VERSION ""

NS_ :

BS_:

BU_: WPC2 PSB SHVU_RR vHS_B2 FCS EMCU SLB GW_APSU GW_DLBCU RCM ARS CGW_CCU vDummy_HS_B GW_RLPSU ATS RLHV SGU PFSU GW_RRPSU ALBCU DSAU SWRC SHVU_FR RCS GW_DPSU BLTN_CAM SCM OHCL RWPC RRHV WPC HOD ASAU

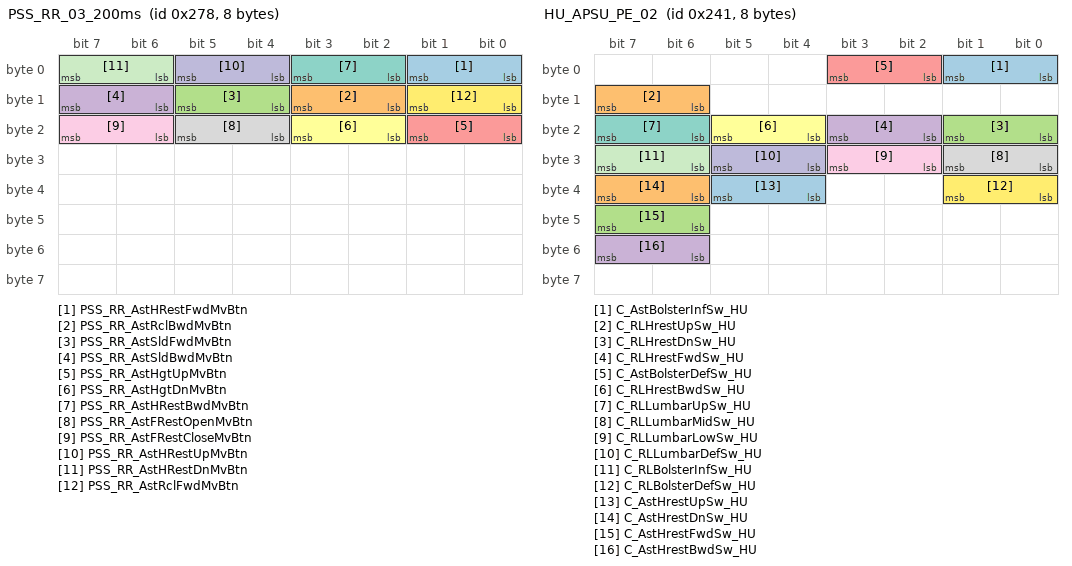
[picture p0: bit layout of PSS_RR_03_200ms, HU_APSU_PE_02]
BO_ 632 PSS_RR_03_200ms: 8 GW_RRPSU
 SG_ PSS_RR_AstHRestFwdMvBtn : 0|2@1+ (1,0) [0|0] ""  CGW_CCU
 SG_ PSS_RR_AstRclBwdMvBtn : 10|2@1+ (1,0) [0|0] ""  CGW_CCU
 SG_ PSS_RR_AstSldFwdMvBtn : 12|2@1+ (1,0) [0|0] ""  CGW_CCU
 SG_ PSS_RR_AstSldBwdMvBtn : 14|2@1+ (1,0) [0|0] ""  CGW_CCU
 SG_ PSS_RR_AstHgtUpMvBtn : 16|2@1+ (1,0) [0|0] ""  CGW_CCU
 SG_ PSS_RR_AstHgtDnMvBtn : 18|2@1+ (1,0) [0|0] ""  CGW_CCU
 SG_ PSS_RR_AstHRestBwdMvBtn : 2|2@1+ (1,0) [0|0] ""  CGW_CCU
 SG_ PSS_RR_AstFRestOpenMvBtn : 20|2@1+ (1,0) [0|0] ""  CGW_CCU
 SG_ PSS_RR_AstFRestCloseMvBtn : 22|2@1+ (1,0) [0|0] ""  CGW_CCU
 SG_ PSS_RR_AstHRestUpMvBtn : 4|2@1+ (1,0) [0|0] ""  CGW_CCU
 SG_ PSS_RR_AstHRestDnMvBtn : 6|2@1+ (1,0) [0|0] ""  CGW_CCU
 SG_ PSS_RR_AstRclFwdMvBtn : 8|2@1+ (1,0) [0|0] ""  CGW_CCU

BO_ 639 ATS_04_00ms: 8 ATS
 SG_ ATS_RRSeatHeaterSW : 0|2@1+ (1,0) [0|0] ""  RRHV,SHVU_RR
 SG_ ATS_RLSeatHeaterUpSW : 10|2@1+ (1,0) [0|0] ""  RLHV,SHVU_RR
 SG_ ATS_RRSeatVentDownSW : 12|2@1+ (1,0) [0|0] ""  RRHV,SHVU_RR
 SG_ ATS_RLSeatVentDownSW : 14|2@1+ (1,0) [0|0] ""  RLHV,SHVU_RR
 SG_ ATS_RLMemoryRestBtn : 16|2@1+ (1,0) [0|0] ""  Vector__XXX
 SG_ ATS_RLMemoryReturnBtn : 18|2@1+ (1,0) [0|0] ""  Vector__XXX
 SG_ ATS_RLSeatHeaterSW : 2|2@1+ (1,0) [0|0] ""  RLHV,SHVU_RR
 SG_ ATS_RRMemoryRestBtn : 20|2@1+ (1,0) [0|0] ""  Vector__XXX
 SG_ ATS_RRMemoryReturnBtn : 22|2@1+ (1,0) [0|0] ""  Vector__XXX
 SG_ ATS_RRMemoryAvWtcBtn : 24|2@1+ (1,0) [0|0] ""  Vector__XXX
 SG_ ATS_RRMemoryReadingBtn : 26|2@1+ (1,0) [0|0] ""  Vector__XXX
 SG_ ATS_RRRestModBtnSTD : 32|2@1+ (1,0) [0|0] ""  Vector__XXX
 SG_ ATS_RRResetModBtnSTD : 34|2@1+ (1,0) [0|0] ""  Vector__XXX
 SG_ ATS_RRAvWtcModBtnSTD : 36|2@1+ (1,0) [0|0] ""  Vector__XXX
 SG_ ATS_RRReadingModBtnSTD : 38|2@1+ (1,0) [0|0] ""  Vector__XXX
 SG_ ATS_RRSeatVentSW : 4|2@1+ (1,0) [0|0] ""  RRHV,SHVU_RR
 SG_ ATS_RLRestModBtnSTD : 40|2@1+ (1,0) [0|0] ""  Vector__XXX
 SG_ ATS_RLResetModBtnSTD : 42|2@1+ (1,0) [0|0] ""  Vector__XXX
 SG_ ATS_RRModestateStopBtn : 44|2@1+ (1,0) [0|0] ""  Vector__XXX
 SG_ ATS_RLModestateStopBtn : 46|2@1+ (1,0) [0|0] ""  Vector__XXX
 SG_ ATS_RLResetRestBtn : 48|2@1+ (1,0) [0|0] ""  Vector__XXX
 SG_ ATS_RLResetReturnBtn : 50|2@1+ (1,0) [0|0] ""  Vector__XXX
 SG_ ATS_RRResetRestBtn : 52|2@1+ (1,0) [0|0] ""  Vector__XXX
 SG_ ATS_RRResetReturnBtn : 54|2@1+ (1,0) [0|0] ""  Vector__XXX
 SG_ ATS_RRResetAvWtcBtn : 56|2@1+ (1,0) [0|0] ""  Vector__XXX
 SG_ ATS_RRResetReadingBtn : 58|2@1+ (1,0) [0|0] ""  Vector__XXX
 SG_ ATS_RLSeatVentSW : 6|2@1+ (1,0) [0|0] ""  RLHV,SHVU_RR
 SG_ ATS_RRSeatHeaterUpSW : 8|2@1+ (1,0) [0|0] ""  RRHV,SHVU_RR

BO_ 1584 HU_AMP_E_01: 8 CGW_CCU
 SG_ AMP_NaviWarnSound : 0|2@1+ (1,0) [0|0] ""  Vector__XXX
 SG_ AMP_Beep1Mode : 14|2@1+ (1,0) [0|0] ""  ATS
 SG_ AMP_MasterBeepVolumeStep : 16|3@1+ (1,0) [0|0] ""  Vector__XXX
 SG_ AMP_RrTTSSound : 2|2@1+ (1,0) [0|0] ""  Vector__XXX
 SG_ AMP_ASDMode : 21|3@1+ (1,0) [0|0] ""  Vector__XXX
 SG_ AMP_ANCMode : 25|2@1+ (1,0) [0|0] ""  Vector__XXX
 SG_ AMP_VirtualVenueMode : 32|3@1+ (1,0) [0|0] ""  Vector__XXX
 SG_ AMP_QLIMode : 35|3@1+ (1,0) [0|0] ""  Vector__XXX
 SG_ AMP_DriverMode : 38|2@1+ (1,0) [0|0] ""  Vector__XXX
 SG_ AMP_NaviSound : 4|2@1+ (1,0) [0|0] ""  Vector__XXX
 SG_ AMP_ETCSSound : 42|2@1+ (1,0) [0|0] ""  Vector__XXX
 SG_ AMP_VoiceGuideTTS : 44|2@1+ (1,0) [0|0] ""  Vector__XXX
 SG_ AMP_Beep1KBDMode : 46|2@1+ (1,0) [0|0] ""  Vector__XXX
 SG_ AMP_ETCSVolumeStep : 48|8@1+ (1,0) [0|0] ""  Vector__XXX
 SG_ AMP_NaviWarnVolumeStep : 56|8@1+ (1,0) [0|0] ""  Vector__XXX
 SG_ AMP_TTSSound : 6|2@1+ (1,0) [0|0] ""  Vector__XXX
 SG_ AMP_SDVCStep : 9|3@1+ (1,0) [0|0] ""  Vector__XXX

BO_ 577 HU_APSU_PE_02: 8 CGW_CCU
 SG_ C_AstBolsterInfSw_HU : 0|2@1+ (1,0) [0|0] ""  ALBCU,ASAU,GW_APSU
 SG_ C_RLHrestUpSw_HU : 14|2@1+ (1,0) [0|0] ""  GW_APSU,GW_RLPSU
 SG_ C_RLHrestDnSw_HU : 16|2@1+ (1,0) [0|0] ""  GW_APSU,GW_RLPSU
 SG_ C_RLHrestFwdSw_HU : 18|2@1+ (1,0) [0|0] ""  GW_APSU,GW_RLPSU
 SG_ C_AstBolsterDefSw_HU : 2|2@1+ (1,0) [0|0] ""  ALBCU,ASAU,GW_APSU
 SG_ C_RLHrestBwdSw_HU : 20|2@1+ (1,0) [0|0] ""  GW_APSU,GW_RLPSU
 SG_ C_RLLumbarUpSw_HU : 22|2@1+ (1,0) [0|0] ""  GW_RLPSU
 SG_ C_RLLumbarMidSw_HU : 24|2@1+ (1,0) [0|0] ""  GW_RLPSU
 SG_ C_RLLumbarLowSw_HU : 26|2@1+ (1,0) [0|0] ""  GW_RLPSU
 SG_ C_RLLumbarDefSw_HU : 28|2@1+ (1,0) [0|0] ""  GW_RLPSU
 SG_ C_RLBolsterInfSw_HU : 30|2@1+ (1,0) [0|0] ""  GW_RLPSU
 SG_ C_RLBolsterDefSw_HU : 32|2@1+ (1,0) [0|0] ""  GW_RLPSU
 SG_ C_AstHrestUpSw_HU : 36|2@1+ (1,0) [0|0] ""  GW_APSU
 SG_ C_AstHrestDnSw_HU : 38|2@1+ (1,0) [0|0] ""  GW_APSU
 SG_ C_AstHrestFwdSw_HU : 46|2@1+ (1,0) [0|0] ""  GW_APSU
 SG_ C_AstHrestBwdSw_HU : 54|2@1+ (1,0) [0|0] ""  GW_APSU

BO_ 578 HU_APSU_PE_03: 8 CGW_CCU
 SG_ C_RRLegSupFwdSw_HU : 0|2@1+ (1,0) [0|0] ""  GW_APSU,GW_RRPSU
 SG_ C_RRHrestDnSw_HU : 10|2@1+ (1,0) [0|0] ""  GW_APSU,GW_RRPSU
 SG_ C_RRHrestFwdSw_HU : 12|2@1+ (1,0) [0|0] ""  GW_APSU,GW_RRPSU
 SG_ C_RRHrestBwdSw_HU : 14|2@1+ (1,0) [0|0] ""  GW_APSU,GW_RRPSU
 SG_ C_RRLumbarUpSw_HU : 16|2@1+ (1,0) [0|0] ""  GW_APSU,GW_RRPSU
 SG_ C_RRLumbarMidSw_HU : 18|2@1+ (1,0) [0|0] ""  GW_APSU,GW_RRPSU
 SG_ C_RRLegSupBwdSw_HU : 2|2@1+ (1,0) [0|0] ""  GW_APSU,GW_RRPSU
 SG_ C_RRLumbarLowSw_HU : 20|2@1+ (1,0) [0|0] ""  GW_APSU,GW_RRPSU
 SG_ C_RRLumbarDefSw_HU : 22|2@1+ (1,0) [0|0] ""  GW_APSU,GW_RRPSU
 SG_ C_RRBolsterInfSw_HU : 24|2@1+ (1,0) [0|0] ""  GW_APSU,GW_RRPSU
 SG_ C_RRLegSupUpSw_HU : 4|2@1+ (1,0) [0|0] ""  GW_APSU,GW_RRPSU
 SG_ C_RROneTchNValueSet : 40|3@1+ (1,0) [0|0] ""  ATS,GW_APSU,GW_RRPSU
 SG_ C_RLOneTchNValueSet : 43|3@1+ (1,0) [0|0] ""  ATS,GW_APSU,GW_RLPSU,GW_RRPSU
 SG_ C_RRBolsterDefSw_HU : 46|2@1+ (1,0) [0|0] ""  GW_APSU,GW_RRPSU
 SG_ C_AstRlxTiltUpSw_HU : 50|2@1+ (1,0) [0|0] ""  GW_APSU
 SG_ C_AstRlxTiltDnSw_HU : 52|2@1+ (1,0) [0|0] ""  GW_APSU
 SG_ C_RLRSEUpSw_HU : 54|2@1+ (1,0) [0|0] ""  GW_APSU,GW_RLPSU
 SG_ C_RLRSEDnSw_HU : 56|2@1+ (1,0) [0|0] ""  GW_APSU,GW_RLPSU
 SG_ C_RRRSEUpSw_HU : 58|2@1+ (1,0) [0|0] ""  GW_APSU,GW_RRPSU
 SG_ C_RRLegSupDnSw_HU : 6|2@1+ (1,0) [0|0] ""  GW_APSU,GW_RRPSU
 SG_ C_RRRSEDnSw_HU : 60|2@1+ (1,0) [0|0] ""  GW_APSU,GW_RRPSU
 SG_ C_RRHrestUpSw_HU : 8|2@1+ (1,0) [0|0] ""  GW_APSU,GW_RRPSU

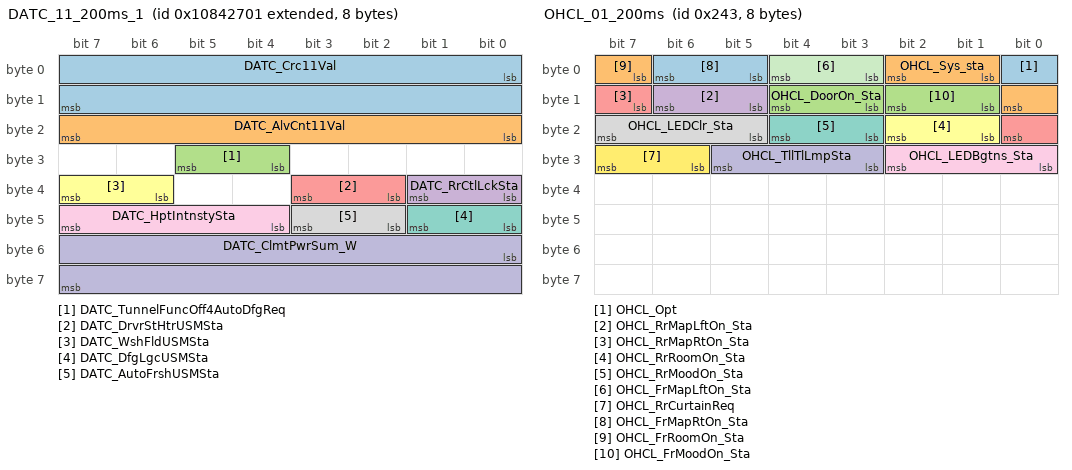
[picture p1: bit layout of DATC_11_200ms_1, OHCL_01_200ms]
BO_ 2424579841 DATC_11_200ms_1: 8 CGW_CCU
 SG_ DATC_Crc11Val : 0|16@1+ (1,0) [0|0] ""  Vector__XXX
 SG_ DATC_AlvCnt11Val : 16|8@1+ (1,0) [0|0] ""  Vector__XXX
 SG_ DATC_TunnelFuncOff4AutoDfgReq : 28|2@1+ (1,0) [0|0] ""  Vector__XXX
 SG_ DATC_RrCtlLckSta : 32|2@1+ (1,0) [0|0] ""  ATS
 SG_ DATC_DrvrStHtrUSMSta : 34|2@1+ (1,0) [0|0] ""  GW_APSU,GW_DPSU
 SG_ DATC_WshFldUSMSta : 38|2@1+ (1,0) [0|0] ""  Vector__XXX
 SG_ DATC_DfgLgcUSMSta : 40|2@1+ (1,0) [0|0] ""  Vector__XXX
 SG_ DATC_AutoFrshUSMSta : 42|2@1+ (1,0) [0|0] ""  Vector__XXX
 SG_ DATC_HptIntnstySta : 44|4@1+ (1,0) [0|0] ""  Vector__XXX
 SG_ DATC_ClmtPwrSum_W : 48|16@1+ (1,0) [0|0] "Wh"  Vector__XXX

BO_ 579 OHCL_01_200ms: 8 OHCL
 SG_ OHCL_Opt : 0|1@1+ (1,0) [0|0] ""  ATS
 SG_ OHCL_Sys_sta : 1|2@1+ (1,0) [0|0] ""  ATS
 SG_ OHCL_DoorOn_Sta : 11|2@1+ (1,0) [0|0] ""  ATS
 SG_ OHCL_RrMapLftOn_Sta : 13|2@1+ (1,0) [0|0] ""  ATS
 SG_ OHCL_RrMapRtOn_Sta : 15|2@1+ (1,0) [0|0] ""  ATS
 SG_ OHCL_RrRoomOn_Sta : 17|2@1+ (1,0) [0|0] ""  ATS
 SG_ OHCL_RrMoodOn_Sta : 19|2@1+ (1,0) [0|0] ""  ATS
 SG_ OHCL_LEDClr_Sta : 21|3@1+ (1,0) [0|0] ""  ATS
 SG_ OHCL_LEDBgtns_Sta : 24|3@1+ (1,0) [0|0] ""  ATS
 SG_ OHCL_TllTlLmpSta : 27|3@1+ (1,0) [0|0] ""  CGW_CCU
 SG_ OHCL_FrMapLftOn_Sta : 3|2@1+ (1,0) [0|0] ""  ATS
 SG_ OHCL_RrCurtainReq : 30|2@1+ (1,0) [0|0] ""  Vector__XXX
 SG_ OHCL_FrMapRtOn_Sta : 5|2@1+ (1,0) [0|0] ""  ATS
 SG_ OHCL_FrRoomOn_Sta : 7|2@1+ (1,0) [0|0] ""  ATS
 SG_ OHCL_FrMoodOn_Sta : 9|2@1+ (1,0) [0|0] ""  ATS

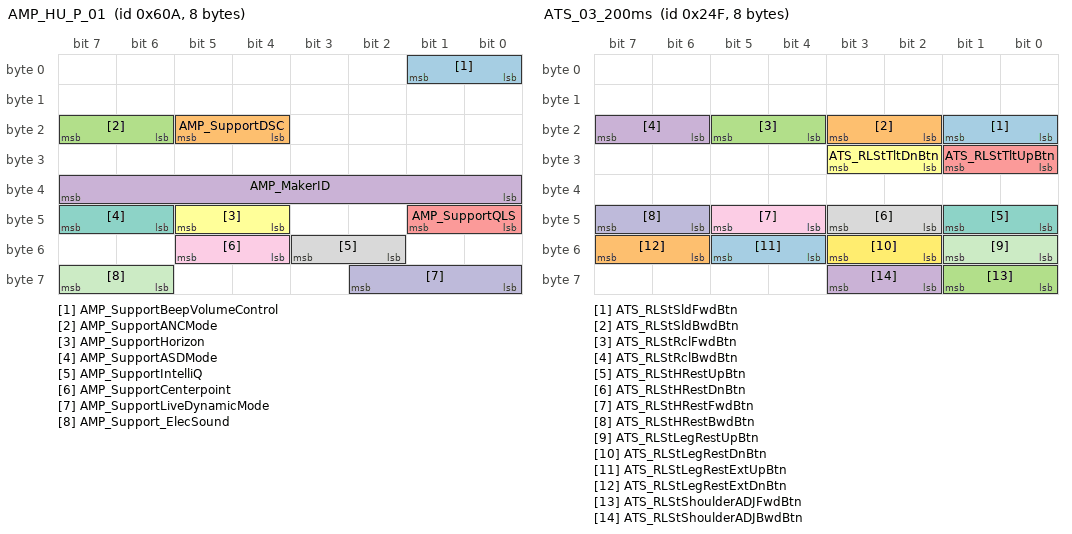
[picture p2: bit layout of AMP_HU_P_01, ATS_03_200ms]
BO_ 1546 AMP_HU_P_01: 8 CGW_CCU
 SG_ AMP_SupportBeepVolumeControl : 0|2@1+ (1,0) [0|0] ""  ATS
 SG_ AMP_SupportDSC : 20|2@1+ (1,0) [0|0] ""  Vector__XXX
 SG_ AMP_SupportANCMode : 22|2@1+ (1,0) [0|0] ""  Vector__XXX
 SG_ AMP_MakerID : 32|8@1+ (1,0) [0|0] ""  Vector__XXX
 SG_ AMP_SupportQLS : 40|2@1+ (1,0) [0|0] ""  Vector__XXX
 SG_ AMP_SupportHorizon : 44|2@1+ (1,0) [0|0] ""  Vector__XXX
 SG_ AMP_SupportASDMode : 46|2@1+ (1,0) [0|0] ""  Vector__XXX
 SG_ AMP_SupportIntelliQ : 50|2@1+ (1,0) [0|0] ""  Vector__XXX
 SG_ AMP_SupportCenterpoint : 52|2@1+ (1,0) [0|0] ""  Vector__XXX
 SG_ AMP_SupportLiveDynamicMode : 56|3@1+ (1,0) [0|0] ""  Vector__XXX
 SG_ AMP_Support_ElecSound : 62|2@1+ (1,0) [0|0] ""  Vector__XXX

BO_ 591 ATS_03_200ms: 8 ATS
 SG_ ATS_RLStSldFwdBtn : 16|2@1+ (1,0) [0|0] ""  Vector__XXX
 SG_ ATS_RLStSldBwdBtn : 18|2@1+ (1,0) [0|0] ""  Vector__XXX
 SG_ ATS_RLStRclFwdBtn : 20|2@1+ (1,0) [0|0] ""  Vector__XXX
 SG_ ATS_RLStRclBwdBtn : 22|2@1+ (1,0) [0|0] ""  Vector__XXX
 SG_ ATS_RLStTltUpBtn : 24|2@1+ (1,0) [0|0] ""  Vector__XXX
 SG_ ATS_RLStTltDnBtn : 26|2@1+ (1,0) [0|0] ""  Vector__XXX
 SG_ ATS_RLStHRestUpBtn : 40|2@1+ (1,0) [0|0] ""  Vector__XXX
 SG_ ATS_RLStHRestDnBtn : 42|2@1+ (1,0) [0|0] ""  Vector__XXX
 SG_ ATS_RLStHRestFwdBtn : 44|2@1+ (1,0) [0|0] ""  Vector__XXX
 SG_ ATS_RLStHRestBwdBtn : 46|2@1+ (1,0) [0|0] ""  Vector__XXX
 SG_ ATS_RLStLegRestUpBtn : 48|2@1+ (1,0) [0|0] ""  Vector__XXX
 SG_ ATS_RLStLegRestDnBtn : 50|2@1+ (1,0) [0|0] ""  Vector__XXX
 SG_ ATS_RLStLegRestExtUpBtn : 52|2@1+ (1,0) [0|0] ""  Vector__XXX
 SG_ ATS_RLStLegRestExtDnBtn : 54|2@1+ (1,0) [0|0] ""  Vector__XXX
 SG_ ATS_RLStShoulderADJFwdBtn : 56|2@1+ (1,0) [0|0] ""  Vector__XXX
 SG_ ATS_RLStShoulderADJBwdBtn : 58|2@1+ (1,0) [0|0] ""  Vector__XXX

BO_ 599 RRPSM_02_00ms: 8 GW_RRPSU
 SG_ RRIMS_AMPBzrReq : 14|2@1+ (1,0) [0|0] ""  CGW_CCU
 SG_ RRPSM_RearModeWngDis : 8|3@1+ (1,0) [0|0] ""  CGW_CCU

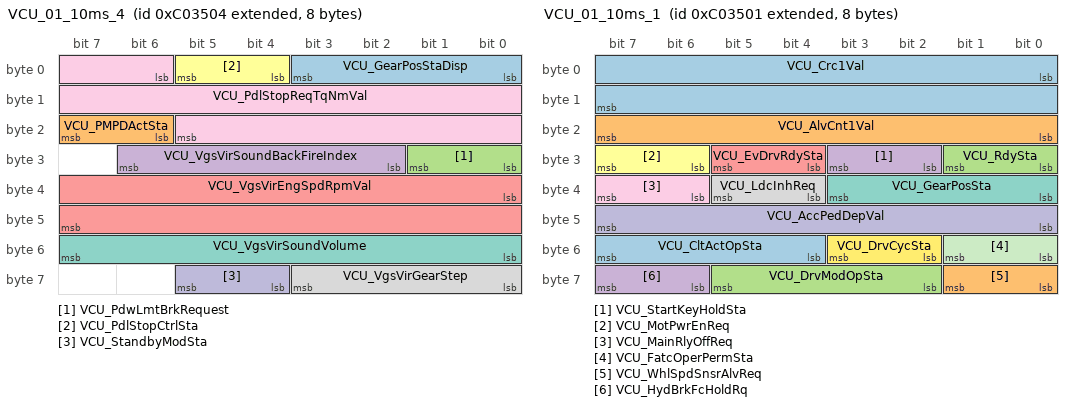
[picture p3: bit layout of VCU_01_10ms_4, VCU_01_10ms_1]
BO_ 2160080132 VCU_01_10ms_4: 8 CGW_CCU
 SG_ VCU_GearPosStaDisp : 0|4@1+ (1,0) [0|0] ""  BLTN_CAM,SWRC
 SG_ VCU_PMPDActSta : 22|2@1+ (1,0) [0|0] ""  Vector__XXX
 SG_ VCU_PdwLmtBrkRequest : 24|2@1+ (1,0) [0|0] ""  Vector__XXX
 SG_ VCU_VgsVirSoundBackFireIndex : 26|5@1+ (1,0) [0|0] ""  Vector__XXX
 SG_ VCU_VgsVirEngSpdRpmVal : 32|16@1- (1,0) [0|0] ""  Vector__XXX
 SG_ VCU_PdlStopCtrlSta : 4|2@1+ (1,0) [0|0] ""  Vector__XXX
 SG_ VCU_VgsVirSoundVolume : 48|8@1+ (0.392156863,0) [0|0] ""  Vector__XXX
 SG_ VCU_VgsVirGearStep : 56|4@1+ (1,0) [0|0] ""  Vector__XXX
 SG_ VCU_PdlStopReqTqNmVal : 6|16@1+ (1,0) [0|0] ""  Vector__XXX
 SG_ VCU_StandbyModSta : 60|2@1+ (1,0) [0|0] ""  Vector__XXX

BO_ 2160080129 VCU_01_10ms_1: 8 CGW_CCU
 SG_ VCU_Crc1Val : 0|16@1+ (1,0) [0|0] ""  Vector__XXX
 SG_ VCU_AlvCnt1Val : 16|8@1+ (1,0) [0|0] ""  Vector__XXX
 SG_ VCU_RdySta : 24|2@1+ (1,0) [0|3] ""  Vector__XXX
 SG_ VCU_StartKeyHoldSta : 26|2@1+ (1,0) [0|3] ""  Vector__XXX
 SG_ VCU_EvDrvRdySta : 28|2@1+ (1,0) [0|3] ""  ALBCU,BLTN_CAM,GW_APSU,GW_DLBCU,GW_DPSU,GW_RLPSU,GW_RRPSU,HOD,PFSU,PSB,RCM,RLHV,RRHV,RWPC,SCM,SHVU_FR,SHVU_RR,SWRC,WPC,WPC2
 SG_ VCU_MotPwrEnReq : 30|2@1+ (1,0) [0|3] ""  Vector__XXX
 SG_ VCU_GearPosSta : 32|4@1+ (1,0) [0|15] ""  BLTN_CAM,GW_APSU,GW_DPSU,GW_RLPSU,GW_RRPSU,PFSU,SGU,WPC2
 SG_ VCU_LdcInhReq : 36|2@1+ (1,0) [0|3] ""  ALBCU,GW_APSU,GW_DLBCU,GW_DPSU,GW_RLPSU,GW_RRPSU,RLHV,RRHV,SHVU_FR,SHVU_RR
 SG_ VCU_MainRlyOffReq : 38|2@1+ (1,0) [0|3] ""  Vector__XXX
 SG_ VCU_AccPedDepVal : 40|8@1+ (0.3921568627,0) [0|100] "%"  BLTN_CAM
 SG_ VCU_FatcOperPermSta : 48|2@1+ (1,0) [0|3] ""  Vector__XXX
 SG_ VCU_DrvCycSta : 50|2@1+ (1,0) [0|3] ""  Vector__XXX
 SG_ VCU_CltActOpSta : 52|4@1+ (1,0) [0|15] ""  Vector__XXX
 SG_ VCU_WhlSpdSnsrAlvReq : 56|2@1+ (1,0) [0|0] "flag"  Vector__XXX
 SG_ VCU_DrvModOpSta : 58|4@1+ (1,0) [0|0] ""  Vector__XXX
 SG_ VCU_HydBrkFcHoldRq : 62|2@1+ (1,0) [0|0] ""  Vector__XXX

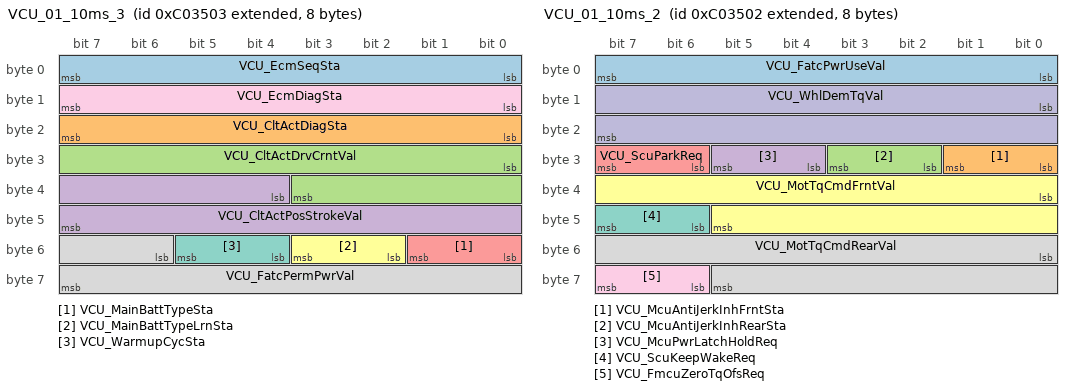
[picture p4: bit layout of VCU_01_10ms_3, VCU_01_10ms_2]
BO_ 2160080131 VCU_01_10ms_3: 8 CGW_CCU
 SG_ VCU_EcmSeqSta : 0|8@1+ (1,0) [0|255] ""  Vector__XXX
 SG_ VCU_CltActDiagSta : 16|8@1+ (1,0) [0|255] ""  Vector__XXX
 SG_ VCU_CltActDrvCrntVal : 24|12@1- (0.025,0) [-51.2|51.175] "A"  Vector__XXX
 SG_ VCU_CltActPosStrokeVal : 36|12@1- (0.0125,0) [-25.6|25.5875] "mm"  Vector__XXX
 SG_ VCU_MainBattTypeSta : 48|2@1+ (1,0) [0|3] ""  Vector__XXX
 SG_ VCU_MainBattTypeLrnSta : 50|2@1+ (1,0) [0|3] ""  Vector__XXX
 SG_ VCU_WarmupCycSta : 52|2@1+ (1,0) [0|3] ""  Vector__XXX
 SG_ VCU_FatcPermPwrVal : 54|10@1+ (20,0) [0|12700] "W"  Vector__XXX
 SG_ VCU_EcmDiagSta : 8|8@1+ (1,0) [0|255] ""  Vector__XXX

BO_ 607 ATS_04_200ms: 8 ATS
 SG_ ATS_RRStSldFwdBtn : 16|2@1+ (1,0) [0|0] ""  Vector__XXX
 SG_ ATS_RRStSldBwdBtn : 18|2@1+ (1,0) [0|0] ""  Vector__XXX
 SG_ ATS_RRStRclFwdBtn : 20|2@1+ (1,0) [0|0] ""  Vector__XXX
 SG_ ATS_RRStRclBwdBtn : 22|2@1+ (1,0) [0|0] ""  Vector__XXX
 SG_ ATS_RRStTltUpBtn : 24|2@1+ (1,0) [0|0] ""  Vector__XXX
 SG_ ATS_RRStTltDnBtn : 26|2@1+ (1,0) [0|0] ""  Vector__XXX
 SG_ ATS_RRStLegRestPopBtn : 32|2@1+ (1,0) [0|0] ""  Vector__XXX
 SG_ ATS_RRStFRestPopBtn : 34|2@1+ (1,0) [0|0] ""  Vector__XXX
 SG_ ATS_RRStAstPopBtn : 36|2@1+ (1,0) [0|0] ""  Vector__XXX
 SG_ ATS_RRFauCondiBtn : 38|2@1+ (1,0) [0|0] ""  Vector__XXX
 SG_ ATS_RRStHRestUpBtn : 40|2@1+ (1,0) [0|0] ""  Vector__XXX
 SG_ ATS_RRStHRestDnBtn : 42|2@1+ (1,0) [0|0] ""  Vector__XXX
 SG_ ATS_RRStHRestFwdBtn : 44|2@1+ (1,0) [0|0] ""  Vector__XXX
 SG_ ATS_RRStHRestBwdBtn : 46|2@1+ (1,0) [0|0] ""  Vector__XXX
 SG_ ATS_RRStShoulderADJFwdBtn : 48|2@1+ (1,0) [0|0] ""  Vector__XXX
 SG_ ATS_RRStShoulderADJBwdBtn : 50|2@1+ (1,0) [0|0] ""  Vector__XXX
 SG_ ATS_RRStLegRestUpBtn : 56|2@1+ (1,0) [0|0] ""  Vector__XXX
 SG_ ATS_RRStLegRestDnBtn : 58|2@1+ (1,0) [0|0] ""  Vector__XXX
 SG_ ATS_RRStLegRestExtUpBtn : 60|2@1+ (1,0) [0|0] ""  Vector__XXX
 SG_ ATS_RRStLegRestExtDnBtn : 62|2@1+ (1,0) [0|0] ""  Vector__XXX

BO_ 2160080130 VCU_01_10ms_2: 8 CGW_CCU
 SG_ VCU_FatcPwrUseVal : 0|8@1+ (10,0) [0|2550] "W"  Vector__XXX
 SG_ VCU_McuAntiJerkInhFrntSta : 24|2@1+ (1,0) [0|3] ""  Vector__XXX
 SG_ VCU_McuAntiJerkInhRearSta : 26|2@1+ (1,0) [0|3] ""  Vector__XXX
 SG_ VCU_McuPwrLatchHoldReq : 28|2@1+ (1,0) [0|0] ""  Vector__XXX
 SG_ VCU_ScuParkReq : 30|2@1+ (1,0) [0|0] "flag"  Vector__XXX
 SG_ VCU_MotTqCmdFrntVal : 32|14@1- (0.125,0) [-1024|1023.875] "Nm"  Vector__XXX
 SG_ VCU_ScuKeepWakeReq : 46|2@1+ (1,0) [0|0] "flag"  Vector__XXX
 SG_ VCU_MotTqCmdRearVal : 48|14@1- (0.125,0) [-1024|1023.875] "Nm"  Vector__XXX
 SG_ VCU_FmcuZeroTqOfsReq : 62|2@1+ (1,0) [0|0] "flag"  Vector__XXX
 SG_ VCU_WhlDemTqVal : 8|16@1- (1,0) [-32768|32767] "Nm"  Vector__XXX

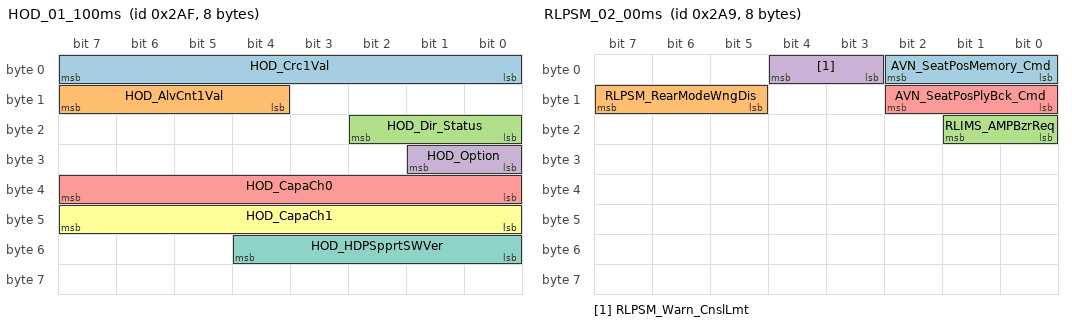
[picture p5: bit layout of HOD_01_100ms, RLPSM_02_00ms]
BO_ 687 HOD_01_100ms: 8 HOD
 SG_ HOD_Crc1Val : 0|8@1+ (1,0) [0|0] ""  CGW_CCU
 SG_ HOD_AlvCnt1Val : 12|4@1+ (1,0) [0|0] ""  CGW_CCU
 SG_ HOD_Dir_Status : 16|3@1+ (1,0) [0|0] ""  CGW_CCU
 SG_ HOD_Option : 24|2@1+ (1,0) [0|0] ""  CGW_CCU
 SG_ HOD_CapaCh0 : 32|8@1+ (1,0) [0|0] ""  CGW_CCU
 SG_ HOD_CapaCh1 : 40|8@1+ (1,0) [0|0] ""  CGW_CCU
 SG_ HOD_HDPSpprtSWVer : 48|5@1+ (1,0) [0|0] ""  CGW_CCU

BO_ 681 RLPSM_02_00ms: 8 GW_RLPSU
 SG_ AVN_SeatPosMemory_Cmd : 0|3@1+ (1,0) [0|0] ""  CGW_CCU,GW_APSU,GW_DPSU,GW_RRPSU
 SG_ RLPSM_RearModeWngDis : 13|3@1+ (1,0) [0|0] ""  CGW_CCU
 SG_ RLIMS_AMPBzrReq : 16|2@1+ (1,0) [0|0] ""  CGW_CCU
 SG_ RLPSM_Warn_CnslLmt : 3|2@1+ (1,0) [0|0] ""  CGW_CCU
 SG_ AVN_SeatPosPlyBck_Cmd : 8|3@1+ (1,0) [0|0] ""  GW_APSU,GW_DPSU,GW_RRPSU

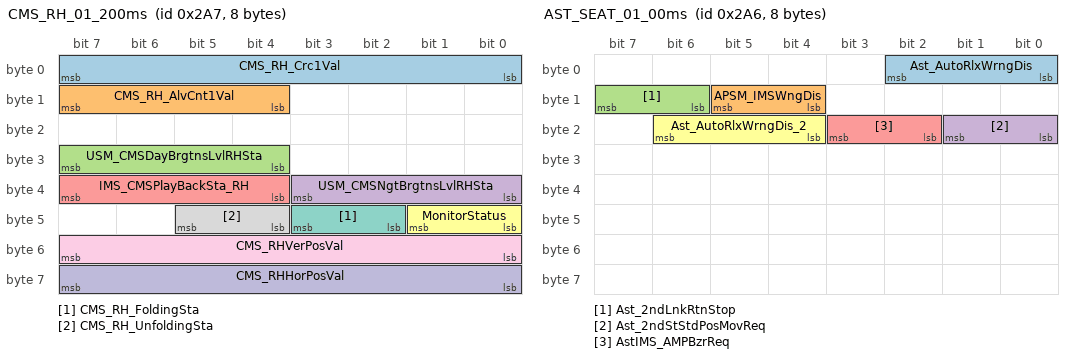
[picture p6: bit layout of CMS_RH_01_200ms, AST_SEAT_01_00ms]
BO_ 679 CMS_RH_01_200ms: 8 CGW_CCU
 SG_ CMS_RH_Crc1Val : 0|8@1+ (1,0) [0|0] ""  Vector__XXX
 SG_ CMS_RH_AlvCnt1Val : 12|4@1+ (1,0) [0|0] ""  Vector__XXX
 SG_ USM_CMSDayBrgtnsLvlRHSta : 28|4@1+ (1,0) [0|0] ""  Vector__XXX
 SG_ USM_CMSNgtBrgtnsLvlRHSta : 32|4@1+ (1,0) [0|0] ""  Vector__XXX
 SG_ IMS_CMSPlayBackSta_RH : 36|4@1+ (1,0) [0|0] ""  GW_DPSU
 SG_ MonitorStatus : 40|2@1+ (1,0) [0|0] ""  Vector__XXX
 SG_ CMS_RH_FoldingSta : 42|2@1+ (1,0) [0|0] ""  Vector__XXX
 SG_ CMS_RH_UnfoldingSta : 44|2@1+ (1,0) [0|0] ""  Vector__XXX
 SG_ CMS_RHVerPosVal : 48|8@1+ (0.02,0) [0|0] "V"  Vector__XXX
 SG_ CMS_RHHorPosVal : 56|8@1+ (0.02,0) [0|0] "V"  Vector__XXX

BO_ 678 AST_SEAT_01_00ms: 8 GW_APSU
 SG_ Ast_AutoRlxWrngDis : 0|3@1+ (1,0) [0|0] ""  CGW_CCU
 SG_ APSM_IMSWngDis : 12|2@1+ (1,0) [0|0] ""  Vector__XXX
 SG_ Ast_2ndLnkRtnStop : 14|2@1+ (1,0) [0|0] ""  GW_RLPSU,GW_RRPSU
 SG_ Ast_2ndStStdPosMovReq : 16|2@1+ (1,0) [0|0] ""  GW_RLPSU,GW_RRPSU
 SG_ AstIMS_AMPBzrReq : 18|2@1+ (1,0) [0|0] ""  CGW_CCU
 SG_ Ast_AutoRlxWrngDis_2 : 20|3@1+ (1,0) [0|0] ""  CGW_CCU

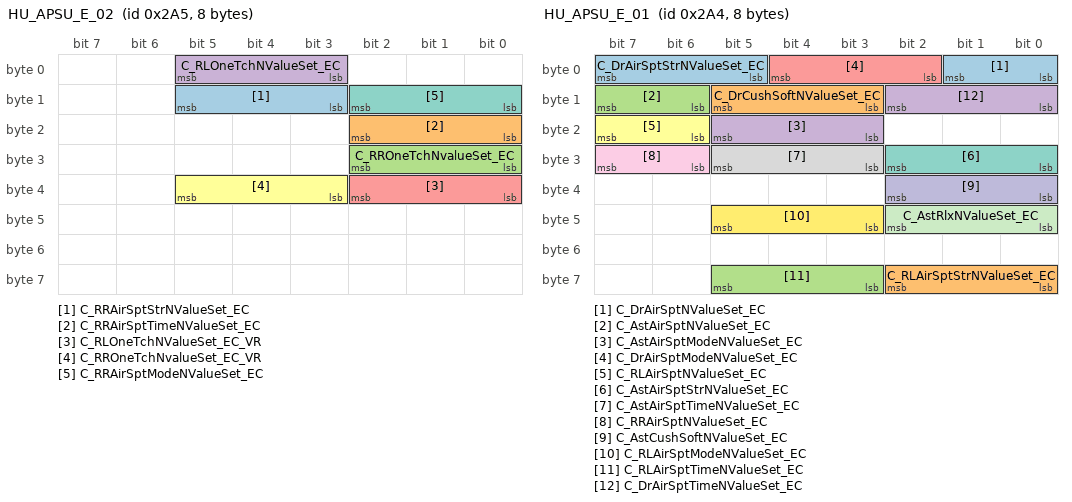
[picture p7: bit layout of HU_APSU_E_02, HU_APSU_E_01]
BO_ 677 HU_APSU_E_02: 8 CGW_CCU
 SG_ C_RRAirSptStrNValueSet_EC : 11|3@1+ (1,0) [0|0] ""  ATS,GW_RRPSU
 SG_ C_RRAirSptTimeNValueSet_EC : 16|3@1+ (1,0) [0|0] ""  ATS,GW_RRPSU
 SG_ C_RROneTchNvalueSet_EC : 24|3@1+ (1,0) [0|0] ""  ATS,GW_APSU,GW_RRPSU
 SG_ C_RLOneTchNValueSet_EC : 3|3@1+ (1,0) [0|0] ""  ATS,GW_RLPSU,GW_RRPSU
 SG_ C_RLOneTchNValueSet_EC_VR : 32|3@1+ (1,0) [0|0] ""  GW_RLPSU
 SG_ C_RROneTchNvalueSet_EC_VR : 35|3@1+ (1,0) [0|0] ""  GW_RRPSU
 SG_ C_RRAirSptModeNValueSet_EC : 8|3@1+ (1,0) [0|0] ""  ATS,GW_RRPSU

BO_ 676 HU_APSU_E_01: 8 CGW_CCU
 SG_ C_DrAirSptNValueSet_EC : 0|2@1+ (1,0) [0|0] ""  DSAU,GW_DPSU
 SG_ C_DrCushSoftNValueSet_EC : 11|3@1+ (1,0) [0|0] ""  DSAU,GW_DPSU
 SG_ C_AstAirSptNValueSet_EC : 14|2@1+ (1,0) [0|0] ""  ASAU,GW_APSU
 SG_ C_AstAirSptModeNValueSet_EC : 19|3@1+ (1,0) [0|0] ""  ASAU,GW_APSU
 SG_ C_DrAirSptModeNValueSet_EC : 2|3@1+ (1,0) [0|0] ""  DSAU,GW_DPSU
 SG_ C_RLAirSptNValueSet_EC : 22|2@1+ (1,0) [0|0] ""  ATS,GW_RLPSU
 SG_ C_AstAirSptStrNValueSet_EC : 24|3@1+ (1,0) [0|0] ""  ASAU,GW_APSU
 SG_ C_AstAirSptTimeNValueSet_EC : 27|3@1+ (1,0) [0|0] ""  ASAU,GW_APSU
 SG_ C_RRAirSptNValueSet_EC : 30|2@1+ (1,0) [0|0] ""  ATS,GW_RRPSU
 SG_ C_AstCushSoftNValueSet_EC : 32|3@1+ (1,0) [0|0] ""  ASAU,GW_APSU
 SG_ C_AstRlxNValueSet_EC : 40|3@1+ (1,0) [0|0] ""  GW_APSU
 SG_ C_RLAirSptModeNValueSet_EC : 43|3@1+ (1,0) [0|0] ""  ATS,GW_RLPSU
 SG_ C_DrAirSptStrNValueSet_EC : 5|3@1+ (1,0) [0|0] ""  DSAU,GW_DPSU
 SG_ C_RLAirSptStrNValueSet_EC : 56|3@1+ (1,0) [0|0] ""  ATS,GW_RLPSU
 SG_ C_RLAirSptTimeNValueSet_EC : 59|3@1+ (1,0) [0|0] ""  ATS,GW_RLPSU
 SG_ C_DrAirSptTimeNValueSet_EC : 8|3@1+ (1,0) [0|0] ""  DSAU,GW_DPSU

BO_ 675 HU_USM_E_11: 8 CGW_CCU
 SG_ Usm_RpmMUDSet : 1|2@1+ (1,0) [0|0] ""  Vector__XXX
 SG_ CF_AVN_HtBlcRLNValueSet : 11|4@1+ (1,0) [0|0] ""  GW_RLPSU,GW_RRPSU,RLHV,SHVU_FR,SHVU_RR
 SG_ CF_AVN_BRAKE_PedalfeelNValueSet2 : 15|3@1+ (1,0) [0|0] ""  Vector__XXX
 SG_ CF_AVN_ISLA_AutoNModSet : 18|2@1+ (1,0) [0|0] ""  Vector__XXX
 SG_ CF_AVN_HtBlcRRNValueSet : 20|4@1+ (1,0) [0|0] ""  GW_RLPSU,GW_RRPSU,RRHV,SHVU_FR,SHVU_RR
 SG_ LapTimer_AutoMeasure_Setting : 24|2@1+ (1,0) [0|0] ""  Vector__XXX
 SG_ LapTimer_TimeGap_Setting : 26|2@1+ (1,0) [0|0] ""  Vector__XXX
 SG_ Usm_RpmSANDSet : 3|2@1+ (1,0) [0|0] ""  Vector__XXX
 SG_ CF_AVN_RemoteWDWNValueSet : 30|2@1+ (1,0) [0|0] ""  Vector__XXX
 SG_ USM_TowWeight_Set : 32|4@1+ (1,0) [0|0] ""  Vector__XXX
 SG_ CF_AVN_SportHUD2 : 38|2@1+ (1,0) [0|0] ""  Vector__XXX
 SG_ C_SLB_SmartCtrl_Set_Nvalue : 44|4@1+ (1,0) [0|0] ""  GW_DLBCU,SLB
 SG_ HU_CustomNewMenuSet : 5|4@1+ (1,0) [0|0] ""  Vector__XXX
 SG_ USM_RpmComfortRearSet : 57|2@1+ (1,0) [0|0] ""  Vector__XXX
 SG_ Usm_RpmMyDriveModeSet : 59|2@1+ (1,0) [0|0] ""  Vector__XXX
 SG_ LapTimer_MeasuringStatus_HU : 61|3@1+ (1,0) [0|0] ""  Vector__XXX
 SG_ CF_AVN_PCA_RrEquipNvalueSet : 9|2@1+ (1,0) [0|0] ""  Vector__XXX

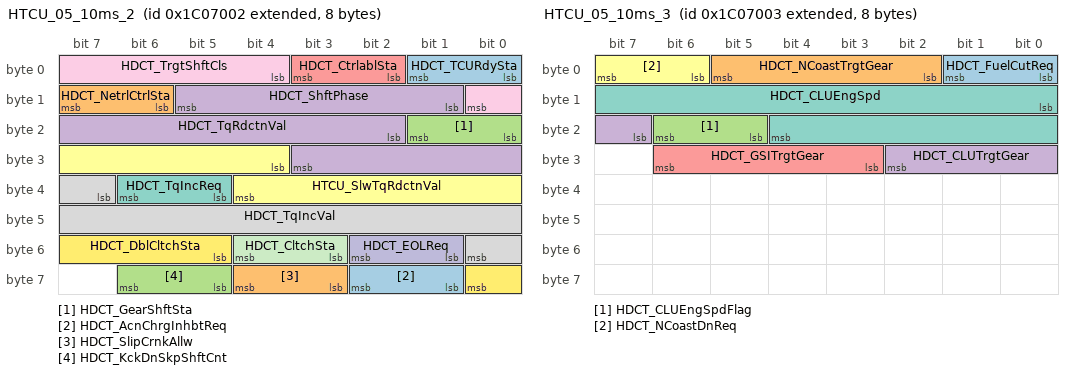
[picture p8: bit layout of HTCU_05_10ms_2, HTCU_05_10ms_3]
BO_ 2176872450 HTCU_05_10ms_2: 8 CGW_CCU
 SG_ HDCT_TCURdySta : 0|2@1+ (1,0) [0|0] ""  Vector__XXX
 SG_ HDCT_NetrlCtrlSta : 14|2@1+ (1,0) [0|0] ""  Vector__XXX
 SG_ HDCT_GearShftSta : 16|2@1+ (1,0) [0|0] ""  Vector__XXX
 SG_ HDCT_TqRdctnVal : 18|10@1+ (0.390625,-200) [0|0] "%"  Vector__XXX
 SG_ HDCT_CtrlablSta : 2|2@1+ (1,0) [0|0] ""  Vector__XXX
 SG_ HTCU_SlwTqRdctnVal : 28|9@1+ (0.390625,0) [0|0] "%"  Vector__XXX
 SG_ HDCT_TqIncReq : 37|2@1+ (1,0) [0|0] ""  Vector__XXX
 SG_ HDCT_TqIncVal : 39|10@1+ (0.390625,-200) [0|0] "%"  Vector__XXX
 SG_ HDCT_TrgtShftCls : 4|5@1+ (1,0) [0|0] "flag"  Vector__XXX
 SG_ HDCT_EOLReq : 49|2@1+ (1,0) [0|0] ""  Vector__XXX
 SG_ HDCT_CltchSta : 51|2@1+ (1,0) [0|0] ""  Vector__XXX
 SG_ HDCT_DblCltchSta : 53|4@1+ (1,0) [0|0] ""  Vector__XXX
 SG_ HDCT_AcnChrgInhbtReq : 57|2@1+ (1,0) [0|0] ""  Vector__XXX
 SG_ HDCT_SlipCrnkAllw : 59|2@1+ (1,0) [0|0] ""  Vector__XXX
 SG_ HDCT_KckDnSkpShftCnt : 61|2@1+ (1,0) [0|0] ""  Vector__XXX
 SG_ HDCT_ShftPhase : 9|5@1+ (1,0) [0|0] ""  Vector__XXX

BO_ 2176872451 HTCU_05_10ms_3: 8 CGW_CCU
 SG_ HDCT_FuelCutReq : 0|2@1+ (1,0) [0|0] ""  Vector__XXX
 SG_ HDCT_NCoastTrgtGear : 2|4@1+ (1,0) [0|0] ""  Vector__XXX
 SG_ HDCT_CLUEngSpdFlag : 21|2@1+ (1,0) [0|0] ""  Vector__XXX
 SG_ HDCT_CLUTrgtGear : 23|4@1+ (1,0) [0|0] ""  Vector__XXX
 SG_ HDCT_GSITrgtGear : 27|4@1+ (1,0) [0|0] ""  Vector__XXX
 SG_ HDCT_NCoastDnReq : 6|2@1+ (1,0) [0|0] ""  Vector__XXX
 SG_ HDCT_CLUEngSpd : 8|13@1+ (0.9766,0) [0|0] ""  Vector__XXX

CM_ BO_ 1546 "[P] Periodic";
CM_ SG_ 1546 AMP_SupportBeepVolumeControl "Information for AMPsupport configurable Beep1
send 500msec after Booting up";
CM_ SG_ 1546 AMP_SupportDSC "Does amp support Dynamic Speed Compensation mode?";
CM_ SG_ 1546 AMP_SupportANCMode "Does AMP support ANC?";
CM_ SG_ 1546 AMP_MakerID "Information for AMP Maker
For model afrer 2014, use 0x01~0x03 only.
* Use Only 0x01~0x03 values after 2014 *";
CM_ SG_ 1546 AMP_SupportQLS "Information for amp support Quantum Logic Surround mode
Harman AMP Only";
CM_ SG_ 1546 AMP_SupportHorizon "Information for amp support Meridian Horizon mode Meridian AMP Only";
CM_ SG_ 1546 AMP_SupportASDMode "Information for  AMP support ASD (Active Sound Design, Virtual Engine Sound)";
CM_ SG_ 1546 AMP_SupportIntelliQ "Does amp support Meridian Intelli-Q mode?";
CM_ SG_ 1546 AMP_SupportCenterpoint "Does amp support CenterPoint mode?";
CM_ SG_ 1546 AMP_SupportLiveDynamicMode "Information for amp
 Support
 LiveDynamic mode";
CM_ SG_ 1546 AMP_Support_ElecSound "inform to H/U & CLU whether amp support premium electric sound or not";
CM_ BO_ 678 "[EC] On Event and On Change";
CM_ SG_ 678 Ast_AutoRlxWrngDis "Assist seat auto relax warning information for AVN Display";
CM_ SG_ 678 APSM_IMSWngDis "Ast IMS information";
CM_ SG_ 678 AstIMS_AMPBzrReq "SEAT IMS Buzzer Request for AMP";
CM_ SG_ 678 Ast_AutoRlxWrngDis_2 "Assist seat auto relax warning information for AVN Display";
CM_ BO_ 591 "[PE] Periodic and On Event";
CM_ SG_ 591 ATS_RLStSldFwdBtn "Rear Left Power Seat Slide Forward Touch Button";
CM_ SG_ 591 ATS_RLStSldBwdBtn "Rear Left Power Seat Slide Backward Touch Button";
CM_ SG_ 591 ATS_RLStRclFwdBtn "Rear Left Power Seat Recline Forward Touch Button";
CM_ SG_ 591 ATS_RLStRclBwdBtn "Rear Left Power Seat Recline Backward Touch Button";
CM_ SG_ 591 ATS_RLStTltUpBtn "Rear Left Power Seat Tilt Up Touch Button";
CM_ SG_ 591 ATS_RLStTltDnBtn "Rear Left Power Seat Tilt Down Touch Button";
CM_ SG_ 591 ATS_RLStHRestUpBtn "Rear Left Power Seat Head Rest Up Touch Button";
CM_ SG_ 591 ATS_RLStHRestDnBtn "Rear Left Power Seat Head Rest Down Touch Button";
CM_ SG_ 591 ATS_RLStHRestFwdBtn "Rear Left Power Seat Head Rest Forward Touch Button";
CM_ SG_ 591 ATS_RLStHRestBwdBtn "Rear Left Power Seat Head Rest Backward Touch Button";
CM_ SG_ 591 ATS_RLStLegRestUpBtn "Rear Left Power Seat Leg Rest Up Touch Button";
CM_ SG_ 591 ATS_RLStLegRestDnBtn "Rear Left Power Seat Leg Rest Down Touch Button";
CM_ SG_ 591 ATS_RLStLegRestExtUpBtn "Rear Left Power Seat Leg Rest Ext. Up Touch Button";
CM_ SG_ 591 ATS_RLStLegRestExtDnBtn "Rear Left Power Seat Leg Rest Ext. Down Touch Button";
CM_ SG_ 591 ATS_RLStShoulderADJFwdBtn "Rear Left Power Seat Shoulder Adjuster Forward Touch Button";
CM_ SG_ 591 ATS_RLStShoulderADJBwdBtn "Rear Left Power Seat Shoulder Adjuster Backward Touch Button";
CM_ BO_ 639 "[EC] On Event and On Change";
CM_ SG_ 639 ATS_RRSeatHeaterSW "ATS touch command for seat heat control (For Rear Right seat)";
CM_ SG_ 639 ATS_RLSeatHeaterUpSW "ATS touch command for seat heat control  (For Rear Left seat)";
CM_ SG_ 639 ATS_RRSeatVentDownSW "ATS touch command for seat Vent control (For Rear Right seat)";
CM_ SG_ 639 ATS_RLSeatVentDownSW "ATS touch command for seat Vent control (For Rear Left seat)";
CM_ SG_ 639 ATS_RLMemoryRestBtn "Rear Left Rest Mode Custom Save Button (Except North America)";
CM_ SG_ 639 ATS_RLMemoryReturnBtn "Rear Left Return Mode Custom Save Button (Except North America)";
CM_ SG_ 639 ATS_RLSeatHeaterSW "ATS touch command for seat heat control  (For Rear Left seat)";
CM_ SG_ 639 ATS_RRMemoryRestBtn "Rear Right Rest Mode Custom Save Button (Except North America)";
CM_ SG_ 639 ATS_RRMemoryReturnBtn "Rear Right Return Mode Custom Save Button (Except North America)";
CM_ SG_ 639 ATS_RRMemoryAvWtcBtn "Rear Right AV Watching Mode Custom Save Button (Except North America)";
CM_ SG_ 639 ATS_RRMemoryReadingBtn "Rear Right Reading Mode Custom Save Button (Except North America)";
CM_ SG_ 639 ATS_RRRestModBtnSTD "Rear Right Rest Mode Touch Button (EXCEPT North America)";
CM_ SG_ 639 ATS_RRResetModBtnSTD "Rear Right Return Mode Touch Button (EXCEPT North America)";
CM_ SG_ 639 ATS_RRAvWtcModBtnSTD "Rear Right AV Watching Mode Touch Button (EXCEPT North America)";
CM_ SG_ 639 ATS_RRReadingModBtnSTD "Rear Right Reading Mode Touch Button (EXCEPT North America)";
CM_ SG_ 639 ATS_RRSeatVentSW "ATS touch command for seat Vent control (For Rear Right seat)";
CM_ SG_ 639 ATS_RLRestModBtnSTD "Rear Left Rest Mode Touch Button (EXCEPT North America)";
CM_ SG_ 639 ATS_RLResetModBtnSTD "Rear Left Return Mode Touch Button (EXCEPT North America)";
CM_ SG_ 639 ATS_RRModestateStopBtn "Rear Right One touch mode Stop Button";
CM_ SG_ 639 ATS_RLModestateStopBtn "Rear Left One touch mode Stop Button";
CM_ SG_ 639 ATS_RLResetRestBtn "Rear Left Rest Mode Custom Initialization Button (Except North America)";
CM_ SG_ 639 ATS_RLResetReturnBtn "Rear Left Return Mode Custom Initialization Button (Except North America)";
CM_ SG_ 639 ATS_RRResetRestBtn "Rear Right Rest Mode Custom Initialization Button (Except North America)";
CM_ SG_ 639 ATS_RRResetReturnBtn "Rear Right Return Mode Custom Initialization Button (Except North America)";
CM_ SG_ 639 ATS_RRResetAvWtcBtn "Rear Right AV Watching Mode Custom Initialization Button (Except North America)";
CM_ SG_ 639 ATS_RRResetReadingBtn "Rear Right Reading Mode Custom Initialization Button (Except North America)";
CM_ SG_ 639 ATS_RLSeatVentSW "ATS touch command for seat Vent control (For Rear Left seat)";
CM_ SG_ 639 ATS_RRSeatHeaterUpSW "ATS touch command for seat heat control  (For Rear Right seat)";
CM_ BO_ 607 "[PE] Periodic and On Event";
CM_ SG_ 607 ATS_RRStSldFwdBtn "Rear Right Power Seat Slide Forward Touch Button";
CM_ SG_ 607 ATS_RRStSldBwdBtn "Rear Right Power Seat Slide Backward Touch Button";
CM_ SG_ 607 ATS_RRStRclFwdBtn "Rear Right Power Seat Recline Forward Touch Button";
CM_ SG_ 607 ATS_RRStRclBwdBtn "Rear Right Power Seat Recline Backward Touch Button";
CM_ SG_ 607 ATS_RRStTltUpBtn "Rear Right Power Seat Tilt Up Touch Button";
CM_ SG_ 607 ATS_RRStTltDnBtn "Rear Right Power Seat Tilt Down Touch Button";
CM_ SG_ 607 ATS_RRStLegRestPopBtn "Rear Right Leg Rest Move Pop Up Button";
CM_ SG_ 607 ATS_RRStFRestPopBtn "Rear Right Foot Rest Move Pop Up Button";
CM_ SG_ 607 ATS_RRStAstPopBtn "Rear Right Assist Seat Move Pop Up Button";
CM_ SG_ 607 ATS_RRFauCondiBtn "Rear Right FAU Operational Condition Move Button";
CM_ SG_ 607 ATS_RRStHRestUpBtn "Rear Right Power Seat Head Rest Up Touch Button";
CM_ SG_ 607 ATS_RRStHRestDnBtn "Rear Right Power Seat Head Rest Down Touch Button";
CM_ SG_ 607 ATS_RRStHRestFwdBtn "Rear Right Power Seat Head Rest Forward Touch Button";
CM_ SG_ 607 ATS_RRStHRestBwdBtn "Rear Right Power Seat Head Rest Backward Touch Button";
CM_ SG_ 607 ATS_RRStShoulderADJFwdBtn "Rear Right Power Seat Shoulder Adjuster Forward Touch Button";
CM_ SG_ 607 ATS_RRStShoulderADJBwdBtn "Rear Right Power Seat Shoulder Adjuster Backward Touch Button";
CM_ SG_ 607 ATS_RRStLegRestUpBtn "Rear Right Power Seat Leg Rest Up Touch Button";
CM_ SG_ 607 ATS_RRStLegRestDnBtn "Rear Right Power Seat Leg Rest Down Touch Button";
CM_ SG_ 607 ATS_RRStLegRestExtUpBtn "Rear Right Power Seat Leg Rest Ext. Up Touch Button";
CM_ SG_ 607 ATS_RRStLegRestExtDnBtn "Rear Right Power Seat Leg Rest Ext. Down Touch Button";
CM_ BO_ 679 "[PE] Periodic and On Event";
CM_ SG_ 679 CMS_RH_Crc1Val "CMS_RH_CyclicRedundancyCheck1Value";
CM_ SG_ 679 CMS_RH_AlvCnt1Val "CMS_RH_AliveCounter1Value";
CM_ SG_ 679 CMS_RHVerPosVal "RH Outside Mirror Vertical Position sensor value";
CM_ SG_ 679 CMS_RHHorPosVal "RH Outside Mirror Horizontal Position sensor value";
CM_ BO_ 2424579841 "[PE] Periodic and On Event";
CM_ SG_ 2424579841 DATC_Crc11Val "DATC_CyclicRedundancyCheck11Value";
CM_ SG_ 2424579841 DATC_AlvCnt11Val "DATC_AliveCounter11Value";
CM_ SG_ 2424579841 DATC_TunnelFuncOff4AutoDfgReq "DATC_TunnelFunctionOffForAutoDefogRequest";
CM_ SG_ 2424579841 DATC_RrCtlLckSta "Datc_RearClimateControlLockStatus";
CM_ SG_ 2424579841 DATC_DrvrStHtrUSMSta "DATC_DriverSeatHeaterUSMStatus";
CM_ SG_ 2424579841 DATC_WshFldUSMSta "DATC_WasherFulidUSMState";
CM_ SG_ 2424579841 DATC_DfgLgcUSMSta "DefLogic USM State";
CM_ SG_ 2424579841 DATC_AutoFrshUSMSta "Auto Fresh USM State";
CM_ SG_ 2424579841 DATC_HptIntnstySta "Haptic Intensity State";
CM_ SG_ 2424579841 DATC_ClmtPwrSum_W "accumulated energy consumption while driving(200ms)";
CM_ BO_ 687 "[P] Periodic";
CM_ SG_ 687 HOD_Crc1Val "HOD_CyclicRedundancyCheck1Value";
CM_ SG_ 687 HOD_AlvCnt1Val "HOD_AliveCounter1Value";
CM_ SG_ 687 HOD_Dir_Status "hands on-off status";
CM_ SG_ 687 HOD_Option "HOD_Option";
CM_ SG_ 687 HOD_CapaCh0 "Front zone Capacitance value(pF)";
CM_ SG_ 687 HOD_CapaCh1 "Rear zone Capacitance value(pF)";
CM_ SG_ 687 HOD_HDPSpprtSWVer "HDP Support SW Ver";
CM_ BO_ 2176872450 "[P] Periodic";
CM_ SG_ 2176872450 HDCT_TCURdySta "TCU Ready Status ## TCU11 - CF_Tcu_Rdy";
CM_ SG_ 2176872450 HDCT_NetrlCtrlSta "Neutralize Control Status ## TCU11 - CF_Tcu_NeutAck";
CM_ SG_ 2176872450 HDCT_GearShftSta "Gear Shfit Status ## TCU11 - CF_Tcu_GarChange";
CM_ SG_ 2176872450 HDCT_TqRdctnVal "Torque Reduction Value ## TCU11 - CR_Tcu_TqRedReq_Pc";
CM_ SG_ 2176872450 HDCT_CtrlablSta "Controllable Status ## TCU11 - CF_Tcu_Cont";
CM_ SG_ 2176872450 HTCU_SlwTqRdctnVal "Slow Torque Reduction Value ## TCU11 - CR_Tcu_TqRedReqSlw_Pc";
CM_ SG_ 2176872450 HDCT_TqIncReq "Torque Increase Request ## TCU11 - CF_Tcu_TqIncReq";
CM_ SG_ 2176872450 HDCT_TqIncVal "Torque Increase Value ## TCU11 - CR_Tcu_TqIncReq_Pc";
CM_ SG_ 2176872450 HDCT_TrgtShftCls "Target Shift Class ## TCU11 - CF_Tcu_ShiftClass";
CM_ SG_ 2176872450 HDCT_EOLReq "EOL Request ## DCT_TCU1 - CF_Tcu_DCT_EOLReq";
CM_ SG_ 2176872450 HDCT_CltchSta "Clutch Status ## DCT_TCU1 - CF_Tcu_CltStat";
CM_ SG_ 2176872450 HDCT_DblCltchSta "Double Clutch Status ## DCT_TCU1 - CF_Tcu_DCT_CltState";
CM_ SG_ 2176872450 HDCT_AcnChrgInhbtReq "Aircon Change Inhibit Request ## DCT_TCU1 - CF_Tcu_ChgInhAC";
CM_ SG_ 2176872450 HDCT_SlipCrnkAllw "Slip Crank Allow ## DCT_TCU1 - CF_Tcu_SlipCrk_Allow";
CM_ SG_ 2176872450 HDCT_KckDnSkpShftCnt "Kick Down Skip Shift Count ## DCT_TCU1 - CF_Tcu_KD_SkipShft_Cnt";
CM_ SG_ 2176872450 HDCT_ShftPhase "Shift Phase ## TCU11 - CF_Tcu_ShiftPhase";
CM_ BO_ 2176872451 "[P] Periodic";
CM_ SG_ 2176872451 HDCT_FuelCutReq "Fuel Cut Request ## DCT_TCU1 - CF_Tcu_FuelCutReq";
CM_ SG_ 2176872451 HDCT_NCoastTrgtGear "N Coast Target Gear ## DCT_TCU1 - CR_Tcu_NCoastTgtGear";
CM_ SG_ 2176872451 HDCT_CLUEngSpdFlag "Cluster Engine Speed Flag ## DCT_TCU1 - Cluster_Engine_RPM_Flag";
CM_ SG_ 2176872451 HDCT_CLUTrgtGear "Clutster Target Gear ## DCT_TCU1 - CF_Tcu_TarGeforCLU";
CM_ SG_ 2176872451 HDCT_GSITrgtGear "GSI Target Gear ## DCT_TCU1 - CF_Tcu_GSITgtGear";
CM_ SG_ 2176872451 HDCT_NCoastDnReq "N Coast Down Request ## DCT_TCU1 - CF_Tcu_NcoastDwnReq";
CM_ SG_ 2176872451 HDCT_CLUEngSpd "Clutster Engine Speed ## DCT_TCU1 - Cluster_Engine_RPM";
CM_ BO_ 1584 "[EC] On Event and On Change";
CM_ SG_ 1584 AMP_NaviWarnSound "Navi Warning prompt on/off";
CM_ SG_ 1584 AMP_Beep1Mode "Play touch beep sound one time
Beep1 mode on/off
For Harman AMP
Default : Off
Goes On when play beep sound
-This Signal's Feedback is AMP_Beep1ModeState(0x180)@AMP";
CM_ SG_ 1584 AMP_RrTTSSound "Rear TTS prompt on/offOnly ON during the Rear TTS Sound Playing Default : Off-This Signal's Feedback is AMP_RrTTSModeState(0x60c)@AMP";
CM_ SG_ 1584 AMP_ASDMode "ASD Set Mode Value";
CM_ SG_ 1584 AMP_ANCMode "Signal for setting ANC On/Off";
CM_ SG_ 1584 AMP_NaviSound "Navi prompt on/off
Only ON during the Navi Guide Sound Playing
Default : Off
-This Signal's Feedback is AMP_NaviModeState(0x180)@AMP";
CM_ SG_ 1584 AMP_ETCSSound "ETCS sound on/off";
CM_ SG_ 1584 AMP_Beep1KBDMode "Play touch beep sound at keyboard screen on AVN-This Signal's Feedback is AMP_Beep1KBDModeState@AMP";
CM_ SG_ 1584 AMP_ETCSVolumeStep "- Command for ETCS Volume Setting";
CM_ SG_ 1584 AMP_NaviWarnVolumeStep "- Command for Navigation Warning Prompt Volume Setting";
CM_ SG_ 1584 AMP_TTSSound "TTS prompt on/offOnly ON during the TTS Sound Playing Default : Off-This Signal's Feedback is AMP_TTSModeState(0x60c)@AMP";
CM_ SG_ 1584 AMP_SDVCStep "SDVC(Speed Dependant Volume Control = VSC) 
Step4 : off, low, mid, high";
CM_ BO_ 676 "[EC] On Event and On Change";
CM_ SG_ 676 C_DrAirSptNValueSet_EC "Driver Seat Smart Air Support On/Off";
CM_ SG_ 676 C_DrCushSoftNValueSet_EC "Driver Seat Cushion Softness";
CM_ SG_ 676 C_AstAirSptNValueSet_EC "Assistant Seat Smart Air Support On/Off";
CM_ SG_ 676 C_AstAirSptModeNValueSet_EC "Assistant Seat Smart Air Support Mode";
CM_ SG_ 676 C_DrAirSptModeNValueSet_EC "Driver Seat Smart Air Support Mode";
CM_ SG_ 676 C_RLAirSptNValueSet_EC "2nd Left Seat Smart Air Support On/Off";
CM_ SG_ 676 C_AstAirSptStrNValueSet_EC "Assistant Seat Smart Air Support Strength";
CM_ SG_ 676 C_AstAirSptTimeNValueSet_EC "Assistant Seat Smart Air Support Time";
CM_ SG_ 676 C_RRAirSptNValueSet_EC "2nd Right side seat Smart Air Support On/Off";
CM_ SG_ 676 C_AstCushSoftNValueSet_EC "Assistant Seat Cushion Softness off/low/mid/high";
CM_ SG_ 676 C_AstRlxNValueSet_EC "Assistant seat Moving control : Relaxtion mode";
CM_ SG_ 676 C_RLAirSptModeNValueSet_EC "2nd Left Seat Smart Air Support Mode";
CM_ SG_ 676 C_DrAirSptStrNValueSet_EC "Driver Seat Smart Air Support Strength";
CM_ SG_ 676 C_RLAirSptStrNValueSet_EC "2nd Left Seat Smart Air Support Strength";
CM_ SG_ 676 C_RLAirSptTimeNValueSet_EC "2nd Left Seat Smart Air Support Time";
CM_ SG_ 676 C_DrAirSptTimeNValueSet_EC "Driver Seat Smart Air Support Time";
CM_ BO_ 677 "[EC] On Event and On Change";
CM_ SG_ 677 C_RRAirSptStrNValueSet_EC "2nd Right side seat Smart Air Support Strength";
CM_ SG_ 677 C_RRAirSptTimeNValueSet_EC "2nd Right side seat Smart Air Support Time";
CM_ SG_ 677 C_RROneTchNvalueSet_EC "2nd Right side seat One Touch Mode";
CM_ SG_ 677 C_RLOneTchNValueSet_EC "2nd Left side seat One Touch Mode";
CM_ SG_ 677 C_RLOneTchNValueSet_EC_VR "2nd Left side seat One Touch Mode only for VR scenario";
CM_ SG_ 677 C_RROneTchNvalueSet_EC_VR "2nd Right side seat One Touch Mode only for VR scenario";
CM_ SG_ 677 C_RRAirSptModeNValueSet_EC "2nd Right side seat Moving control : Smart Air Support Mode";
CM_ BO_ 577 "[PE] Periodic and On Event";
CM_ SG_ 577 C_AstBolsterInfSw_HU "Assistant seat moving switch: Bolster Inflate";
CM_ SG_ 577 C_RLHrestUpSw_HU "2nd Left side seat Moving control : Headrest Up";
CM_ SG_ 577 C_RLHrestDnSw_HU "2nd Left side seat Moving control : Headrest Down";
CM_ SG_ 577 C_RLHrestFwdSw_HU "2nd Left side seat Moving control : Headrest Forward";
CM_ SG_ 577 C_AstBolsterDefSw_HU "Assistant seat moving switch: Bolster Deflate";
CM_ SG_ 577 C_RLHrestBwdSw_HU "2nd Left side seat Moving control : Headrest Backward";
CM_ SG_ 577 C_RLLumbarUpSw_HU "2nd Left side seat Moving control : Lumbar Up";
CM_ SG_ 577 C_RLLumbarMidSw_HU "2nd Left side seat Moving control : Lumbar Mid";
CM_ SG_ 577 C_RLLumbarLowSw_HU "2nd Left side seat Moving control : Lumbar Low";
CM_ SG_ 577 C_RLLumbarDefSw_HU "2nd Left side seat Moving control : Lumbar Deflate";
CM_ SG_ 577 C_RLBolsterInfSw_HU "2nd Left side seat Moving control : Bolster Inflate";
CM_ SG_ 577 C_RLBolsterDefSw_HU "2nd Left side seat Moving control : Bolster Deflate";
CM_ SG_ 577 C_AstHrestUpSw_HU "Assistant seat moving switch : Headrest Up";
CM_ SG_ 577 C_AstHrestDnSw_HU "Assistant seat Moving control : Headrest Down";
CM_ SG_ 577 C_AstHrestFwdSw_HU "Assistant seat Moving control : Headrest Forward";
CM_ SG_ 577 C_AstHrestBwdSw_HU "Assistant seat moving switch : Headrest Backward";
CM_ BO_ 578 "[PE] Periodic and On Event";
CM_ SG_ 578 C_RRLegSupFwdSw_HU "2nd Right side seat Moving control : Leg Support Forward";
CM_ SG_ 578 C_RRHrestDnSw_HU "2nd Right side seat Moving control : Headrest Down";
CM_ SG_ 578 C_RRHrestFwdSw_HU "2nd Right side seat Moving control : Headrest Forward";
CM_ SG_ 578 C_RRHrestBwdSw_HU "2nd Right side seat Moving control : Headrest Backward";
CM_ SG_ 578 C_RRLumbarUpSw_HU "2nd Right side seat Moving control : Lumbar Up";
CM_ SG_ 578 C_RRLumbarMidSw_HU "2nd Right side seat Moving control : Lumbar Mid";
CM_ SG_ 578 C_RRLegSupBwdSw_HU "2nd Right side seat Moving control : Leg Support Backward";
CM_ SG_ 578 C_RRLumbarLowSw_HU "2nd Right side seat Moving control : Lumbar Low";
CM_ SG_ 578 C_RRLumbarDefSw_HU "2nd Right side seat Moving control : Lumbar Deflate";
CM_ SG_ 578 C_RRBolsterInfSw_HU "2nd Right side seat Moving control : Bolster Inflate";
CM_ SG_ 578 C_RRLegSupUpSw_HU "2nd Right side seat Moving control : Leg Support Up";
CM_ SG_ 578 C_RROneTchNValueSet "2nd Right side seat One Touch Mode";
CM_ SG_ 578 C_RLOneTchNValueSet "2nd Left side seat One Touch Mode";
CM_ SG_ 578 C_RRBolsterDefSw_HU "2nd Right side seat Moving control : Bolster Deflate";
CM_ SG_ 578 C_AstRlxTiltUpSw_HU "Assistant seat Moving control : Relaxtion Tilt Up";
CM_ SG_ 578 C_AstRlxTiltDnSw_HU "Assistant seat Moving control : Relaxtion Tilt Down";
CM_ SG_ 578 C_RLRSEUpSw_HU "2nd Left side seat Moving control : RSE Up";
CM_ SG_ 578 C_RLRSEDnSw_HU "2nd Left side seat Moving control : RSE Down";
CM_ SG_ 578 C_RRRSEUpSw_HU "2nd Right side seat Moving control : RSE Up";
CM_ SG_ 578 C_RRLegSupDnSw_HU "2nd Right side seat Moving control : Leg Support Down";
CM_ SG_ 578 C_RRRSEDnSw_HU "2nd Right side seat Moving control : RSE Down";
CM_ SG_ 578 C_RRHrestUpSw_HU "2nd Right side seat Moving control : Headrest Up";
CM_ BO_ 675 "[EC] On Event and On Change";
CM_ SG_ 675 CF_AVN_HtBlcRLNValueSet "Request for 2nd Left seat heater balance";
CM_ SG_ 675 CF_AVN_ISLA_AutoNModSet "USM Set Signal for Activing N Mode Setting when Vehicle enter into Winding Road";
CM_ SG_ 675 CF_AVN_HtBlcRRNValueSet "Request for 2nd Right seat heater balance";
CM_ SG_ 675 CF_AVN_RemoteWDWNValueSet "Remote Window On/Off Set signal of USM for Fob Key";
CM_ SG_ 675 USM_TowWeight_Set "Trailer Mode Setting USM: Tow Weight set for User";
CM_ SG_ 675 CF_AVN_SportHUD2 "Related to HUD Sports mode of custom mode2";
CM_ SG_ 675 HU_CustomNewMenuSet "Custom Mode User Setting Signal";
CM_ SG_ 675 USM_RpmComfortRearSet "RPM Display Setting When Comfort(Rear) mode Set";
CM_ SG_ 675 Usm_RpmMyDriveModeSet "Cluster MY Drive Mode RPM Set Signal";
CM_ SG_ 675 CF_AVN_PCA_RrEquipNvalueSet "Headunit Setting signal for Rear Safety of USM";
CM_ BO_ 579 "[PE] Periodic and On Event";
CM_ SG_ 579 OHCL_Opt "OHCL option state";
CM_ SG_ 579 OHCL_Sys_sta "OHCL Status";
CM_ SG_ 579 OHCL_DoorOn_Sta "Door lamp switch On/Off status";
CM_ SG_ 579 OHCL_RrMapLftOn_Sta "Rear left map lamp On/Off status";
CM_ SG_ 579 OHCL_RrMapRtOn_Sta "Rear right map lamp On/Off status";
CM_ SG_ 579 OHCL_RrRoomOn_Sta "Rear room lamp On/Off status";
CM_ SG_ 579 OHCL_RrMoodOn_Sta "Rear mood lamp On/Off status";
CM_ SG_ 579 OHCL_LEDClr_Sta "Interior lamps lighting color status";
CM_ SG_ 579 OHCL_LEDBgtns_Sta "Interior lamps brightness status";
CM_ SG_ 579 OHCL_TllTlLmpSta "PAB tell tale lamp status";
CM_ SG_ 579 OHCL_FrMapLftOn_Sta "Front left map lamp On/Off status";
CM_ SG_ 579 OHCL_RrCurtainReq "Rear Curtain Switch On/Off Signal";
CM_ SG_ 579 OHCL_FrMapRtOn_Sta "Front right map lamp On/Off status";
CM_ SG_ 579 OHCL_FrRoomOn_Sta "Front room lamp On/Off status";
CM_ SG_ 579 OHCL_FrMoodOn_Sta "Front mood lamp On/Off status";
CM_ BO_ 632 "[PE] Periodic and On Event";
CM_ SG_ 632 PSS_RR_AstHRestFwdMvBtn "PSS_RR_AstStHead Rest UpMoveButton";
CM_ SG_ 632 PSS_RR_AstRclBwdMvBtn "PSS_RR_AstStReclinerBackwardMoveButton";
CM_ SG_ 632 PSS_RR_AstSldFwdMvBtn "PSS_RR_AstStSlideForwardMoveButton";
CM_ SG_ 632 PSS_RR_AstSldBwdMvBtn "PSS_RR_AstStSlideBackwardMoveButton";
CM_ SG_ 632 PSS_RR_AstHgtUpMvBtn "PSS_RR_AstStHeightUpMoveButton";
CM_ SG_ 632 PSS_RR_AstHgtDnMvBtn "PSS_RR_AstStHeightDownMoveButton";
CM_ SG_ 632 PSS_RR_AstHRestBwdMvBtn "PSS_RR_AstStHead Rest DownMoveButton";
CM_ SG_ 632 PSS_RR_AstFRestOpenMvBtn "PSS_RR_AstStFootrestOpenButton";
CM_ SG_ 632 PSS_RR_AstFRestCloseMvBtn "PSS_RR_AstStFootrestCloseButton";
CM_ SG_ 632 PSS_RR_AstHRestUpMvBtn "PSS_RR_AstStHead Rest ForwardMoveButton";
CM_ SG_ 632 PSS_RR_AstHRestDnMvBtn "PSS_RR_AstStHead Rest BackwardMoveButton";
CM_ SG_ 632 PSS_RR_AstRclFwdMvBtn "PSS_RR_AstStReclinerForwardMoveButton";
CM_ BO_ 681 "[EC] On Event and On Change";
CM_ SG_ 681 AVN_SeatPosMemory_Cmd "AVN_SeatPositionMemory_Command";
CM_ SG_ 681 RLPSM_RearModeWngDis "Rear Mode information for AVN Display";
CM_ SG_ 681 RLIMS_AMPBzrReq "SEAT IMS Buzzer Request for AMP";
CM_ SG_ 681 RLPSM_Warn_CnslLmt "RLPSM_Warning_ConsoleLimit";
CM_ SG_ 681 AVN_SeatPosPlyBck_Cmd "AVN_SeatPositionPlayBack_Command";
CM_ BO_ 599 "[EC] On Event and On Change";
CM_ SG_ 599 RRIMS_AMPBzrReq "SEAT IMS Buzzer Request for AMP";
CM_ SG_ 599 RRPSM_RearModeWngDis "Rear Mode information for AVN Display";
CM_ BO_ 2160080129 "[P] Periodic";
CM_ SG_ 2160080129 VCU_Crc1Val "VCU_CyclicRedundancyCheck1Value";
CM_ SG_ 2160080129 VCU_AlvCnt1Val "VCU_AliveCounter1Value";
CM_ SG_ 2160080129 VCU_RdySta "VCU_ReadyStatus ##2G##VCU - VCU1 - CF_Vcu_Rdy";
CM_ SG_ 2160080129 VCU_StartKeyHoldSta "VCU_StartKeyHoldStatus ##2G##VCU - VCU1 - CF_Vcu_Key_ST";
CM_ SG_ 2160080129 VCU_EvDrvRdySta "VCU_EvDriveReadyStatus ##2G##VCU - VCU1 - CF_Vcu_EvRdy";
CM_ SG_ 2160080129 VCU_MotPwrEnReq "VCU_MotorPowerEnableRequest ##2G##VCU - VCU3 - CF_Vcu_MotPwrEna";
CM_ SG_ 2160080129 VCU_GearPosSta "VCU_GearPositionStatus ##2G##VCU - VCU1 - CF_Vcu_GarSelDisp";
CM_ SG_ 2160080129 VCU_LdcInhReq "VCU_LdcInhibitRequest ##2G##VCU - VCU5 - CF_Vcu_LdcInh";
CM_ SG_ 2160080129 VCU_MainRlyOffReq "VCU_MainRelayCutOffRequest ##2G##VCU - VCU1 - CF_Vcu_RelayOffReq";
CM_ SG_ 2160080129 VCU_AccPedDepVal "VCU_AcceleratorPedalDepthValue ##2G##VCU - VCU1 - CR_Vcu_AccPedDep_Pc";
CM_ SG_ 2160080129 VCU_FatcOperPermSta "VCU_FatcOperatingPermissionStatus ##2G##VCU - VCU20 - CF_Vcu_ClimateOperPerm";
CM_ SG_ 2160080129 VCU_DrvCycSta "VCU_DrivingCycleStatus ##2G##VCU - VCU1 - CF_Vcu_Veh_DC";
CM_ SG_ 2160080129 VCU_CltActOpSta "VCU_ClutchActuatorOperatingStatus";
CM_ SG_ 2160080129 VCU_WhlSpdSnsrAlvReq "VCU_WheelSpeedSensorAliveRequest";
CM_ SG_ 2160080129 VCU_DrvModOpSta "VCU's operating drive mode according to CLU and DMIC signals";
CM_ SG_ 2160080129 VCU_HydBrkFcHoldRq "Hydraulic brake force holding request from VCU";
CM_ BO_ 2160080130 "[P] Periodic";
CM_ SG_ 2160080130 VCU_FatcPwrUseVal "VCU_FatcPowerUseValue ##2G##VCU - VCU5 - CR_Vcu_FatcCst";
CM_ SG_ 2160080130 VCU_McuAntiJerkInhFrntSta "VCU_McuAntiJerkInhibitionFrontStatus";
CM_ SG_ 2160080130 VCU_McuAntiJerkInhRearSta "VCU_McuAntiJerkInhibitionRearStatus ##2G##VCU - VCU3 - CF_Vcu_MCUAntiJerkInh";
CM_ SG_ 2160080130 VCU_McuPwrLatchHoldReq "VCU_McuPowerLatchHoldRequest ##2G##VCU - VCU20 - CF_Vcu_McuPwrLatchHoldReq";
CM_ SG_ 2160080130 VCU_ScuParkReq "VCU_ScuParkingRequest ##2G##VCU - VCU12 - CF_Vcu_PARKCMD";
CM_ SG_ 2160080130 VCU_MotTqCmdFrntVal "VCU_MotorTorqueCommandFrontValue";
CM_ SG_ 2160080130 VCU_ScuKeepWakeReq "VCU_ScuKeepWakeRequest ##2G##VCU - VCU12 - CF_Vcu_SSD";
CM_ SG_ 2160080130 VCU_MotTqCmdRearVal "VCU_MotorTorqueCommandRearValue";
CM_ SG_ 2160080130 VCU_FmcuZeroTqOfsReq "VCU_FmcuZeroTorqueOffsetRequest";
CM_ SG_ 2160080130 VCU_WhlDemTqVal "VCU_WheelDemandTorqueValue ##2G##VCU - VCU2 - CR_Vcu_WhlDemTq_Nm";
CM_ BO_ 2160080131 "[P] Periodic";
CM_ SG_ 2160080131 VCU_EcmSeqSta "VCU_EcmSequenceStatus ##2G##VCU - VCU1 - CF_Vcu_IGONStatus";
CM_ SG_ 2160080131 VCU_CltActDiagSta "VCU_ClutchActuatorDiagnosisStatus";
CM_ SG_ 2160080131 VCU_CltActDrvCrntVal "VCU_ClutchActuatorDriveCurrentValue";
CM_ SG_ 2160080131 VCU_CltActPosStrokeVal "VCU_ClutchActuatorPositionStrokeValue";
CM_ SG_ 2160080131 VCU_MainBattTypeSta "VCU_MainBatteryTypeStatus ##2G##VCU - VCU18 - CF_Vcu_MainBattType";
CM_ SG_ 2160080131 VCU_MainBattTypeLrnSta "VCU_MainBatteryTypeLearnStatus ##2G##VCU - VCU18 - CF_Vcu_MainBattTypeLrnSts";
CM_ SG_ 2160080131 VCU_WarmupCycSta "VCU_WarmupCycleStatus ##2G##VCU - VCU1 - CF_Vcu_WarmupCyc";
CM_ SG_ 2160080131 VCU_FatcPermPwrVal "VCU_FatcPermissionPowerValue ##2G##VCU - VCU5 - CR_Vcu_ClimatePerm_W";
CM_ SG_ 2160080131 VCU_EcmDiagSta "VCU_EcmDiagnosisStatus";
CM_ BO_ 2160080132 "[P] Periodic";
CM_ SG_ 2160080132 VCU_GearPosStaDisp "VCU_GearPositionStatusDisp";
CM_ SG_ 2160080132 VCU_PMPDActSta "PMPD Function Active State";
CM_ SG_ 2160080132 VCU_PdwLmtBrkRequest "Request brake torque for PDW Torque Limit";
CM_ SG_ 2160080132 VCU_VgsVirSoundBackFireIndex "Virtual sound back fire noise index for VGS mode";
CM_ SG_ 2160080132 VCU_VgsVirEngSpdRpmVal "Virtual engine speed for VGS mode";
CM_ SG_ 2160080132 VCU_PdlStopCtrlSta "Cooperative control state of VCU for stop assist control with IEB";
CM_ SG_ 2160080132 VCU_VgsVirSoundVolume "Virtual engine sound volume for VGS mode[%]";
CM_ SG_ 2160080132 VCU_VgsVirGearStep "Shift gear when entering VGS mode";
CM_ SG_ 2160080132 VCU_PdlStopReqTqNmVal "Requested brake torque for cooperative stop assist control";
CM_ SG_ 2160080132 VCU_StandbyModSta "Stand by Mode Status";
BA_DEF_ BO_ "DiagState" ENUM "No","Yes" ;
BA_DEF_ BO_ "DiagResponse" ENUM "No","Yes" ;
BA_DEF_ BO_ "DiagRequest" ENUM "No","Yes" ;
BA_DEF_ BO_ "TpMessage" ENUM "No","Yes" ;
BA_DEF_ BO_ "UsrMsgIDSforwardDeviation" INT 0 100 ;
BA_DEF_ BO_ "UsrMsgIDSbackwardDeviation" INT 50 1000 ;
BA_DEF_ BO_ "GenMsgCycleTime" INT 0 2000 ;
BA_DEF_ BO_ "GenMsgStartDelayTime" INT 0 2000 ;
BA_DEF_ BO_ "GenMsgSendType" ENUM "Cyclic","NoMsgSendType" ;
BA_DEF_ BO_ "GenMsgCycleTimeFast" INT 0 500 ;
BA_DEF_ BO_ "GenMsgDelayTime" INT 0 20 ;
BA_DEF_ BO_ "GenMsgILSupport" ENUM "No","Yes" ;
BA_DEF_ BO_ "GenMsgNrOfRepetition" INT 0 3 ;
BA_DEF_ BO_ "NmMessage" ENUM "No","Yes" ;
BA_DEF_ BO_ "NWM-Botschaft" ENUM "No","Yes" ;
BA_DEF_ BO_ "TpTxIndex" INT 0 65535 ;
BA_DEF_ BO_ "VFrameFormat" ENUM "StandardCAN","ExtendedCAN","reserved","reserved","reserved","reserved","reserved","reserved","reserved","reserved","reserved","reserved","reserved","reserved","StandardCAN_FD","ExtendedCAN_FD" ;
BA_DEF_ SG_ "UserSigValidity" ENUM "B+","ACC","IG","IG1","IG2","IG3","IG1 or IG2","IG1 or IG3","Undef" ;
BA_DEF_ SG_ "TimeoutValue" STRING ;
BA_DEF_ SG_ "UsrSigPurpose" ENUM "Undef","FN","DIAG","DIAG(Req)","DIAG(Res)","DIAG(Phy)","DEV","CCP(Req)","CCP(Res)","NM","TP" ;
BA_DEF_ SG_ "GenSigStartValue" INT 0 1215752192 ;
BA_DEF_ SG_ "NetworkRequest" ENUM "Yes","No" ;
BA_DEF_ SG_ "NetworkRequestHoldingTime" INT 0 65535 ;
BA_DEF_ SG_ "Description" STRING ;
BA_DEF_ SG_ "Version" STRING ;
BA_DEF_ SG_ "GenSigEnvVarType" ENUM "Int","Float","Undef" ;
BA_DEF_ SG_ "GenSigSendType" ENUM "Cyclic","OnWrite","OnWriteWithRepetition","OnChange","OnChangeWithRepetition","IfActive","IfActiveWithRepetition","NoSigSendType","OnChangeAndIfActive","OnChangeAndIfActiveWithRepetition" ;
BA_DEF_ SG_ "GwSigLatencyTime" INT 0 65536 ;
BA_DEF_ SG_ "GwSigMissingSourceType" ENUM "Undef","OldValue","DefaultValue","InitialValue" ;
BA_DEF_ SG_ "NWM-WakeupAllowed" ENUM "<n.a.>" ;
BA_DEF_ SG_ "RoutingFactor" INT 1 1215752192 ;
BA_DEF_REL_ BU_SG_REL_ "GenSigTimeoutTime" INT 0 7000 ;
BA_DEF_DEF_ "DiagState" "No" ;
BA_DEF_DEF_ "DiagResponse" "No" ;
BA_DEF_DEF_ "DiagRequest" "No" ;
BA_DEF_DEF_ "TpMessage" "No" ;
BA_DEF_DEF_ "UsrMsgIDSforwardDeviation" 10 ;
BA_DEF_DEF_ "UsrMsgIDSbackwardDeviation" 100 ;
BA_DEF_DEF_ "GenMsgCycleTime" 200 ;
BA_DEF_DEF_ "GenMsgStartDelayTime" 0 ;
BA_DEF_DEF_ "GenMsgSendType" "NoMsgSendType" ;
BA_DEF_DEF_ "GenMsgCycleTimeFast" 40 ;
BA_DEF_DEF_ "GenMsgDelayTime" 20 ;
BA_DEF_DEF_ "GenMsgILSupport" "Yes" ;
BA_DEF_DEF_ "GenMsgNrOfRepetition" 3 ;
BA_DEF_DEF_ "NmMessage" "No" ;
BA_DEF_DEF_ "NWM-Botschaft" "No" ;
BA_DEF_DEF_ "TpTxIndex" 0 ;
BA_DEF_DEF_ "VFrameFormat" "StandardCAN" ;
BA_DEF_DEF_ "UserSigValidity" "IG" ;
BA_DEF_DEF_ "TimeoutValue" "" ;
BA_DEF_DEF_ "UsrSigPurpose" "FN" ;
BA_DEF_DEF_ "GenSigStartValue" 0 ;
BA_DEF_DEF_ "NetworkRequest" "No" ;
BA_DEF_DEF_ "NetworkRequestHoldingTime" 0 ;
BA_DEF_DEF_ "Description" "" ;
BA_DEF_DEF_ "Version" "" ;
BA_DEF_DEF_ "GenSigEnvVarType" "Undef" ;
BA_DEF_DEF_ "GenSigSendType" "NoSigSendType" ;
BA_DEF_DEF_ "GwSigLatencyTime" 40 ;
BA_DEF_DEF_ "GwSigMissingSourceType" "Undef" ;
BA_DEF_DEF_ "NWM-WakeupAllowed" "<n.a.>" ;
BA_DEF_DEF_ "RoutingFactor" 1 ;
BA_DEF_DEF_REL_ "GenSigTimeoutTime" 500 ;
BA_ "GenMsgSendType" BO_ 1546 0;
BA_ "GenMsgCycleTimeFast" BO_ 1546 0;
BA_ "GenMsgNrOfRepetition" BO_ 1546 0;
BA_ "Description" SG_ 1546 AMP_SupportBeepVolumeControl "Does amp support Dynamic Speed Compensation mode?";
BA_ "GenSigStartValue" SG_ 1546 AMP_SupportBeepVolumeControl 3;
BA_ "UserSigValidity" SG_ 1546 AMP_SupportBeepVolumeControl 1;
BA_REL_ "GenSigTimeoutTime" BU_SG_REL_ ATS SG_ 1546 AMP_SupportBeepVolumeControl 1500;
BA_ "Version" SG_ 1546 AMP_SupportBeepVolumeControl "22.06.01";
BA_ "GenSigStartValue" SG_ 1546 AMP_SupportDSC 3;
BA_ "UserSigValidity" SG_ 1546 AMP_SupportDSC 1;
BA_ "Version" SG_ 1546 AMP_SupportDSC "22.06.01";
BA_ "GenSigStartValue" SG_ 1546 AMP_SupportANCMode 3;
BA_ "UserSigValidity" SG_ 1546 AMP_SupportANCMode 1;
BA_ "Version" SG_ 1546 AMP_SupportANCMode "22.06.01";
BA_ "GenSigStartValue" SG_ 1546 AMP_MakerID 255;
BA_ "UserSigValidity" SG_ 1546 AMP_MakerID 1;
BA_ "Version" SG_ 1546 AMP_MakerID "23.11.06";
BA_ "GenSigStartValue" SG_ 1546 AMP_SupportQLS 3;
BA_ "UserSigValidity" SG_ 1546 AMP_SupportQLS 1;
BA_ "Version" SG_ 1546 AMP_SupportQLS "22.06.01";
BA_ "GenSigStartValue" SG_ 1546 AMP_SupportHorizon 3;
BA_ "UserSigValidity" SG_ 1546 AMP_SupportHorizon 1;
BA_ "NetworkRequest" SG_ 1546 AMP_SupportHorizon 0;
BA_ "Version" SG_ 1546 AMP_SupportHorizon "22.06.01";
BA_ "Description" SG_ 1546 AMP_SupportASDMode "Does amp support CenterPoint mode?";
BA_ "GenSigStartValue" SG_ 1546 AMP_SupportASDMode 3;
BA_ "UserSigValidity" SG_ 1546 AMP_SupportASDMode 1;
BA_ "Version" SG_ 1546 AMP_SupportASDMode "22.06.01";
BA_ "GenSigStartValue" SG_ 1546 AMP_SupportIntelliQ 3;
BA_ "UserSigValidity" SG_ 1546 AMP_SupportIntelliQ 1;
BA_ "NetworkRequest" SG_ 1546 AMP_SupportIntelliQ 0;
BA_ "Version" SG_ 1546 AMP_SupportIntelliQ "22.06.01";
BA_ "GenSigStartValue" SG_ 1546 AMP_SupportCenterpoint 3;
BA_ "UserSigValidity" SG_ 1546 AMP_SupportCenterpoint 1;
BA_ "Version" SG_ 1546 AMP_SupportCenterpoint "22.06.01";
BA_ "GenSigStartValue" SG_ 1546 AMP_SupportLiveDynamicMode 7;
BA_ "UserSigValidity" SG_ 1546 AMP_SupportLiveDynamicMode 1;
BA_ "Version" SG_ 1546 AMP_SupportLiveDynamicMode "22.06.01";
BA_ "GenSigStartValue" SG_ 1546 AMP_Support_ElecSound 3;
BA_ "UserSigValidity" SG_ 1546 AMP_Support_ElecSound 1;
BA_ "NetworkRequest" SG_ 1546 AMP_Support_ElecSound 0;
BA_ "Version" SG_ 1546 AMP_Support_ElecSound "22.06.01";
BA_ "GenMsgCycleTime" BO_ 678 0;
BA_ "GenSigSendType" SG_ 678 Ast_AutoRlxWrngDis 4;
BA_ "UserSigValidity" SG_ 678 Ast_AutoRlxWrngDis 1;
BA_REL_ "GenSigTimeoutTime" BU_SG_REL_ CGW_CCU SG_ 678 Ast_AutoRlxWrngDis 0;
BA_ "NetworkRequest" SG_ 678 Ast_AutoRlxWrngDis 0;
BA_ "NetworkRequestHoldingTime" SG_ 678 Ast_AutoRlxWrngDis 5000;
BA_ "RoutingFactor" SG_ 678 Ast_AutoRlxWrngDis 0;
BA_ "Version" SG_ 678 Ast_AutoRlxWrngDis "21.06.10";
BA_ "GenSigSendType" SG_ 678 APSM_IMSWngDis 4;
BA_ "UserSigValidity" SG_ 678 APSM_IMSWngDis 0;
BA_ "NetworkRequest" SG_ 678 APSM_IMSWngDis 0;
BA_ "NetworkRequestHoldingTime" SG_ 678 APSM_IMSWngDis 5000;
BA_ "RoutingFactor" SG_ 678 APSM_IMSWngDis 0;
BA_ "Version" SG_ 678 APSM_IMSWngDis "21.08.01";
BA_ "Description" SG_ 678 Ast_2ndLnkRtnStop "Feedback signal when motion interruption occurs between movement of the second row seats and the first row seats";
BA_ "GenSigSendType" SG_ 678 Ast_2ndLnkRtnStop 4;
BA_ "UserSigValidity" SG_ 678 Ast_2ndLnkRtnStop 0;
BA_REL_ "GenSigTimeoutTime" BU_SG_REL_ GW_RLPSU SG_ 678 Ast_2ndLnkRtnStop 0;
BA_REL_ "GenSigTimeoutTime" BU_SG_REL_ GW_RRPSU SG_ 678 Ast_2ndLnkRtnStop 0;
BA_ "RoutingFactor" SG_ 678 Ast_2ndLnkRtnStop 0;
BA_ "Version" SG_ 678 Ast_2ndLnkRtnStop "22.05.03";
BA_ "Description" SG_ 678 Ast_2ndStStdPosMovReq "1¿­ µ¿½Â¼® ¸±·º¼Ç µ¿ÀÛ¿¡ ÀÇÇÑ 2¿­ RRÃø ½ÃÆ® ÀÌµ¿ ¿äÃ» ½ÅÈ£";
BA_ "GenSigSendType" SG_ 678 Ast_2ndStStdPosMovReq 4;
BA_ "UserSigValidity" SG_ 678 Ast_2ndStStdPosMovReq 0;
BA_REL_ "GenSigTimeoutTime" BU_SG_REL_ GW_RLPSU SG_ 678 Ast_2ndStStdPosMovReq 0;
BA_REL_ "GenSigTimeoutTime" BU_SG_REL_ GW_RRPSU SG_ 678 Ast_2ndStStdPosMovReq 0;
BA_ "NetworkRequest" SG_ 678 Ast_2ndStStdPosMovReq 0;
BA_ "NetworkRequestHoldingTime" SG_ 678 Ast_2ndStStdPosMovReq 5000;
BA_ "RoutingFactor" SG_ 678 Ast_2ndStStdPosMovReq 0;
BA_ "Version" SG_ 678 Ast_2ndStStdPosMovReq "22.05.02";
BA_ "Description" SG_ 678 AstIMS_AMPBzrReq "SEAT IMS Buzzer Request for AMP";
BA_ "GenSigSendType" SG_ 678 AstIMS_AMPBzrReq 4;
BA_ "UserSigValidity" SG_ 678 AstIMS_AMPBzrReq 0;
BA_REL_ "GenSigTimeoutTime" BU_SG_REL_ CGW_CCU SG_ 678 AstIMS_AMPBzrReq 0;
BA_ "NetworkRequest" SG_ 678 AstIMS_AMPBzrReq 0;
BA_ "NetworkRequestHoldingTime" SG_ 678 AstIMS_AMPBzrReq 5000;
BA_ "RoutingFactor" SG_ 678 AstIMS_AMPBzrReq 0;
BA_ "Version" SG_ 678 AstIMS_AMPBzrReq "22.12.04";
BA_ "Description" SG_ 678 Ast_AutoRlxWrngDis_2 "Assist seat auto relax warning information for AVN Display";
BA_ "GenSigSendType" SG_ 678 Ast_AutoRlxWrngDis_2 4;
BA_ "UserSigValidity" SG_ 678 Ast_AutoRlxWrngDis_2 1;
BA_REL_ "GenSigTimeoutTime" BU_SG_REL_ CGW_CCU SG_ 678 Ast_AutoRlxWrngDis_2 0;
BA_ "NetworkRequest" SG_ 678 Ast_AutoRlxWrngDis_2 0;
BA_ "NetworkRequestHoldingTime" SG_ 678 Ast_AutoRlxWrngDis_2 5000;
BA_ "RoutingFactor" SG_ 678 Ast_AutoRlxWrngDis_2 0;
BA_ "Version" SG_ 678 Ast_AutoRlxWrngDis_2 "22.11.00";
BA_ "GenMsgSendType" BO_ 591 0;
BA_ "Description" SG_ 591 ATS_RLStSldFwdBtn "ÈÄ¼® LH ½½¶óÀÌµù Àü¹æ ÀÌµ¿";
BA_ "GenSigSendType" SG_ 591 ATS_RLStSldFwdBtn 4;
BA_ "UserSigValidity" SG_ 591 ATS_RLStSldFwdBtn 3;
BA_ "NetworkRequest" SG_ 591 ATS_RLStSldFwdBtn 0;
BA_ "NetworkRequestHoldingTime" SG_ 591 ATS_RLStSldFwdBtn 5000;
BA_ "Version" SG_ 591 ATS_RLStSldFwdBtn "19.09.02";
BA_ "Description" SG_ 591 ATS_RLStSldBwdBtn "ÈÄ¼® LH ½½¶óÀÌµù ÈÄ¹æ ÀÌµ¿";
BA_ "GenSigSendType" SG_ 591 ATS_RLStSldBwdBtn 4;
BA_ "UserSigValidity" SG_ 591 ATS_RLStSldBwdBtn 3;
BA_ "NetworkRequest" SG_ 591 ATS_RLStSldBwdBtn 0;
BA_ "NetworkRequestHoldingTime" SG_ 591 ATS_RLStSldBwdBtn 5000;
BA_ "Version" SG_ 591 ATS_RLStSldBwdBtn "19.09.02";
BA_ "Description" SG_ 591 ATS_RLStRclFwdBtn "ÈÄ¼® LH ¸®Å¬¶óÀÌ´× Àü¹æ ÀÌµ¿";
BA_ "GenSigSendType" SG_ 591 ATS_RLStRclFwdBtn 4;
BA_ "UserSigValidity" SG_ 591 ATS_RLStRclFwdBtn 3;
BA_ "NetworkRequest" SG_ 591 ATS_RLStRclFwdBtn 0;
BA_ "NetworkRequestHoldingTime" SG_ 591 ATS_RLStRclFwdBtn 5000;
BA_ "Version" SG_ 591 ATS_RLStRclFwdBtn "19.09.02";
BA_ "Description" SG_ 591 ATS_RLStRclBwdBtn "ÈÄ¼® LH ¸®Å¬¶óÀÌ´× ÈÄ¹æ ÀÌµ¿";
BA_ "GenSigSendType" SG_ 591 ATS_RLStRclBwdBtn 4;
BA_ "UserSigValidity" SG_ 591 ATS_RLStRclBwdBtn 3;
BA_ "NetworkRequest" SG_ 591 ATS_RLStRclBwdBtn 0;
BA_ "NetworkRequestHoldingTime" SG_ 591 ATS_RLStRclBwdBtn 5000;
BA_ "Version" SG_ 591 ATS_RLStRclBwdBtn "19.09.02";
BA_ "Description" SG_ 591 ATS_RLStTltUpBtn "ÈÄ¼® LH Æ¿Æ® ¾÷ ÀÌµ¿";
BA_ "GenSigSendType" SG_ 591 ATS_RLStTltUpBtn 4;
BA_ "UserSigValidity" SG_ 591 ATS_RLStTltUpBtn 3;
BA_ "NetworkRequest" SG_ 591 ATS_RLStTltUpBtn 0;
BA_ "NetworkRequestHoldingTime" SG_ 591 ATS_RLStTltUpBtn 5000;
BA_ "Version" SG_ 591 ATS_RLStTltUpBtn "19.09.02";
BA_ "Description" SG_ 591 ATS_RLStTltDnBtn "ÈÄ¼® LH Æ¿Æ® ´Ù¿î ÀÌµ¿";
BA_ "GenSigSendType" SG_ 591 ATS_RLStTltDnBtn 4;
BA_ "UserSigValidity" SG_ 591 ATS_RLStTltDnBtn 3;
BA_ "NetworkRequest" SG_ 591 ATS_RLStTltDnBtn 0;
BA_ "NetworkRequestHoldingTime" SG_ 591 ATS_RLStTltDnBtn 5000;
BA_ "Version" SG_ 591 ATS_RLStTltDnBtn "19.09.02";
BA_ "Description" SG_ 591 ATS_RLStHRestUpBtn "ÈÄ¼® LH Çìµå·¹½ºÆ® ¾÷ ÀÌµ¿";
BA_ "GenSigSendType" SG_ 591 ATS_RLStHRestUpBtn 4;
BA_ "UserSigValidity" SG_ 591 ATS_RLStHRestUpBtn 3;
BA_ "NetworkRequest" SG_ 591 ATS_RLStHRestUpBtn 0;
BA_ "NetworkRequestHoldingTime" SG_ 591 ATS_RLStHRestUpBtn 5000;
BA_ "Version" SG_ 591 ATS_RLStHRestUpBtn "19.09.02";
BA_ "Description" SG_ 591 ATS_RLStHRestDnBtn "ÈÄ¼® LH Çìµå·¹½ºÆ® ´Ù¿î ÀÌµ¿";
BA_ "GenSigSendType" SG_ 591 ATS_RLStHRestDnBtn 4;
BA_ "UserSigValidity" SG_ 591 ATS_RLStHRestDnBtn 3;
BA_ "NetworkRequest" SG_ 591 ATS_RLStHRestDnBtn 0;
BA_ "NetworkRequestHoldingTime" SG_ 591 ATS_RLStHRestDnBtn 5000;
BA_ "Version" SG_ 591 ATS_RLStHRestDnBtn "19.09.02";
BA_ "Description" SG_ 591 ATS_RLStHRestFwdBtn "ÈÄ¼® LH Çìµå·¹½ºÆ® Àü¹æ ÀÌµ¿";
BA_ "GenSigSendType" SG_ 591 ATS_RLStHRestFwdBtn 4;
BA_ "UserSigValidity" SG_ 591 ATS_RLStHRestFwdBtn 3;
BA_ "NetworkRequest" SG_ 591 ATS_RLStHRestFwdBtn 0;
BA_ "NetworkRequestHoldingTime" SG_ 591 ATS_RLStHRestFwdBtn 5000;
BA_ "Version" SG_ 591 ATS_RLStHRestFwdBtn "19.09.02";
BA_ "Description" SG_ 591 ATS_RLStHRestBwdBtn "ÈÄ¼® LH Çìµå·¹½ºÆ® ÈÄ¹æ ÀÌµ¿";
BA_ "GenSigSendType" SG_ 591 ATS_RLStHRestBwdBtn 4;
BA_ "UserSigValidity" SG_ 591 ATS_RLStHRestBwdBtn 3;
BA_ "NetworkRequest" SG_ 591 ATS_RLStHRestBwdBtn 0;
BA_ "NetworkRequestHoldingTime" SG_ 591 ATS_RLStHRestBwdBtn 5000;
BA_ "Version" SG_ 591 ATS_RLStHRestBwdBtn "19.09.02";
BA_ "Description" SG_ 591 ATS_RLStLegRestUpBtn "ÈÄ¼® LH ·¹±×·¹½ºÆ® UP";
BA_ "GenSigSendType" SG_ 591 ATS_RLStLegRestUpBtn 4;
BA_ "UserSigValidity" SG_ 591 ATS_RLStLegRestUpBtn 3;
BA_ "NetworkRequest" SG_ 591 ATS_RLStLegRestUpBtn 0;
BA_ "NetworkRequestHoldingTime" SG_ 591 ATS_RLStLegRestUpBtn 5000;
BA_ "Version" SG_ 591 ATS_RLStLegRestUpBtn "19.11.09";
BA_ "Description" SG_ 591 ATS_RLStLegRestDnBtn "ÈÄ¼® LH ·¹±×·¹½ºÆ® DOWN";
BA_ "GenSigSendType" SG_ 591 ATS_RLStLegRestDnBtn 4;
BA_ "UserSigValidity" SG_ 591 ATS_RLStLegRestDnBtn 3;
BA_ "NetworkRequest" SG_ 591 ATS_RLStLegRestDnBtn 0;
BA_ "NetworkRequestHoldingTime" SG_ 591 ATS_RLStLegRestDnBtn 5000;
BA_ "Version" SG_ 591 ATS_RLStLegRestDnBtn "21.06.11";
BA_ "Description" SG_ 591 ATS_RLStLegRestExtUpBtn "ÈÄ¼® LH ·¹±×·¹½ºÆ® EXT";
BA_ "GenSigSendType" SG_ 591 ATS_RLStLegRestExtUpBtn 4;
BA_ "UserSigValidity" SG_ 591 ATS_RLStLegRestExtUpBtn 3;
BA_ "NetworkRequest" SG_ 591 ATS_RLStLegRestExtUpBtn 0;
BA_ "NetworkRequestHoldingTime" SG_ 591 ATS_RLStLegRestExtUpBtn 5000;
BA_ "Version" SG_ 591 ATS_RLStLegRestExtUpBtn "19.11.09";
BA_ "Description" SG_ 591 ATS_RLStLegRestExtDnBtn "ÈÄ¼® LH ·¹±×·¹½ºÆ® EXT BWD";
BA_ "GenSigSendType" SG_ 591 ATS_RLStLegRestExtDnBtn 4;
BA_ "UserSigValidity" SG_ 591 ATS_RLStLegRestExtDnBtn 3;
BA_ "NetworkRequest" SG_ 591 ATS_RLStLegRestExtDnBtn 0;
BA_ "NetworkRequestHoldingTime" SG_ 591 ATS_RLStLegRestExtDnBtn 5000;
BA_ "Version" SG_ 591 ATS_RLStLegRestExtDnBtn "19.11.09";
BA_ "Description" SG_ 591 ATS_RLStShoulderADJFwdBtn "ÈÄ¼® LH ¼ñ´õ¾îÁ®½ºÅÍ FWD";
BA_ "GenSigSendType" SG_ 591 ATS_RLStShoulderADJFwdBtn 4;
BA_ "UserSigValidity" SG_ 591 ATS_RLStShoulderADJFwdBtn 3;
BA_ "NetworkRequest" SG_ 591 ATS_RLStShoulderADJFwdBtn 0;
BA_ "NetworkRequestHoldingTime" SG_ 591 ATS_RLStShoulderADJFwdBtn 5000;
BA_ "Version" SG_ 591 ATS_RLStShoulderADJFwdBtn "20.03.02";
BA_ "Description" SG_ 591 ATS_RLStShoulderADJBwdBtn "ÈÄ¼® LH ¼ñ´õ¾îÁ®½ºÅÍ BWD";
BA_ "GenSigSendType" SG_ 591 ATS_RLStShoulderADJBwdBtn 4;
BA_ "UserSigValidity" SG_ 591 ATS_RLStShoulderADJBwdBtn 3;
BA_ "NetworkRequest" SG_ 591 ATS_RLStShoulderADJBwdBtn 0;
BA_ "NetworkRequestHoldingTime" SG_ 591 ATS_RLStShoulderADJBwdBtn 5000;
BA_ "Version" SG_ 591 ATS_RLStShoulderADJBwdBtn "20.03.02";
BA_ "GenMsgCycleTime" BO_ 639 0;
BA_ "Description" SG_ 639 ATS_RRSeatHeaterSW "ÈÄ¼® RH ½ÃÆ® ¿­¼± Á¶Àý";
BA_ "GenSigSendType" SG_ 639 ATS_RRSeatHeaterSW 4;
BA_ "UserSigValidity" SG_ 639 ATS_RRSeatHeaterSW 3;
BA_REL_ "GenSigTimeoutTime" BU_SG_REL_ RRHV SG_ 639 ATS_RRSeatHeaterSW 0;
BA_REL_ "GenSigTimeoutTime" BU_SG_REL_ SHVU_RR SG_ 639 ATS_RRSeatHeaterSW 0;
BA_ "NetworkRequest" SG_ 639 ATS_RRSeatHeaterSW 0;
BA_ "NetworkRequestHoldingTime" SG_ 639 ATS_RRSeatHeaterSW 5000;
BA_ "Version" SG_ 639 ATS_RRSeatHeaterSW "20.07.01";
BA_ "Description" SG_ 639 ATS_RLSeatHeaterUpSW "ÈÄ¼® LH ½ÃÆ® ¿­¼± Á¶Àý";
BA_ "GenSigSendType" SG_ 639 ATS_RLSeatHeaterUpSW 4;
BA_ "UserSigValidity" SG_ 639 ATS_RLSeatHeaterUpSW 3;
BA_REL_ "GenSigTimeoutTime" BU_SG_REL_ RLHV SG_ 639 ATS_RLSeatHeaterUpSW 0;
BA_REL_ "GenSigTimeoutTime" BU_SG_REL_ SHVU_RR SG_ 639 ATS_RLSeatHeaterUpSW 0;
BA_ "NetworkRequest" SG_ 639 ATS_RLSeatHeaterUpSW 0;
BA_ "NetworkRequestHoldingTime" SG_ 639 ATS_RLSeatHeaterUpSW 5000;
BA_ "Version" SG_ 639 ATS_RLSeatHeaterUpSW "20.12.04";
BA_ "Description" SG_ 639 ATS_RRSeatVentDownSW "ÈÄ¼® RH ½ÃÆ® ÅëÇ³ Á¶Àý";
BA_ "GenSigSendType" SG_ 639 ATS_RRSeatVentDownSW 4;
BA_ "UserSigValidity" SG_ 639 ATS_RRSeatVentDownSW 3;
BA_REL_ "GenSigTimeoutTime" BU_SG_REL_ RRHV SG_ 639 ATS_RRSeatVentDownSW 0;
BA_REL_ "GenSigTimeoutTime" BU_SG_REL_ SHVU_RR SG_ 639 ATS_RRSeatVentDownSW 0;
BA_ "NetworkRequest" SG_ 639 ATS_RRSeatVentDownSW 0;
BA_ "NetworkRequestHoldingTime" SG_ 639 ATS_RRSeatVentDownSW 5000;
BA_ "Version" SG_ 639 ATS_RRSeatVentDownSW "20.12.04";
BA_ "Description" SG_ 639 ATS_RLSeatVentDownSW "ÈÄ¼® LH ½ÃÆ® ÅëÇ³ Á¶Àý";
BA_ "GenSigSendType" SG_ 639 ATS_RLSeatVentDownSW 4;
BA_ "UserSigValidity" SG_ 639 ATS_RLSeatVentDownSW 3;
BA_REL_ "GenSigTimeoutTime" BU_SG_REL_ RLHV SG_ 639 ATS_RLSeatVentDownSW 0;
BA_REL_ "GenSigTimeoutTime" BU_SG_REL_ SHVU_RR SG_ 639 ATS_RLSeatVentDownSW 0;
BA_ "NetworkRequest" SG_ 639 ATS_RLSeatVentDownSW 0;
BA_ "NetworkRequestHoldingTime" SG_ 639 ATS_RLSeatVentDownSW 5000;
BA_ "Version" SG_ 639 ATS_RLSeatVentDownSW "20.12.04";
BA_ "Description" SG_ 639 ATS_RLMemoryRestBtn "Rear Left Rest Mode Custom Save Button (Except North America)";
BA_ "GenSigSendType" SG_ 639 ATS_RLMemoryRestBtn 4;
BA_ "UserSigValidity" SG_ 639 ATS_RLMemoryRestBtn 3;
BA_ "NetworkRequest" SG_ 639 ATS_RLMemoryRestBtn 0;
BA_ "NetworkRequestHoldingTime" SG_ 639 ATS_RLMemoryRestBtn 5000;
BA_ "Version" SG_ 639 ATS_RLMemoryRestBtn "21.01.02";
BA_ "Description" SG_ 639 ATS_RLMemoryReturnBtn "Rear Left Return Mode Custom Save Button (Except North America)";
BA_ "GenSigSendType" SG_ 639 ATS_RLMemoryReturnBtn 4;
BA_ "UserSigValidity" SG_ 639 ATS_RLMemoryReturnBtn 3;
BA_ "NetworkRequest" SG_ 639 ATS_RLMemoryReturnBtn 0;
BA_ "NetworkRequestHoldingTime" SG_ 639 ATS_RLMemoryReturnBtn 5000;
BA_ "Version" SG_ 639 ATS_RLMemoryReturnBtn "21.01.02";
BA_ "Description" SG_ 639 ATS_RLSeatHeaterSW "ÈÄ¼® LH ½ÃÆ® ¿­¼± Á¶Àý";
BA_ "GenSigSendType" SG_ 639 ATS_RLSeatHeaterSW 4;
BA_ "UserSigValidity" SG_ 639 ATS_RLSeatHeaterSW 3;
BA_REL_ "GenSigTimeoutTime" BU_SG_REL_ RLHV SG_ 639 ATS_RLSeatHeaterSW 0;
BA_REL_ "GenSigTimeoutTime" BU_SG_REL_ SHVU_RR SG_ 639 ATS_RLSeatHeaterSW 0;
BA_ "NetworkRequest" SG_ 639 ATS_RLSeatHeaterSW 0;
BA_ "NetworkRequestHoldingTime" SG_ 639 ATS_RLSeatHeaterSW 5000;
BA_ "Version" SG_ 639 ATS_RLSeatHeaterSW "20.07.01";
BA_ "Description" SG_ 639 ATS_RRMemoryRestBtn "Rear Right Rest Mode Custom Save Button (Except North America)";
BA_ "GenSigSendType" SG_ 639 ATS_RRMemoryRestBtn 4;
BA_ "UserSigValidity" SG_ 639 ATS_RRMemoryRestBtn 3;
BA_ "NetworkRequest" SG_ 639 ATS_RRMemoryRestBtn 0;
BA_ "NetworkRequestHoldingTime" SG_ 639 ATS_RRMemoryRestBtn 5000;
BA_ "Version" SG_ 639 ATS_RRMemoryRestBtn "21.01.02";
BA_ "Description" SG_ 639 ATS_RRMemoryReturnBtn "Rear Right Return Mode Custom Save Button (Except North America)";
BA_ "GenSigSendType" SG_ 639 ATS_RRMemoryReturnBtn 4;
BA_ "UserSigValidity" SG_ 639 ATS_RRMemoryReturnBtn 3;
BA_ "NetworkRequest" SG_ 639 ATS_RRMemoryReturnBtn 0;
BA_ "NetworkRequestHoldingTime" SG_ 639 ATS_RRMemoryReturnBtn 5000;
BA_ "Version" SG_ 639 ATS_RRMemoryReturnBtn "21.01.02";
BA_ "Description" SG_ 639 ATS_RRMemoryAvWtcBtn "Rear Right AV Watching Mode Custom Save Button (Except North America)";
BA_ "GenSigSendType" SG_ 639 ATS_RRMemoryAvWtcBtn 4;
BA_ "UserSigValidity" SG_ 639 ATS_RRMemoryAvWtcBtn 3;
BA_ "NetworkRequest" SG_ 639 ATS_RRMemoryAvWtcBtn 0;
BA_ "NetworkRequestHoldingTime" SG_ 639 ATS_RRMemoryAvWtcBtn 5000;
BA_ "Version" SG_ 639 ATS_RRMemoryAvWtcBtn "21.01.02";
BA_ "Description" SG_ 639 ATS_RRMemoryReadingBtn "Rear Right Reading Mode Custom Save Button (Except North America)";
BA_ "GenSigSendType" SG_ 639 ATS_RRMemoryReadingBtn 4;
BA_ "UserSigValidity" SG_ 639 ATS_RRMemoryReadingBtn 3;
BA_ "NetworkRequest" SG_ 639 ATS_RRMemoryReadingBtn 0;
BA_ "NetworkRequestHoldingTime" SG_ 639 ATS_RRMemoryReadingBtn 5000;
BA_ "Version" SG_ 639 ATS_RRMemoryReadingBtn "21.01.02";
BA_ "Description" SG_ 639 ATS_RRRestModBtnSTD "Rear Right Rest Mode Touch Button (EXCEPT North America)";
BA_ "GenSigSendType" SG_ 639 ATS_RRRestModBtnSTD 4;
BA_ "UserSigValidity" SG_ 639 ATS_RRRestModBtnSTD 3;
BA_ "NetworkRequest" SG_ 639 ATS_RRRestModBtnSTD 0;
BA_ "NetworkRequestHoldingTime" SG_ 639 ATS_RRRestModBtnSTD 5000;
BA_ "Version" SG_ 639 ATS_RRRestModBtnSTD "20.07.01";
BA_ "Description" SG_ 639 ATS_RRResetModBtnSTD "Rear Right Return Mode Touch Button (EXCEPT North America)";
BA_ "GenSigSendType" SG_ 639 ATS_RRResetModBtnSTD 4;
BA_ "UserSigValidity" SG_ 639 ATS_RRResetModBtnSTD 3;
BA_ "NetworkRequest" SG_ 639 ATS_RRResetModBtnSTD 0;
BA_ "NetworkRequestHoldingTime" SG_ 639 ATS_RRResetModBtnSTD 5000;
BA_ "Version" SG_ 639 ATS_RRResetModBtnSTD "20.07.01";
BA_ "Description" SG_ 639 ATS_RRAvWtcModBtnSTD "Rear Right AV Watching Mode Touch Button (EXCEPT North America)";
BA_ "GenSigSendType" SG_ 639 ATS_RRAvWtcModBtnSTD 4;
BA_ "UserSigValidity" SG_ 639 ATS_RRAvWtcModBtnSTD 3;
BA_ "NetworkRequest" SG_ 639 ATS_RRAvWtcModBtnSTD 0;
BA_ "NetworkRequestHoldingTime" SG_ 639 ATS_RRAvWtcModBtnSTD 5000;
BA_ "Version" SG_ 639 ATS_RRAvWtcModBtnSTD "20.07.01";
BA_ "Description" SG_ 639 ATS_RRReadingModBtnSTD "Rear Right Reading Mode Touch Button (EXCEPT North America)";
BA_ "GenSigSendType" SG_ 639 ATS_RRReadingModBtnSTD 4;
BA_ "UserSigValidity" SG_ 639 ATS_RRReadingModBtnSTD 3;
BA_ "NetworkRequest" SG_ 639 ATS_RRReadingModBtnSTD 0;
BA_ "NetworkRequestHoldingTime" SG_ 639 ATS_RRReadingModBtnSTD 5000;
BA_ "Version" SG_ 639 ATS_RRReadingModBtnSTD "20.07.01";
BA_ "Description" SG_ 639 ATS_RRSeatVentSW "ÈÄ¼® RH ½ÃÆ® ÅëÇ³ Á¶Àý";
BA_ "GenSigSendType" SG_ 639 ATS_RRSeatVentSW 4;
BA_ "UserSigValidity" SG_ 639 ATS_RRSeatVentSW 3;
BA_REL_ "GenSigTimeoutTime" BU_SG_REL_ RRHV SG_ 639 ATS_RRSeatVentSW 0;
BA_REL_ "GenSigTimeoutTime" BU_SG_REL_ SHVU_RR SG_ 639 ATS_RRSeatVentSW 0;
BA_ "NetworkRequest" SG_ 639 ATS_RRSeatVentSW 0;
BA_ "NetworkRequestHoldingTime" SG_ 639 ATS_RRSeatVentSW 5000;
BA_ "Version" SG_ 639 ATS_RRSeatVentSW "20.07.01";
BA_ "Description" SG_ 639 ATS_RLRestModBtnSTD "Rear Left Rest Mode Touch Button (EXCEPT North America)";
BA_ "GenSigSendType" SG_ 639 ATS_RLRestModBtnSTD 4;
BA_ "UserSigValidity" SG_ 639 ATS_RLRestModBtnSTD 3;
BA_ "NetworkRequest" SG_ 639 ATS_RLRestModBtnSTD 0;
BA_ "NetworkRequestHoldingTime" SG_ 639 ATS_RLRestModBtnSTD 5000;
BA_ "Version" SG_ 639 ATS_RLRestModBtnSTD "20.07.01";
BA_ "Description" SG_ 639 ATS_RLResetModBtnSTD "Rear Left Return Mode Touch Button (EXCEPT North America)";
BA_ "GenSigSendType" SG_ 639 ATS_RLResetModBtnSTD 4;
BA_ "UserSigValidity" SG_ 639 ATS_RLResetModBtnSTD 3;
BA_ "NetworkRequest" SG_ 639 ATS_RLResetModBtnSTD 0;
BA_ "NetworkRequestHoldingTime" SG_ 639 ATS_RLResetModBtnSTD 5000;
BA_ "Version" SG_ 639 ATS_RLResetModBtnSTD "20.07.01";
BA_ "Description" SG_ 639 ATS_RRModestateStopBtn "Rear Right One touch mode Stop Button";
BA_ "GenSigSendType" SG_ 639 ATS_RRModestateStopBtn 4;
BA_ "UserSigValidity" SG_ 639 ATS_RRModestateStopBtn 3;
BA_ "NetworkRequest" SG_ 639 ATS_RRModestateStopBtn 0;
BA_ "NetworkRequestHoldingTime" SG_ 639 ATS_RRModestateStopBtn 5000;
BA_ "Version" SG_ 639 ATS_RRModestateStopBtn "20.07.01";
BA_ "Description" SG_ 639 ATS_RLModestateStopBtn "Rear Left One touch mode Stop Button";
BA_ "GenSigSendType" SG_ 639 ATS_RLModestateStopBtn 4;
BA_ "UserSigValidity" SG_ 639 ATS_RLModestateStopBtn 3;
BA_ "NetworkRequest" SG_ 639 ATS_RLModestateStopBtn 0;
BA_ "NetworkRequestHoldingTime" SG_ 639 ATS_RLModestateStopBtn 5000;
BA_ "Version" SG_ 639 ATS_RLModestateStopBtn "20.07.01";
BA_ "Description" SG_ 639 ATS_RLResetRestBtn "Rear Left Rest Mode Custom Initialization Button (Except North America)";
BA_ "GenSigSendType" SG_ 639 ATS_RLResetRestBtn 4;
BA_ "UserSigValidity" SG_ 639 ATS_RLResetRestBtn 3;
BA_ "NetworkRequest" SG_ 639 ATS_RLResetRestBtn 0;
BA_ "NetworkRequestHoldingTime" SG_ 639 ATS_RLResetRestBtn 5000;
BA_ "Version" SG_ 639 ATS_RLResetRestBtn "21.01.02";
BA_ "Description" SG_ 639 ATS_RLResetReturnBtn "Rear Left Return Mode Custom Initialization Button (Except North America)";
BA_ "GenSigSendType" SG_ 639 ATS_RLResetReturnBtn 4;
BA_ "UserSigValidity" SG_ 639 ATS_RLResetReturnBtn 3;
BA_ "NetworkRequest" SG_ 639 ATS_RLResetReturnBtn 0;
BA_ "NetworkRequestHoldingTime" SG_ 639 ATS_RLResetReturnBtn 5000;
BA_ "Version" SG_ 639 ATS_RLResetReturnBtn "21.01.02";
BA_ "Description" SG_ 639 ATS_RRResetRestBtn "Rear Right Rest Mode Custom Initialization Button (Except North America)";
BA_ "GenSigSendType" SG_ 639 ATS_RRResetRestBtn 4;
BA_ "UserSigValidity" SG_ 639 ATS_RRResetRestBtn 3;
BA_ "NetworkRequest" SG_ 639 ATS_RRResetRestBtn 0;
BA_ "NetworkRequestHoldingTime" SG_ 639 ATS_RRResetRestBtn 5000;
BA_ "Version" SG_ 639 ATS_RRResetRestBtn "21.01.02";
BA_ "Description" SG_ 639 ATS_RRResetReturnBtn "Rear Right Return Mode Custom Initialization Button (Except North America)";
BA_ "GenSigSendType" SG_ 639 ATS_RRResetReturnBtn 4;
BA_ "UserSigValidity" SG_ 639 ATS_RRResetReturnBtn 3;
BA_ "NetworkRequest" SG_ 639 ATS_RRResetReturnBtn 0;
BA_ "NetworkRequestHoldingTime" SG_ 639 ATS_RRResetReturnBtn 5000;
BA_ "Version" SG_ 639 ATS_RRResetReturnBtn "21.01.02";
BA_ "Description" SG_ 639 ATS_RRResetAvWtcBtn "Rear Right AV Watching Mode Custom Initialization Button (Except North America)";
BA_ "GenSigSendType" SG_ 639 ATS_RRResetAvWtcBtn 4;
BA_ "UserSigValidity" SG_ 639 ATS_RRResetAvWtcBtn 3;
BA_ "NetworkRequest" SG_ 639 ATS_RRResetAvWtcBtn 0;
BA_ "NetworkRequestHoldingTime" SG_ 639 ATS_RRResetAvWtcBtn 5000;
BA_ "Version" SG_ 639 ATS_RRResetAvWtcBtn "21.01.02";
BA_ "Description" SG_ 639 ATS_RRResetReadingBtn "Rear Right Reading Mode Custom Initialization Button (Except North America)";
BA_ "GenSigSendType" SG_ 639 ATS_RRResetReadingBtn 4;
BA_ "UserSigValidity" SG_ 639 ATS_RRResetReadingBtn 3;
BA_ "NetworkRequest" SG_ 639 ATS_RRResetReadingBtn 0;
BA_ "NetworkRequestHoldingTime" SG_ 639 ATS_RRResetReadingBtn 5000;
BA_ "Version" SG_ 639 ATS_RRResetReadingBtn "21.01.02";
BA_ "Description" SG_ 639 ATS_RLSeatVentSW "ÈÄ¼® LH ½ÃÆ® ÅëÇ³ Á¶Àý";
BA_ "GenSigSendType" SG_ 639 ATS_RLSeatVentSW 4;
BA_ "UserSigValidity" SG_ 639 ATS_RLSeatVentSW 3;
BA_REL_ "GenSigTimeoutTime" BU_SG_REL_ RLHV SG_ 639 ATS_RLSeatVentSW 0;
BA_REL_ "GenSigTimeoutTime" BU_SG_REL_ SHVU_RR SG_ 639 ATS_RLSeatVentSW 0;
BA_ "NetworkRequest" SG_ 639 ATS_RLSeatVentSW 0;
BA_ "NetworkRequestHoldingTime" SG_ 639 ATS_RLSeatVentSW 5000;
BA_ "Version" SG_ 639 ATS_RLSeatVentSW "20.07.01";
BA_ "Description" SG_ 639 ATS_RRSeatHeaterUpSW "ÈÄ¼® RH ½ÃÆ® ¿­¼± Á¶Àý";
BA_ "GenSigSendType" SG_ 639 ATS_RRSeatHeaterUpSW 4;
BA_ "UserSigValidity" SG_ 639 ATS_RRSeatHeaterUpSW 3;
BA_REL_ "GenSigTimeoutTime" BU_SG_REL_ RRHV SG_ 639 ATS_RRSeatHeaterUpSW 0;
BA_REL_ "GenSigTimeoutTime" BU_SG_REL_ SHVU_RR SG_ 639 ATS_RRSeatHeaterUpSW 0;
BA_ "NetworkRequest" SG_ 639 ATS_RRSeatHeaterUpSW 0;
BA_ "NetworkRequestHoldingTime" SG_ 639 ATS_RRSeatHeaterUpSW 5000;
BA_ "Version" SG_ 639 ATS_RRSeatHeaterUpSW "20.12.04";
BA_ "GenMsgSendType" BO_ 607 0;
BA_ "Description" SG_ 607 ATS_RRStSldFwdBtn "ÈÄ¼® RH ½½¶óÀÌµù Àü¹æ ÀÌµ¿";
BA_ "GenSigSendType" SG_ 607 ATS_RRStSldFwdBtn 4;
BA_ "UserSigValidity" SG_ 607 ATS_RRStSldFwdBtn 3;
BA_ "NetworkRequest" SG_ 607 ATS_RRStSldFwdBtn 0;
BA_ "NetworkRequestHoldingTime" SG_ 607 ATS_RRStSldFwdBtn 5000;
BA_ "Version" SG_ 607 ATS_RRStSldFwdBtn "19.09.02";
BA_ "Description" SG_ 607 ATS_RRStSldBwdBtn "ÈÄ¼® RH ½½¶óÀÌµù ÈÄ¹æ ÀÌµ¿";
BA_ "GenSigSendType" SG_ 607 ATS_RRStSldBwdBtn 4;
BA_ "UserSigValidity" SG_ 607 ATS_RRStSldBwdBtn 3;
BA_ "NetworkRequest" SG_ 607 ATS_RRStSldBwdBtn 0;
BA_ "NetworkRequestHoldingTime" SG_ 607 ATS_RRStSldBwdBtn 5000;
BA_ "Version" SG_ 607 ATS_RRStSldBwdBtn "19.09.02";
BA_ "Description" SG_ 607 ATS_RRStRclFwdBtn "ÈÄ¼® RH ¸®Å¬¶óÀÌ´× Àü¹æ ÀÌµ¿";
BA_ "GenSigSendType" SG_ 607 ATS_RRStRclFwdBtn 4;
BA_ "UserSigValidity" SG_ 607 ATS_RRStRclFwdBtn 3;
BA_ "NetworkRequest" SG_ 607 ATS_RRStRclFwdBtn 0;
BA_ "NetworkRequestHoldingTime" SG_ 607 ATS_RRStRclFwdBtn 5000;
BA_ "Version" SG_ 607 ATS_RRStRclFwdBtn "19.09.02";
BA_ "Description" SG_ 607 ATS_RRStRclBwdBtn "ÈÄ¼® RH ¸®Å¬¶óÀÌ´× ÈÄ¹æ ÀÌµ¿";
BA_ "GenSigSendType" SG_ 607 ATS_RRStRclBwdBtn 4;
BA_ "UserSigValidity" SG_ 607 ATS_RRStRclBwdBtn 3;
BA_ "NetworkRequest" SG_ 607 ATS_RRStRclBwdBtn 0;
BA_ "NetworkRequestHoldingTime" SG_ 607 ATS_RRStRclBwdBtn 5000;
BA_ "Version" SG_ 607 ATS_RRStRclBwdBtn "19.09.02";
BA_ "Description" SG_ 607 ATS_RRStTltUpBtn "ÈÄ¼® RH Æ¿Æ® ¾÷ ÀÌµ¿";
BA_ "GenSigSendType" SG_ 607 ATS_RRStTltUpBtn 4;
BA_ "UserSigValidity" SG_ 607 ATS_RRStTltUpBtn 3;
BA_ "NetworkRequest" SG_ 607 ATS_RRStTltUpBtn 0;
BA_ "NetworkRequestHoldingTime" SG_ 607 ATS_RRStTltUpBtn 5000;
BA_ "Version" SG_ 607 ATS_RRStTltUpBtn "19.09.02";
BA_ "Description" SG_ 607 ATS_RRStTltDnBtn "ÈÄ¼® RH Æ¿Æ® ´Ù¿î ÀÌµ¿";
BA_ "GenSigSendType" SG_ 607 ATS_RRStTltDnBtn 4;
BA_ "UserSigValidity" SG_ 607 ATS_RRStTltDnBtn 3;
BA_ "NetworkRequest" SG_ 607 ATS_RRStTltDnBtn 0;
BA_ "NetworkRequestHoldingTime" SG_ 607 ATS_RRStTltDnBtn 5000;
BA_ "Version" SG_ 607 ATS_RRStTltDnBtn "19.09.02";
BA_ "Description" SG_ 607 ATS_RRStLegRestPopBtn "Rear Right Leg Rest Move Pop Up Button";
BA_ "GenSigSendType" SG_ 607 ATS_RRStLegRestPopBtn 4;
BA_ "UserSigValidity" SG_ 607 ATS_RRStLegRestPopBtn 3;
BA_ "NetworkRequest" SG_ 607 ATS_RRStLegRestPopBtn 0;
BA_ "NetworkRequestHoldingTime" SG_ 607 ATS_RRStLegRestPopBtn 5000;
BA_ "Version" SG_ 607 ATS_RRStLegRestPopBtn "20.07.01";
BA_ "Description" SG_ 607 ATS_RRStFRestPopBtn "Rear Right Foot Rest Move Pop Up Button";
BA_ "GenSigSendType" SG_ 607 ATS_RRStFRestPopBtn 4;
BA_ "UserSigValidity" SG_ 607 ATS_RRStFRestPopBtn 3;
BA_ "NetworkRequest" SG_ 607 ATS_RRStFRestPopBtn 0;
BA_ "NetworkRequestHoldingTime" SG_ 607 ATS_RRStFRestPopBtn 5000;
BA_ "Version" SG_ 607 ATS_RRStFRestPopBtn "20.07.01";
BA_ "Description" SG_ 607 ATS_RRStAstPopBtn "Rear Right Assist Seat Move Pop Up Button";
BA_ "GenSigSendType" SG_ 607 ATS_RRStAstPopBtn 4;
BA_ "UserSigValidity" SG_ 607 ATS_RRStAstPopBtn 3;
BA_ "NetworkRequest" SG_ 607 ATS_RRStAstPopBtn 0;
BA_ "NetworkRequestHoldingTime" SG_ 607 ATS_RRStAstPopBtn 5000;
BA_ "Version" SG_ 607 ATS_RRStAstPopBtn "20.07.01";
BA_ "Description" SG_ 607 ATS_RRFauCondiBtn "Rear Right FAU Operational Condition Move Button";
BA_ "GenSigSendType" SG_ 607 ATS_RRFauCondiBtn 4;
BA_ "UserSigValidity" SG_ 607 ATS_RRFauCondiBtn 3;
BA_ "NetworkRequest" SG_ 607 ATS_RRFauCondiBtn 0;
BA_ "NetworkRequestHoldingTime" SG_ 607 ATS_RRFauCondiBtn 5000;
BA_ "Version" SG_ 607 ATS_RRFauCondiBtn "20.07.01";
BA_ "Description" SG_ 607 ATS_RRStHRestUpBtn "ÈÄ¼® RH Çìµå·¹½ºÆ® ¾÷ ÀÌµ¿";
BA_ "GenSigSendType" SG_ 607 ATS_RRStHRestUpBtn 4;
BA_ "UserSigValidity" SG_ 607 ATS_RRStHRestUpBtn 3;
BA_ "NetworkRequest" SG_ 607 ATS_RRStHRestUpBtn 0;
BA_ "NetworkRequestHoldingTime" SG_ 607 ATS_RRStHRestUpBtn 5000;
BA_ "Version" SG_ 607 ATS_RRStHRestUpBtn "19.09.02";
BA_ "Description" SG_ 607 ATS_RRStHRestDnBtn "ÈÄ¼® RH Çìµå·¹½ºÆ® ´Ù¿î ÀÌµ¿";
BA_ "GenSigSendType" SG_ 607 ATS_RRStHRestDnBtn 4;
BA_ "UserSigValidity" SG_ 607 ATS_RRStHRestDnBtn 3;
BA_ "NetworkRequest" SG_ 607 ATS_RRStHRestDnBtn 0;
BA_ "NetworkRequestHoldingTime" SG_ 607 ATS_RRStHRestDnBtn 5000;
BA_ "Version" SG_ 607 ATS_RRStHRestDnBtn "19.09.02";
BA_ "Description" SG_ 607 ATS_RRStHRestFwdBtn "ÈÄ¼® RH Çìµå·¹½ºÆ® Àü¹æ ÀÌµ¿";
BA_ "GenSigSendType" SG_ 607 ATS_RRStHRestFwdBtn 4;
BA_ "UserSigValidity" SG_ 607 ATS_RRStHRestFwdBtn 3;
BA_ "NetworkRequest" SG_ 607 ATS_RRStHRestFwdBtn 0;
BA_ "NetworkRequestHoldingTime" SG_ 607 ATS_RRStHRestFwdBtn 5000;
BA_ "Version" SG_ 607 ATS_RRStHRestFwdBtn "19.09.02";
BA_ "Description" SG_ 607 ATS_RRStHRestBwdBtn "ÈÄ¼® RH Çìµå·¹½ºÆ® ÈÄ¹æ ÀÌµ¿";
BA_ "GenSigSendType" SG_ 607 ATS_RRStHRestBwdBtn 4;
BA_ "UserSigValidity" SG_ 607 ATS_RRStHRestBwdBtn 3;
BA_ "NetworkRequest" SG_ 607 ATS_RRStHRestBwdBtn 0;
BA_ "NetworkRequestHoldingTime" SG_ 607 ATS_RRStHRestBwdBtn 5000;
BA_ "Version" SG_ 607 ATS_RRStHRestBwdBtn "19.09.02";
BA_ "Description" SG_ 607 ATS_RRStShoulderADJFwdBtn "ÈÄ¼® RH ¼ñ´õ¾îÁ®½ºÅÍ FWD ÀÌµ¿";
BA_ "GenSigSendType" SG_ 607 ATS_RRStShoulderADJFwdBtn 4;
BA_ "UserSigValidity" SG_ 607 ATS_RRStShoulderADJFwdBtn 3;
BA_ "NetworkRequest" SG_ 607 ATS_RRStShoulderADJFwdBtn 0;
BA_ "NetworkRequestHoldingTime" SG_ 607 ATS_RRStShoulderADJFwdBtn 5000;
BA_ "Version" SG_ 607 ATS_RRStShoulderADJFwdBtn "20.03.02";
BA_ "Description" SG_ 607 ATS_RRStShoulderADJBwdBtn "ÈÄ¼® RH ¼ñ´õ¾îÁ®½ºÅÍ BWD ÀÌµ¿";
BA_ "GenSigSendType" SG_ 607 ATS_RRStShoulderADJBwdBtn 4;
BA_ "UserSigValidity" SG_ 607 ATS_RRStShoulderADJBwdBtn 3;
BA_ "NetworkRequest" SG_ 607 ATS_RRStShoulderADJBwdBtn 0;
BA_ "NetworkRequestHoldingTime" SG_ 607 ATS_RRStShoulderADJBwdBtn 5000;
BA_ "Version" SG_ 607 ATS_RRStShoulderADJBwdBtn "20.03.02";
BA_ "Description" SG_ 607 ATS_RRStLegRestUpBtn "ÈÄ¼® RH ·¹±×·¹½ºÆ® ¾÷ ÀÌµ¿";
BA_ "GenSigSendType" SG_ 607 ATS_RRStLegRestUpBtn 4;
BA_ "UserSigValidity" SG_ 607 ATS_RRStLegRestUpBtn 3;
BA_ "NetworkRequest" SG_ 607 ATS_RRStLegRestUpBtn 0;
BA_ "NetworkRequestHoldingTime" SG_ 607 ATS_RRStLegRestUpBtn 5000;
BA_ "Version" SG_ 607 ATS_RRStLegRestUpBtn "19.09.02";
BA_ "Description" SG_ 607 ATS_RRStLegRestDnBtn "ÈÄ¼® RH ·¹±×·¹½ºÆ® ´Ù¿î ÀÌµ¿";
BA_ "GenSigSendType" SG_ 607 ATS_RRStLegRestDnBtn 4;
BA_ "UserSigValidity" SG_ 607 ATS_RRStLegRestDnBtn 3;
BA_ "NetworkRequest" SG_ 607 ATS_RRStLegRestDnBtn 0;
BA_ "NetworkRequestHoldingTime" SG_ 607 ATS_RRStLegRestDnBtn 5000;
BA_ "Version" SG_ 607 ATS_RRStLegRestDnBtn "19.09.02";
BA_ "Description" SG_ 607 ATS_RRStLegRestExtUpBtn "ÈÄ¼® RH ·¹±×·¹½ºÆ® Àü¹æ ÀÍ½ºÅÙ¼Ç ÀÌµ¿";
BA_ "GenSigSendType" SG_ 607 ATS_RRStLegRestExtUpBtn 4;
BA_ "UserSigValidity" SG_ 607 ATS_RRStLegRestExtUpBtn 3;
BA_ "NetworkRequest" SG_ 607 ATS_RRStLegRestExtUpBtn 0;
BA_ "NetworkRequestHoldingTime" SG_ 607 ATS_RRStLegRestExtUpBtn 5000;
BA_ "Version" SG_ 607 ATS_RRStLegRestExtUpBtn "19.09.02";
BA_ "Description" SG_ 607 ATS_RRStLegRestExtDnBtn "ÈÄ¼® RH ·¹±×·¹½ºÆ® ÈÄ¹æ ÀÍ½ºÅÙ¼Ç ÀÌµ¿";
BA_ "GenSigSendType" SG_ 607 ATS_RRStLegRestExtDnBtn 4;
BA_ "UserSigValidity" SG_ 607 ATS_RRStLegRestExtDnBtn 3;
BA_ "NetworkRequest" SG_ 607 ATS_RRStLegRestExtDnBtn 0;
BA_ "NetworkRequestHoldingTime" SG_ 607 ATS_RRStLegRestExtDnBtn 5000;
BA_ "Version" SG_ 607 ATS_RRStLegRestExtDnBtn "19.09.02";
BA_ "GenMsgSendType" BO_ 679 0;
BA_ "Description" SG_ 679 CMS_RH_Crc1Val "The data area for CRC calculation is based on the data length (DLC) of the message DB.

The CRC shall be calculated over the entire data block (excluding the CRC bytes) including the user data, alive counter and Data ID 

 

- CRC Polynomial (0x1D) , Initial Value : 0x00, XOR value : 0xFF, Data ID Mode : Both, Data ID : Message ID + 0xF800 

- The initial value is for CRC calculation and the message should be sent with the calculated result value. 

The mathematical expression to 8 bit CRC polynomial is given here. G(x) = x8 + x4 + x3 + x2 + 1";
BA_ "GenSigSendType" SG_ 679 CMS_RH_Crc1Val 4;
BA_ "UserSigValidity" SG_ 679 CMS_RH_Crc1Val 0;
BA_ "RoutingFactor" SG_ 679 CMS_RH_Crc1Val 0;
BA_ "Version" SG_ 679 CMS_RH_Crc1Val "21.09.03";
BA_ "Description" SG_ 679 CMS_RH_AlvCnt1Val "For the first transmission request for a data element the counter shall be initialized with 0 and shall be incremented by 1

for every subsequent send request. When the counter reaches the maximum value(0xE), then it shall restart with 0 for the next send request";
BA_ "GenSigSendType" SG_ 679 CMS_RH_AlvCnt1Val 4;
BA_ "UserSigValidity" SG_ 679 CMS_RH_AlvCnt1Val 0;
BA_ "RoutingFactor" SG_ 679 CMS_RH_AlvCnt1Val 0;
BA_ "Version" SG_ 679 CMS_RH_AlvCnt1Val "21.09.03";
BA_ "GenSigSendType" SG_ 679 USM_CMSDayBrgtnsLvlRHSta 4;
BA_ "GenSigStartValue" SG_ 679 USM_CMSDayBrgtnsLvlRHSta 5;
BA_ "UserSigValidity" SG_ 679 USM_CMSDayBrgtnsLvlRHSta 0;
BA_ "NetworkRequest" SG_ 679 USM_CMSDayBrgtnsLvlRHSta 0;
BA_ "NetworkRequestHoldingTime" SG_ 679 USM_CMSDayBrgtnsLvlRHSta 5;
BA_ "RoutingFactor" SG_ 679 USM_CMSDayBrgtnsLvlRHSta 0;
BA_ "Version" SG_ 679 USM_CMSDayBrgtnsLvlRHSta "21.08.01";
BA_ "GenSigSendType" SG_ 679 USM_CMSNgtBrgtnsLvlRHSta 4;
BA_ "GenSigStartValue" SG_ 679 USM_CMSNgtBrgtnsLvlRHSta 5;
BA_ "UserSigValidity" SG_ 679 USM_CMSNgtBrgtnsLvlRHSta 0;
BA_ "NetworkRequest" SG_ 679 USM_CMSNgtBrgtnsLvlRHSta 0;
BA_ "NetworkRequestHoldingTime" SG_ 679 USM_CMSNgtBrgtnsLvlRHSta 5;
BA_ "RoutingFactor" SG_ 679 USM_CMSNgtBrgtnsLvlRHSta 0;
BA_ "Version" SG_ 679 USM_CMSNgtBrgtnsLvlRHSta "21.08.01";
BA_ "GenSigSendType" SG_ 679 IMS_CMSPlayBackSta_RH 4;
BA_ "UserSigValidity" SG_ 679 IMS_CMSPlayBackSta_RH 0;
BA_REL_ "GenSigTimeoutTime" BU_SG_REL_ GW_DPSU SG_ 679 IMS_CMSPlayBackSta_RH 1500;
BA_ "NetworkRequest" SG_ 679 IMS_CMSPlayBackSta_RH 0;
BA_ "NetworkRequestHoldingTime" SG_ 679 IMS_CMSPlayBackSta_RH 5;
BA_ "RoutingFactor" SG_ 679 IMS_CMSPlayBackSta_RH 0;
BA_ "Version" SG_ 679 IMS_CMSPlayBackSta_RH "21.08.01";
BA_ "GenSigSendType" SG_ 679 MonitorStatus 4;
BA_ "UserSigValidity" SG_ 679 MonitorStatus 0;
BA_ "NetworkRequest" SG_ 679 MonitorStatus 0;
BA_ "NetworkRequestHoldingTime" SG_ 679 MonitorStatus 5;
BA_ "RoutingFactor" SG_ 679 MonitorStatus 0;
BA_ "Version" SG_ 679 MonitorStatus "21.08.01";
BA_ "GenSigSendType" SG_ 679 CMS_RH_FoldingSta 4;
BA_ "UserSigValidity" SG_ 679 CMS_RH_FoldingSta 0;
BA_ "NetworkRequest" SG_ 679 CMS_RH_FoldingSta 0;
BA_ "NetworkRequestHoldingTime" SG_ 679 CMS_RH_FoldingSta 5000;
BA_ "RoutingFactor" SG_ 679 CMS_RH_FoldingSta 0;
BA_ "Version" SG_ 679 CMS_RH_FoldingSta "21.08.01";
BA_ "GenSigSendType" SG_ 679 CMS_RH_UnfoldingSta 4;
BA_ "UserSigValidity" SG_ 679 CMS_RH_UnfoldingSta 0;
BA_ "NetworkRequest" SG_ 679 CMS_RH_UnfoldingSta 0;
BA_ "NetworkRequestHoldingTime" SG_ 679 CMS_RH_UnfoldingSta 5000;
BA_ "RoutingFactor" SG_ 679 CMS_RH_UnfoldingSta 0;
BA_ "Version" SG_ 679 CMS_RH_UnfoldingSta "21.08.01";
BA_ "Description" SG_ 679 CMS_RHVerPosVal "This signal indicates RH Outside Mirror Vertical Position Sensor Voltage";
BA_ "GenSigSendType" SG_ 679 CMS_RHVerPosVal 4;
BA_ "UserSigValidity" SG_ 679 CMS_RHVerPosVal 0;
BA_ "NetworkRequest" SG_ 679 CMS_RHVerPosVal 0;
BA_ "NetworkRequestHoldingTime" SG_ 679 CMS_RHVerPosVal 5000;
BA_ "RoutingFactor" SG_ 679 CMS_RHVerPosVal 0;
BA_ "Version" SG_ 679 CMS_RHVerPosVal "21.08.01";
BA_ "Description" SG_ 679 CMS_RHHorPosVal "This signal indicates RH Outside Mirror Horizontal Position Sensor Voltage";
BA_ "GenSigSendType" SG_ 679 CMS_RHHorPosVal 4;
BA_ "UserSigValidity" SG_ 679 CMS_RHHorPosVal 0;
BA_ "NetworkRequest" SG_ 679 CMS_RHHorPosVal 0;
BA_ "NetworkRequestHoldingTime" SG_ 679 CMS_RHHorPosVal 5000;
BA_ "RoutingFactor" SG_ 679 CMS_RHHorPosVal 0;
BA_ "Version" SG_ 679 CMS_RHHorPosVal "21.08.01";
BA_ "GenMsgSendType" BO_ 2424579841 0;
BA_ "VFrameFormat" BO_ 2424579841 1;
BA_ "Description" SG_ 2424579841 DATC_Crc11Val "The data area for CRC calculation is based on the data length (DLC) of the message DB.

The CRC shall be calculated over the entire data block (excluding the CRC bytes) including the user data, alive counter and Data ID



- CRC Polynomial (0x1021) , Initial Value : 0xFFFF, XOR value : 0x0000, Data ID : Message ID + 0xF800 

- The initial value is for CRC calculation and the message should be sent with the calculated result value. 

- The mathematical expression to 16 bit CRC polynomial is given here. G(x) = x16 + x12 + x5 + 1



<For CRC calculation of CAN-FD Msg for HS CAN domain ECUs>



- HS-CAN Messages that routed from CAN-FD domain are using 29 bit Extended CAN ID and splitted into 8 Byte Messages.

(from 1 to 4 Msgs, depending on source CAN-FD Msg¡¯s DLC)

- For splitted CAN-FD Msgs¡¯ CRC calculation, HS CAN ECUs should use source CAN-FD Msg¡¯s original STD ID. 

- The original STD ID can be read from Ext ID¡¯s 4~6th Byte.

Eg. STD 0x6AA : EXT SPLT 0x1A8[6AA]01 / 0x1A8[6AA]02 / 0x1A8[6AA]03 / 0x1A8[6AA]04 

(2~4th splitited Msgs can be omitted depending on source CAN-FD Msg¡¯s DLC)

- Aslo, HS-CAN ECUs should use merged data block (from whole splitted Msg) for CRC calculation.";
BA_ "GenSigSendType" SG_ 2424579841 DATC_Crc11Val 4;
BA_ "GenSigStartValue" SG_ 2424579841 DATC_Crc11Val 65535;
BA_ "UserSigValidity" SG_ 2424579841 DATC_Crc11Val 3;
BA_ "Version" SG_ 2424579841 DATC_Crc11Val "21.09.03";
BA_ "Description" SG_ 2424579841 DATC_AlvCnt11Val "For the first transmission request for a data element the counter shall be initialized with 0 and shall be incremented by 1 for every subsequent send request. 

When the counter reaches the maximum value(0xFF), then it shall restart with 0 for the next send request";
BA_ "GenSigSendType" SG_ 2424579841 DATC_AlvCnt11Val 4;
BA_ "UserSigValidity" SG_ 2424579841 DATC_AlvCnt11Val 3;
BA_ "Version" SG_ 2424579841 DATC_AlvCnt11Val "21.09.03";
BA_ "Description" SG_ 2424579841 DATC_TunnelFuncOff4AutoDfgReq "DATC Turn off Tunnel Function for ADS";
BA_ "GenSigSendType" SG_ 2424579841 DATC_TunnelFuncOff4AutoDfgReq 4;
BA_ "UserSigValidity" SG_ 2424579841 DATC_TunnelFuncOff4AutoDfgReq 7;
BA_ "Version" SG_ 2424579841 DATC_TunnelFuncOff4AutoDfgReq "21.07.06";
BA_ "Description" SG_ 2424579841 DATC_RrCtlLckSta "Rear Lock Status Informed  DATC  to AVN";
BA_ "GenSigSendType" SG_ 2424579841 DATC_RrCtlLckSta 4;
BA_ "UserSigValidity" SG_ 2424579841 DATC_RrCtlLckSta 7;
BA_REL_ "GenSigTimeoutTime" BU_SG_REL_ ATS SG_ 2424579841 DATC_RrCtlLckSta 1500;
BA_ "Version" SG_ 2424579841 DATC_RrCtlLckSta "17.11.00";
BA_ "Description" SG_ 2424579841 DATC_DrvrStHtrUSMSta "If the 'Auto Comfort Control' function is applied separately to the Seat and Steering Wheel, 

this signal is used.";
BA_ "GenSigSendType" SG_ 2424579841 DATC_DrvrStHtrUSMSta 4;
BA_ "UserSigValidity" SG_ 2424579841 DATC_DrvrStHtrUSMSta 7;
BA_REL_ "GenSigTimeoutTime" BU_SG_REL_ GW_APSU SG_ 2424579841 DATC_DrvrStHtrUSMSta 1500;
BA_REL_ "GenSigTimeoutTime" BU_SG_REL_ GW_DPSU SG_ 2424579841 DATC_DrvrStHtrUSMSta 1500;
BA_ "Version" SG_ 2424579841 DATC_DrvrStHtrUSMSta "17.11.00";
BA_ "Description" SG_ 2424579841 DATC_WshFldUSMSta "This signal indicate Washer Fulid USM State.";
BA_ "GenSigSendType" SG_ 2424579841 DATC_WshFldUSMSta 4;
BA_ "UserSigValidity" SG_ 2424579841 DATC_WshFldUSMSta 7;
BA_ "Version" SG_ 2424579841 DATC_WshFldUSMSta "18.06.00";
BA_ "Description" SG_ 2424579841 DATC_DfgLgcUSMSta "This signal indicates USM States of DefLogic

(DEF ÇØÁ¦º¹±Í ·ÎÁ÷ USM ¼³Á¤°ª ¼Û½Å ½ÅÈ£)";
BA_ "GenSigSendType" SG_ 2424579841 DATC_DfgLgcUSMSta 4;
BA_ "GenSigStartValue" SG_ 2424579841 DATC_DfgLgcUSMSta 3;
BA_ "UserSigValidity" SG_ 2424579841 DATC_DfgLgcUSMSta 3;
BA_ "Version" SG_ 2424579841 DATC_DfgLgcUSMSta "18.07.03";
BA_ "Description" SG_ 2424579841 DATC_AutoFrshUSMSta "This signal indicates USM States of Auto Fresh

(°á·Î¹æÁö ÇØÁ¦ º¹±Í USM ¼³Á¤ »óÅÂ ¼Û½Å ½ÅÈ£)";
BA_ "GenSigSendType" SG_ 2424579841 DATC_AutoFrshUSMSta 4;
BA_ "GenSigStartValue" SG_ 2424579841 DATC_AutoFrshUSMSta 3;
BA_ "UserSigValidity" SG_ 2424579841 DATC_AutoFrshUSMSta 3;
BA_ "Version" SG_ 2424579841 DATC_AutoFrshUSMSta "18.07.03";
BA_ "Description" SG_ 2424579841 DATC_HptIntnstySta "This signal indicate the Haptic Intensity of Touch Button in the Heater Control.";
BA_ "GenSigSendType" SG_ 2424579841 DATC_HptIntnstySta 4;
BA_ "UserSigValidity" SG_ 2424579841 DATC_HptIntnstySta 7;
BA_ "Version" SG_ 2424579841 DATC_HptIntnstySta "18.11.01";
BA_ "Description" SG_ 2424579841 DATC_ClmtPwrSum_W "accumulated energy consumption while driving(200ms)";
BA_ "GenSigSendType" SG_ 2424579841 DATC_ClmtPwrSum_W 4;
BA_ "UserSigValidity" SG_ 2424579841 DATC_ClmtPwrSum_W 4;
BA_ "Version" SG_ 2424579841 DATC_ClmtPwrSum_W "18.09.00";
BA_ "GenMsgSendType" BO_ 687 0;
BA_ "GenMsgCycleTime" BO_ 687 100;
BA_ "GenMsgCycleTimeFast" BO_ 687 0;
BA_ "GenMsgNrOfRepetition" BO_ 687 0;
BA_ "Description" SG_ 687 HOD_Crc1Val "The data area for CRC calculation is based on the data length (DLC) of the message DB.

The CRC shall be calculated over the entire data block (excluding the CRC bytes) including the user data, alive counter and Data ID 

 

- CRC Polynomial (0x1D) , Initial Value : 0x00, XOR value : 0xFF, Data ID Mode : Both, Data ID : Message ID + 0xF800 

- The initial value is for CRC calculation and the message should be sent with the calculated result value. 

The mathematical expression to 8 bit CRC polynomial is given here. G(x) = x8 + x4 + x3 + x2 + 1";
BA_ "UserSigValidity" SG_ 687 HOD_Crc1Val 0;
BA_REL_ "GenSigTimeoutTime" BU_SG_REL_ CGW_CCU SG_ 687 HOD_Crc1Val 1500;
BA_ "Version" SG_ 687 HOD_Crc1Val "21.09.03";
BA_ "Description" SG_ 687 HOD_AlvCnt1Val "For the first transmission request for a data element the counter shall be initialized with 0 and shall be incremented by 1

for every subsequent send request. When the counter reaches the maximum value(0xE), then it shall restart with 0 for the next send request";
BA_ "UserSigValidity" SG_ 687 HOD_AlvCnt1Val 0;
BA_REL_ "GenSigTimeoutTime" BU_SG_REL_ CGW_CCU SG_ 687 HOD_AlvCnt1Val 1500;
BA_ "Version" SG_ 687 HOD_AlvCnt1Val "21.09.03";
BA_ "Description" SG_ 687 HOD_Dir_Status "This signal indicates the status of hands on/off";
BA_ "GenSigStartValue" SG_ 687 HOD_Dir_Status 7;
BA_ "UserSigValidity" SG_ 687 HOD_Dir_Status 0;
BA_REL_ "GenSigTimeoutTime" BU_SG_REL_ CGW_CCU SG_ 687 HOD_Dir_Status 1500;
BA_ "Version" SG_ 687 HOD_Dir_Status "21.07.05";
BA_ "Description" SG_ 687 HOD_Option "This signal is a checkable signal that the HOD is applied.

This signal should be fixed 0x1.";
BA_ "UserSigValidity" SG_ 687 HOD_Option 0;
BA_REL_ "GenSigTimeoutTime" BU_SG_REL_ CGW_CCU SG_ 687 HOD_Option 1500;
BA_ "Version" SG_ 687 HOD_Option "21.07.05";
BA_ "Description" SG_ 687 HOD_CapaCh0 "This signal is a Front Capacitance value(pF)";
BA_ "GenSigStartValue" SG_ 687 HOD_CapaCh0 255;
BA_ "UserSigValidity" SG_ 687 HOD_CapaCh0 0;
BA_REL_ "GenSigTimeoutTime" BU_SG_REL_ CGW_CCU SG_ 687 HOD_CapaCh0 1500;
BA_ "Version" SG_ 687 HOD_CapaCh0 "22.04.01";
BA_ "Description" SG_ 687 HOD_CapaCh1 "This signal is a Rear Capacitance value(pF)";
BA_ "GenSigStartValue" SG_ 687 HOD_CapaCh1 255;
BA_ "UserSigValidity" SG_ 687 HOD_CapaCh1 0;
BA_REL_ "GenSigTimeoutTime" BU_SG_REL_ CGW_CCU SG_ 687 HOD_CapaCh1 1500;
BA_ "Version" SG_ 687 HOD_CapaCh1 "22.04.01";
BA_ "Description" SG_ 687 HOD_HDPSpprtSWVer "This signal is revision of System Specification";
BA_ "GenSigStartValue" SG_ 687 HOD_HDPSpprtSWVer 31;
BA_ "UserSigValidity" SG_ 687 HOD_HDPSpprtSWVer 0;
BA_REL_ "GenSigTimeoutTime" BU_SG_REL_ CGW_CCU SG_ 687 HOD_HDPSpprtSWVer 1500;
BA_ "Version" SG_ 687 HOD_HDPSpprtSWVer "22.04.01";
BA_ "GenMsgSendType" BO_ 2176872450 0;
BA_ "GenMsgCycleTime" BO_ 2176872450 50;
BA_ "GenMsgCycleTimeFast" BO_ 2176872450 0;
BA_ "GenMsgNrOfRepetition" BO_ 2176872450 0;
BA_ "VFrameFormat" BO_ 2176872450 1;
BA_ "Description" SG_ 2176872450 HDCT_TCURdySta "Flag that the HTCU is ready to work. (In fact, this flag is true from the moment that CAN is working. So, normally no ¡°false¡± will be sent on CAN.) This flag does not show that everything is alright in the HTCU. This information is given in the warning and fault flags.";
BA_ "UserSigValidity" SG_ 2176872450 HDCT_TCURdySta 3;
BA_ "RoutingFactor" SG_ 2176872450 HDCT_TCURdySta 5;
BA_ "Version" SG_ 2176872450 HDCT_TCURdySta "19.10.01";
BA_ "Description" SG_ 2176872450 HDCT_NetrlCtrlSta "This signal indicates the status of Neutral Control Response.";
BA_ "UserSigValidity" SG_ 2176872450 HDCT_NetrlCtrlSta 3;
BA_ "RoutingFactor" SG_ 2176872450 HDCT_NetrlCtrlSta 5;
BA_ "Version" SG_ 2176872450 HDCT_NetrlCtrlSta "19.10.01";
BA_ "Description" SG_ 2176872450 HDCT_GearShftSta "HTCU_GearChgSta indicates whether a gear change is being executed in the gearbox.

Note : Gear change means a gear shift at D-range and Garage shift(PRND).";
BA_ "UserSigValidity" SG_ 2176872450 HDCT_GearShftSta 3;
BA_ "RoutingFactor" SG_ 2176872450 HDCT_GearShftSta 5;
BA_ "Version" SG_ 2176872450 HDCT_GearShftSta "19.10.01";
BA_ "Description" SG_ 2176872450 HDCT_TqRdctnVal "The HTCU requests a torque reduction via the signal CR_Tcu_TqInt_Pc to the ECU and MCU.

The requested torque HTCU_TqRdctnPcVal refers to a maximum torque CR_Ems_TqStd_Nm. This conversion into a physical quantity provides a range of CR_Ems_TqStd_Nm of 0 ..199.61%.

There is no specific phase relationship between the output and any other signal.

Conversion : (PH) = 0.390625 * (HEX) [%]";
BA_ "GenSigStartValue" SG_ 2176872450 HDCT_TqRdctnVal 1023;
BA_ "UserSigValidity" SG_ 2176872450 HDCT_TqRdctnVal 3;
BA_ "RoutingFactor" SG_ 2176872450 HDCT_TqRdctnVal 5;
BA_ "Version" SG_ 2176872450 HDCT_TqRdctnVal "20.05.02";
BA_ "Description" SG_ 2176872450 HDCT_CtrlablSta "CF_Tcu_Cont indicates the status of the HTCU control which normally works by hydraulic pressure in the T/M";
BA_ "UserSigValidity" SG_ 2176872450 HDCT_CtrlablSta 3;
BA_ "RoutingFactor" SG_ 2176872450 HDCT_CtrlablSta 5;
BA_ "Version" SG_ 2176872450 HDCT_CtrlablSta "19.10.01";
BA_ "Description" SG_ 2176872450 HTCU_SlwTqRdctnVal "The HTCU requests a slow torque reduction via the signal HTCU_TqRdctnPcVal to the ECU and MCU.";
BA_ "GenSigStartValue" SG_ 2176872450 HTCU_SlwTqRdctnVal 511;
BA_ "UserSigValidity" SG_ 2176872450 HTCU_SlwTqRdctnVal 3;
BA_ "RoutingFactor" SG_ 2176872450 HTCU_SlwTqRdctnVal 5;
BA_ "Version" SG_ 2176872450 HTCU_SlwTqRdctnVal "19.10.01";
BA_ "Description" SG_ 2176872450 HDCT_TqIncReq "An Identifier of a DCT HTCU controller for increasing torque intervention. 



This bit is to prevent the triggering of unintended DCT HTCU interventions.";
BA_ "UserSigValidity" SG_ 2176872450 HDCT_TqIncReq 3;
BA_ "RoutingFactor" SG_ 2176872450 HDCT_TqIncReq 5;
BA_ "Version" SG_ 2176872450 HDCT_TqIncReq "19.10.01";
BA_ "Description" SG_ 2176872450 HDCT_TqIncVal "The HTCU requests the engine RPM increase via the signal HTCU_TqIncPcVal to the EMS..

The requested torque HTCU_TqIncPcVal refers to maximum torque CR_Ems_TqStd_Nm. This conversion into a physical quantity provides a range of CR_Ems_TqStd_Nm of 0..99.6094%.";
BA_ "UserSigValidity" SG_ 2176872450 HDCT_TqIncVal 3;
BA_ "RoutingFactor" SG_ 2176872450 HDCT_TqIncVal 5;
BA_ "Version" SG_ 2176872450 HDCT_TqIncVal "20.05.02";
BA_ "Description" SG_ 2176872450 HDCT_TrgtShftCls "HTCU Shift Target Class";
BA_ "UserSigValidity" SG_ 2176872450 HDCT_TrgtShftCls 3;
BA_ "RoutingFactor" SG_ 2176872450 HDCT_TrgtShftCls 5;
BA_ "Version" SG_ 2176872450 HDCT_TrgtShftCls "19.10.01";
BA_ "UserSigValidity" SG_ 2176872450 HDCT_EOLReq 3;
BA_ "RoutingFactor" SG_ 2176872450 HDCT_EOLReq 5;
BA_ "Version" SG_ 2176872450 HDCT_EOLReq "19.10.01";
BA_ "Description" SG_ 2176872450 HDCT_CltchSta "Status of DCT clutches. This signal gives information about the frictional connection between the engine and the drive train.";
BA_ "UserSigValidity" SG_ 2176872450 HDCT_CltchSta 3;
BA_ "RoutingFactor" SG_ 2176872450 HDCT_CltchSta 5;
BA_ "Version" SG_ 2176872450 HDCT_CltchSta "19.10.01";
BA_ "UserSigValidity" SG_ 2176872450 HDCT_DblCltchSta 3;
BA_ "RoutingFactor" SG_ 2176872450 HDCT_DblCltchSta 5;
BA_ "Version" SG_ 2176872450 HDCT_DblCltchSta "19.10.01";
BA_ "Description" SG_ 2176872450 HDCT_AcnChrgInhbtReq "Inhibit changes of engine torque. e.g. by changing status of the air condition.";
BA_ "UserSigValidity" SG_ 2176872450 HDCT_AcnChrgInhbtReq 3;
BA_ "RoutingFactor" SG_ 2176872450 HDCT_AcnChrgInhbtReq 5;
BA_ "Version" SG_ 2176872450 HDCT_AcnChrgInhbtReq "19.10.01";
BA_ "UserSigValidity" SG_ 2176872450 HDCT_SlipCrnkAllw 3;
BA_ "RoutingFactor" SG_ 2176872450 HDCT_SlipCrnkAllw 5;
BA_ "Version" SG_ 2176872450 HDCT_SlipCrnkAllw "19.10.01";
BA_ "UserSigValidity" SG_ 2176872450 HDCT_KckDnSkpShftCnt 3;
BA_ "RoutingFactor" SG_ 2176872450 HDCT_KckDnSkpShftCnt 5;
BA_ "Version" SG_ 2176872450 HDCT_KckDnSkpShftCnt "19.10.01";
BA_ "Description" SG_ 2176872450 HDCT_ShftPhase "HDCT_ShftPhaseSta informs about control shift phase of the release element or apply element during shifting.";
BA_ "UserSigValidity" SG_ 2176872450 HDCT_ShftPhase 3;
BA_ "RoutingFactor" SG_ 2176872450 HDCT_ShftPhase 5;
BA_ "Version" SG_ 2176872450 HDCT_ShftPhase "19.10.01";
BA_ "GenMsgSendType" BO_ 2176872451 0;
BA_ "GenMsgCycleTime" BO_ 2176872451 50;
BA_ "GenMsgCycleTimeFast" BO_ 2176872451 0;
BA_ "GenMsgNrOfRepetition" BO_ 2176872451 0;
BA_ "VFrameFormat" BO_ 2176872451 1;
BA_ "Description" SG_ 2176872451 HDCT_FuelCutReq "Fuel Cut request bit signal to let EMS perform ¡®Fuel Cut torque intervention¡¯ during shift.";
BA_ "UserSigValidity" SG_ 2176872451 HDCT_FuelCutReq 3;
BA_ "RoutingFactor" SG_ 2176872451 HDCT_FuelCutReq 5;
BA_ "Version" SG_ 2176872451 HDCT_FuelCutReq "19.10.02";
BA_ "Description" SG_ 2176872451 HDCT_NCoastTrgtGear "Target Gear Information to Control of gN Coast Down";
BA_ "UserSigValidity" SG_ 2176872451 HDCT_NCoastTrgtGear 3;
BA_ "RoutingFactor" SG_ 2176872451 HDCT_NCoastTrgtGear 5;
BA_ "Version" SG_ 2176872451 HDCT_NCoastTrgtGear "19.10.02";
BA_ "Description" SG_ 2176872451 HDCT_CLUEngSpdFlag "Flag for Engine RPM(from ECU) Display on Cluster, Only when this flag is set to 1, Cluster shall display the Engine RPM from TCU";
BA_ "UserSigValidity" SG_ 2176872451 HDCT_CLUEngSpdFlag 3;
BA_ "RoutingFactor" SG_ 2176872451 HDCT_CLUEngSpdFlag 5;
BA_ "Version" SG_ 2176872451 HDCT_CLUEngSpdFlag "19.10.02";
BA_ "Description" SG_ 2176872451 HDCT_CLUTrgtGear "This target gear signal is only for Cluster.



It is different with HTCU_TrgtGearSta.";
BA_ "UserSigValidity" SG_ 2176872451 HDCT_CLUTrgtGear 3;
BA_ "RoutingFactor" SG_ 2176872451 HDCT_CLUTrgtGear 5;
BA_ "Version" SG_ 2176872451 HDCT_CLUTrgtGear "19.10.02";
BA_ "Description" SG_ 2176872451 HDCT_GSITrgtGear "Target Gear Information for Gear Shift Indicator";
BA_ "UserSigValidity" SG_ 2176872451 HDCT_GSITrgtGear 3;
BA_ "RoutingFactor" SG_ 2176872451 HDCT_GSITrgtGear 5;
BA_ "Version" SG_ 2176872451 HDCT_GSITrgtGear "19.10.02";
BA_ "Description" SG_ 2176872451 HDCT_NCoastDnReq "Act of gN Coast Down 

(Requested of Not Requested)";
BA_ "UserSigValidity" SG_ 2176872451 HDCT_NCoastDnReq 3;
BA_ "RoutingFactor" SG_ 2176872451 HDCT_NCoastDnReq 5;
BA_ "Version" SG_ 2176872451 HDCT_NCoastDnReq "19.10.02";
BA_ "Description" SG_ 2176872451 HDCT_CLUEngSpd "Engine RPM from TCU(only for the display on Cluster)";
BA_ "UserSigValidity" SG_ 2176872451 HDCT_CLUEngSpd 3;
BA_ "RoutingFactor" SG_ 2176872451 HDCT_CLUEngSpd 5;
BA_ "Version" SG_ 2176872451 HDCT_CLUEngSpd "19.10.02";
BA_ "GenMsgCycleTime" BO_ 1584 0;
BA_ "Description" SG_ 1584 AMP_NaviWarnSound "Navi Warning prompt on/off

Only ON during the Navi Warning Sound Playing

Default : Off

-This Signal's Feedback is AMP_NaviWarnModeState@AMP";
BA_ "GenSigSendType" SG_ 1584 AMP_NaviWarnSound 4;
BA_ "GenSigStartValue" SG_ 1584 AMP_NaviWarnSound 3;
BA_ "UserSigValidity" SG_ 1584 AMP_NaviWarnSound 1;
BA_ "Version" SG_ 1584 AMP_NaviWarnSound "21.04.10";
BA_ "Description" SG_ 1584 AMP_Beep1Mode "16.02.05_[Default Value]

0x0";
BA_ "GenSigSendType" SG_ 1584 AMP_Beep1Mode 4;
BA_ "GenSigStartValue" SG_ 1584 AMP_Beep1Mode 3;
BA_ "UserSigValidity" SG_ 1584 AMP_Beep1Mode 1;
BA_REL_ "GenSigTimeoutTime" BU_SG_REL_ ATS SG_ 1584 AMP_Beep1Mode 0;
BA_ "NetworkRequest" SG_ 1584 AMP_Beep1Mode 0;
BA_ "Version" SG_ 1584 AMP_Beep1Mode "18.12.06";
BA_ "Description" SG_ 1584 AMP_MasterBeepVolumeStep "MasterBeepVolumeStep (0/1/2/3/4/5)";
BA_ "GenSigSendType" SG_ 1584 AMP_MasterBeepVolumeStep 4;
BA_ "GenSigStartValue" SG_ 1584 AMP_MasterBeepVolumeStep 7;
BA_ "UserSigValidity" SG_ 1584 AMP_MasterBeepVolumeStep 1;
BA_ "NetworkRequest" SG_ 1584 AMP_MasterBeepVolumeStep 0;
BA_ "Version" SG_ 1584 AMP_MasterBeepVolumeStep "20.08.02";
BA_ "Description" SG_ 1584 AMP_RrTTSSound "This signal is  Rear TTS output state information";
BA_ "GenSigSendType" SG_ 1584 AMP_RrTTSSound 4;
BA_ "GenSigStartValue" SG_ 1584 AMP_RrTTSSound 3;
BA_ "UserSigValidity" SG_ 1584 AMP_RrTTSSound 1;
BA_ "Version" SG_ 1584 AMP_RrTTSSound "19.12.01";
BA_ "GenSigSendType" SG_ 1584 AMP_ASDMode 4;
BA_ "GenSigStartValue" SG_ 1584 AMP_ASDMode 7;
BA_ "UserSigValidity" SG_ 1584 AMP_ASDMode 1;
BA_ "NetworkRequest" SG_ 1584 AMP_ASDMode 0;
BA_ "Version" SG_ 1584 AMP_ASDMode "21.11.00";
BA_ "Description" SG_ 1584 AMP_ANCMode "18.03.08_";
BA_ "GenSigSendType" SG_ 1584 AMP_ANCMode 4;
BA_ "GenSigStartValue" SG_ 1584 AMP_ANCMode 3;
BA_ "UserSigValidity" SG_ 1584 AMP_ANCMode 1;
BA_ "Version" SG_ 1584 AMP_ANCMode "18.12.06";
BA_ "Description" SG_ 1584 AMP_VirtualVenueMode "Select VV mode";
BA_ "GenSigSendType" SG_ 1584 AMP_VirtualVenueMode 4;
BA_ "GenSigStartValue" SG_ 1584 AMP_VirtualVenueMode 7;
BA_ "UserSigValidity" SG_ 1584 AMP_VirtualVenueMode 1;
BA_ "NetworkRequest" SG_ 1584 AMP_VirtualVenueMode 0;
BA_ "Version" SG_ 1584 AMP_VirtualVenueMode "19.08.08";
BA_ "Description" SG_ 1584 AMP_QLIMode "Select QLI mode";
BA_ "GenSigSendType" SG_ 1584 AMP_QLIMode 4;
BA_ "GenSigStartValue" SG_ 1584 AMP_QLIMode 7;
BA_ "UserSigValidity" SG_ 1584 AMP_QLIMode 1;
BA_ "NetworkRequest" SG_ 1584 AMP_QLIMode 0;
BA_ "Version" SG_ 1584 AMP_QLIMode "19.08.08";
BA_ "Description" SG_ 1584 AMP_DriverMode "Turn On/Off Driver mode";
BA_ "GenSigSendType" SG_ 1584 AMP_DriverMode 4;
BA_ "GenSigStartValue" SG_ 1584 AMP_DriverMode 3;
BA_ "UserSigValidity" SG_ 1584 AMP_DriverMode 1;
BA_ "NetworkRequest" SG_ 1584 AMP_DriverMode 0;
BA_ "Version" SG_ 1584 AMP_DriverMode "19.08.08";
BA_ "Description" SG_ 1584 AMP_NaviSound "16.02.05_[Default Value]

0x0";
BA_ "GenSigSendType" SG_ 1584 AMP_NaviSound 4;
BA_ "GenSigStartValue" SG_ 1584 AMP_NaviSound 3;
BA_ "UserSigValidity" SG_ 1584 AMP_NaviSound 1;
BA_ "Version" SG_ 1584 AMP_NaviSound "19.01.05";
BA_ "Description" SG_ 1584 AMP_ETCSSound "ETCS sound on/off

Only ON during the ETCS sound playing

Default : Off

-This Signal's Feedback is AMP_ETCSModeState@AMP";
BA_ "GenSigSendType" SG_ 1584 AMP_ETCSSound 4;
BA_ "GenSigStartValue" SG_ 1584 AMP_ETCSSound 3;
BA_ "UserSigValidity" SG_ 1584 AMP_ETCSSound 1;
BA_ "Version" SG_ 1584 AMP_ETCSSound "22.05.02";
BA_ "Description" SG_ 1584 AMP_VoiceGuideTTS "Play VoiceGuide TTS";
BA_ "GenSigSendType" SG_ 1584 AMP_VoiceGuideTTS 4;
BA_ "GenSigStartValue" SG_ 1584 AMP_VoiceGuideTTS 3;
BA_ "UserSigValidity" SG_ 1584 AMP_VoiceGuideTTS 1;
BA_ "NetworkRequest" SG_ 1584 AMP_VoiceGuideTTS 0;
BA_ "Version" SG_ 1584 AMP_VoiceGuideTTS "21.11.00";
BA_ "Description" SG_ 1584 AMP_Beep1KBDMode "Play touch beep sound at keyboard screen on AVN

This Signal's Feedback is AMP_Beep1KBDModeState@AMP";
BA_ "GenSigSendType" SG_ 1584 AMP_Beep1KBDMode 4;
BA_ "GenSigStartValue" SG_ 1584 AMP_Beep1KBDMode 3;
BA_ "UserSigValidity" SG_ 1584 AMP_Beep1KBDMode 1;
BA_ "Version" SG_ 1584 AMP_Beep1KBDMode "20.06.01";
BA_ "Description" SG_ 1584 AMP_ETCSVolumeStep "- Command for ETCS Volume Setting

- This Signal's Feedback is AMP_ETCSVolumeState@AMP";
BA_ "GenSigSendType" SG_ 1584 AMP_ETCSVolumeStep 4;
BA_ "GenSigStartValue" SG_ 1584 AMP_ETCSVolumeStep 255;
BA_ "UserSigValidity" SG_ 1584 AMP_ETCSVolumeStep 1;
BA_ "Version" SG_ 1584 AMP_ETCSVolumeStep "22.05.02";
BA_ "Description" SG_ 1584 AMP_NaviWarnVolumeStep "- Command for Navigation Warning Prompt Volume Setting

- This Signal's Feedback is AMP_NaviWarnVolumeState@AMP";
BA_ "GenSigSendType" SG_ 1584 AMP_NaviWarnVolumeStep 4;
BA_ "GenSigStartValue" SG_ 1584 AMP_NaviWarnVolumeStep 255;
BA_ "UserSigValidity" SG_ 1584 AMP_NaviWarnVolumeStep 1;
BA_ "Version" SG_ 1584 AMP_NaviWarnVolumeStep "21.04.10";
BA_ "Description" SG_ 1584 AMP_TTSSound "This signal is  TTS output state information";
BA_ "GenSigSendType" SG_ 1584 AMP_TTSSound 4;
BA_ "GenSigStartValue" SG_ 1584 AMP_TTSSound 3;
BA_ "UserSigValidity" SG_ 1584 AMP_TTSSound 1;
BA_ "Version" SG_ 1584 AMP_TTSSound "19.07.06";
BA_ "GenSigSendType" SG_ 1584 AMP_SDVCStep 4;
BA_ "UserSigValidity" SG_ 1584 AMP_SDVCStep 1;
BA_ "NetworkRequest" SG_ 1584 AMP_SDVCStep 0;
BA_ "Version" SG_ 1584 AMP_SDVCStep "21.11.00";
BA_ "GenMsgCycleTime" BO_ 676 0;
BA_ "Description" SG_ 676 C_DrAirSptNValueSet_EC "Driver Seat Smart Air Support On/Off";
BA_ "GenSigSendType" SG_ 676 C_DrAirSptNValueSet_EC 4;
BA_ "UserSigValidity" SG_ 676 C_DrAirSptNValueSet_EC 0;
BA_REL_ "GenSigTimeoutTime" BU_SG_REL_ DSAU SG_ 676 C_DrAirSptNValueSet_EC 0;
BA_REL_ "GenSigTimeoutTime" BU_SG_REL_ GW_DPSU SG_ 676 C_DrAirSptNValueSet_EC 0;
BA_ "Version" SG_ 676 C_DrAirSptNValueSet_EC "20.02.03";
BA_ "Description" SG_ 676 C_DrCushSoftNValueSet_EC "Driver Seat Cushion Softness";
BA_ "GenSigSendType" SG_ 676 C_DrCushSoftNValueSet_EC 4;
BA_ "UserSigValidity" SG_ 676 C_DrCushSoftNValueSet_EC 0;
BA_REL_ "GenSigTimeoutTime" BU_SG_REL_ DSAU SG_ 676 C_DrCushSoftNValueSet_EC 0;
BA_REL_ "GenSigTimeoutTime" BU_SG_REL_ GW_DPSU SG_ 676 C_DrCushSoftNValueSet_EC 0;
BA_ "Version" SG_ 676 C_DrCushSoftNValueSet_EC "20.02.03";
BA_ "Description" SG_ 676 C_AstAirSptNValueSet_EC "Assistant Seat Smart Air Support On/Off";
BA_ "GenSigSendType" SG_ 676 C_AstAirSptNValueSet_EC 4;
BA_ "UserSigValidity" SG_ 676 C_AstAirSptNValueSet_EC 0;
BA_REL_ "GenSigTimeoutTime" BU_SG_REL_ ASAU SG_ 676 C_AstAirSptNValueSet_EC 0;
BA_REL_ "GenSigTimeoutTime" BU_SG_REL_ GW_APSU SG_ 676 C_AstAirSptNValueSet_EC 0;
BA_ "Version" SG_ 676 C_AstAirSptNValueSet_EC "20.02.03";
BA_ "Description" SG_ 676 C_AstAirSptModeNValueSet_EC "Assistant Seat Smart Air Support Mode";
BA_ "GenSigSendType" SG_ 676 C_AstAirSptModeNValueSet_EC 4;
BA_ "UserSigValidity" SG_ 676 C_AstAirSptModeNValueSet_EC 0;
BA_REL_ "GenSigTimeoutTime" BU_SG_REL_ ASAU SG_ 676 C_AstAirSptModeNValueSet_EC 0;
BA_REL_ "GenSigTimeoutTime" BU_SG_REL_ GW_APSU SG_ 676 C_AstAirSptModeNValueSet_EC 0;
BA_ "Version" SG_ 676 C_AstAirSptModeNValueSet_EC "20.02.03";
BA_ "Description" SG_ 676 C_DrAirSptModeNValueSet_EC "Driver Seat Smart Air Support Mode";
BA_ "GenSigSendType" SG_ 676 C_DrAirSptModeNValueSet_EC 4;
BA_ "UserSigValidity" SG_ 676 C_DrAirSptModeNValueSet_EC 0;
BA_REL_ "GenSigTimeoutTime" BU_SG_REL_ DSAU SG_ 676 C_DrAirSptModeNValueSet_EC 0;
BA_REL_ "GenSigTimeoutTime" BU_SG_REL_ GW_DPSU SG_ 676 C_DrAirSptModeNValueSet_EC 0;
BA_ "Version" SG_ 676 C_DrAirSptModeNValueSet_EC "20.02.03";
BA_ "Description" SG_ 676 C_RLAirSptNValueSet_EC "2nd Left Seat Smart Air Support On/Off";
BA_ "GenSigSendType" SG_ 676 C_RLAirSptNValueSet_EC 4;
BA_ "UserSigValidity" SG_ 676 C_RLAirSptNValueSet_EC 0;
BA_REL_ "GenSigTimeoutTime" BU_SG_REL_ ATS SG_ 676 C_RLAirSptNValueSet_EC 0;
BA_REL_ "GenSigTimeoutTime" BU_SG_REL_ GW_RLPSU SG_ 676 C_RLAirSptNValueSet_EC 0;
BA_ "Version" SG_ 676 C_RLAirSptNValueSet_EC "20.02.03";
BA_ "Description" SG_ 676 C_AstAirSptStrNValueSet_EC "Assistant Seat Smart Air Support Strength";
BA_ "GenSigSendType" SG_ 676 C_AstAirSptStrNValueSet_EC 4;
BA_ "UserSigValidity" SG_ 676 C_AstAirSptStrNValueSet_EC 0;
BA_REL_ "GenSigTimeoutTime" BU_SG_REL_ ASAU SG_ 676 C_AstAirSptStrNValueSet_EC 0;
BA_REL_ "GenSigTimeoutTime" BU_SG_REL_ GW_APSU SG_ 676 C_AstAirSptStrNValueSet_EC 0;
BA_ "Version" SG_ 676 C_AstAirSptStrNValueSet_EC "20.02.03";
BA_ "Description" SG_ 676 C_AstAirSptTimeNValueSet_EC "Assistant Seat Smart Air Support Time";
BA_ "GenSigSendType" SG_ 676 C_AstAirSptTimeNValueSet_EC 4;
BA_ "UserSigValidity" SG_ 676 C_AstAirSptTimeNValueSet_EC 0;
BA_REL_ "GenSigTimeoutTime" BU_SG_REL_ ASAU SG_ 676 C_AstAirSptTimeNValueSet_EC 0;
BA_REL_ "GenSigTimeoutTime" BU_SG_REL_ GW_APSU SG_ 676 C_AstAirSptTimeNValueSet_EC 0;
BA_ "Version" SG_ 676 C_AstAirSptTimeNValueSet_EC "20.02.03";
BA_ "Description" SG_ 676 C_RRAirSptNValueSet_EC "2nd Right side seat Smart Air Support On/Off";
BA_ "GenSigSendType" SG_ 676 C_RRAirSptNValueSet_EC 4;
BA_ "UserSigValidity" SG_ 676 C_RRAirSptNValueSet_EC 0;
BA_REL_ "GenSigTimeoutTime" BU_SG_REL_ ATS SG_ 676 C_RRAirSptNValueSet_EC 0;
BA_REL_ "GenSigTimeoutTime" BU_SG_REL_ GW_RRPSU SG_ 676 C_RRAirSptNValueSet_EC 0;
BA_ "Version" SG_ 676 C_RRAirSptNValueSet_EC "20.02.03";
BA_ "Description" SG_ 676 C_AstCushSoftNValueSet_EC "Assistant Seat Cushion Softness off/low/mid/high";
BA_ "GenSigSendType" SG_ 676 C_AstCushSoftNValueSet_EC 4;
BA_ "UserSigValidity" SG_ 676 C_AstCushSoftNValueSet_EC 0;
BA_REL_ "GenSigTimeoutTime" BU_SG_REL_ ASAU SG_ 676 C_AstCushSoftNValueSet_EC 0;
BA_REL_ "GenSigTimeoutTime" BU_SG_REL_ GW_APSU SG_ 676 C_AstCushSoftNValueSet_EC 0;
BA_ "Version" SG_ 676 C_AstCushSoftNValueSet_EC "20.02.03";
BA_ "Description" SG_ 676 C_AstRlxNValueSet_EC "Assistant seat Moving control : Relaxtion mode";
BA_ "GenSigSendType" SG_ 676 C_AstRlxNValueSet_EC 4;
BA_ "UserSigValidity" SG_ 676 C_AstRlxNValueSet_EC 0;
BA_REL_ "GenSigTimeoutTime" BU_SG_REL_ GW_APSU SG_ 676 C_AstRlxNValueSet_EC 0;
BA_ "Version" SG_ 676 C_AstRlxNValueSet_EC "20.02.03";
BA_ "Description" SG_ 676 C_RLAirSptModeNValueSet_EC "2nd Left Seat Smart Air Support Mode";
BA_ "GenSigSendType" SG_ 676 C_RLAirSptModeNValueSet_EC 4;
BA_ "UserSigValidity" SG_ 676 C_RLAirSptModeNValueSet_EC 0;
BA_REL_ "GenSigTimeoutTime" BU_SG_REL_ ATS SG_ 676 C_RLAirSptModeNValueSet_EC 0;
BA_REL_ "GenSigTimeoutTime" BU_SG_REL_ GW_RLPSU SG_ 676 C_RLAirSptModeNValueSet_EC 0;
BA_ "Version" SG_ 676 C_RLAirSptModeNValueSet_EC "20.02.03";
BA_ "Description" SG_ 676 C_DrAirSptStrNValueSet_EC "Driver Seat Smart Air Support Strength";
BA_ "GenSigSendType" SG_ 676 C_DrAirSptStrNValueSet_EC 4;
BA_ "UserSigValidity" SG_ 676 C_DrAirSptStrNValueSet_EC 0;
BA_REL_ "GenSigTimeoutTime" BU_SG_REL_ DSAU SG_ 676 C_DrAirSptStrNValueSet_EC 0;
BA_REL_ "GenSigTimeoutTime" BU_SG_REL_ GW_DPSU SG_ 676 C_DrAirSptStrNValueSet_EC 0;
BA_ "Version" SG_ 676 C_DrAirSptStrNValueSet_EC "20.02.03";
BA_ "Description" SG_ 676 C_RLAirSptStrNValueSet_EC "2nd Left Seat Smart Air Support Strength";
BA_ "GenSigSendType" SG_ 676 C_RLAirSptStrNValueSet_EC 4;
BA_ "UserSigValidity" SG_ 676 C_RLAirSptStrNValueSet_EC 0;
BA_REL_ "GenSigTimeoutTime" BU_SG_REL_ ATS SG_ 676 C_RLAirSptStrNValueSet_EC 0;
BA_REL_ "GenSigTimeoutTime" BU_SG_REL_ GW_RLPSU SG_ 676 C_RLAirSptStrNValueSet_EC 0;
BA_ "Version" SG_ 676 C_RLAirSptStrNValueSet_EC "20.02.03";
BA_ "Description" SG_ 676 C_RLAirSptTimeNValueSet_EC "2nd Left Seat Smart Air Support Time";
BA_ "GenSigSendType" SG_ 676 C_RLAirSptTimeNValueSet_EC 4;
BA_ "UserSigValidity" SG_ 676 C_RLAirSptTimeNValueSet_EC 0;
BA_REL_ "GenSigTimeoutTime" BU_SG_REL_ ATS SG_ 676 C_RLAirSptTimeNValueSet_EC 0;
BA_REL_ "GenSigTimeoutTime" BU_SG_REL_ GW_RLPSU SG_ 676 C_RLAirSptTimeNValueSet_EC 0;
BA_ "Version" SG_ 676 C_RLAirSptTimeNValueSet_EC "20.02.03";
BA_ "Description" SG_ 676 C_DrAirSptTimeNValueSet_EC "Driver Seat Smart Air Support Time";
BA_ "GenSigSendType" SG_ 676 C_DrAirSptTimeNValueSet_EC 4;
BA_ "UserSigValidity" SG_ 676 C_DrAirSptTimeNValueSet_EC 0;
BA_REL_ "GenSigTimeoutTime" BU_SG_REL_ DSAU SG_ 676 C_DrAirSptTimeNValueSet_EC 0;
BA_REL_ "GenSigTimeoutTime" BU_SG_REL_ GW_DPSU SG_ 676 C_DrAirSptTimeNValueSet_EC 0;
BA_ "Version" SG_ 676 C_DrAirSptTimeNValueSet_EC "20.02.03";
BA_ "GenMsgCycleTime" BO_ 677 0;
BA_ "Description" SG_ 677 C_RRAirSptStrNValueSet_EC "2nd Right side seat Smart Air Support Strength";
BA_ "GenSigSendType" SG_ 677 C_RRAirSptStrNValueSet_EC 4;
BA_ "UserSigValidity" SG_ 677 C_RRAirSptStrNValueSet_EC 0;
BA_REL_ "GenSigTimeoutTime" BU_SG_REL_ ATS SG_ 677 C_RRAirSptStrNValueSet_EC 0;
BA_REL_ "GenSigTimeoutTime" BU_SG_REL_ GW_RRPSU SG_ 677 C_RRAirSptStrNValueSet_EC 0;
BA_ "Version" SG_ 677 C_RRAirSptStrNValueSet_EC "20.02.03";
BA_ "Description" SG_ 677 C_RRAirSptTimeNValueSet_EC "2nd Right side seat Smart Air Support Time";
BA_ "GenSigSendType" SG_ 677 C_RRAirSptTimeNValueSet_EC 4;
BA_ "UserSigValidity" SG_ 677 C_RRAirSptTimeNValueSet_EC 0;
BA_REL_ "GenSigTimeoutTime" BU_SG_REL_ ATS SG_ 677 C_RRAirSptTimeNValueSet_EC 0;
BA_REL_ "GenSigTimeoutTime" BU_SG_REL_ GW_RRPSU SG_ 677 C_RRAirSptTimeNValueSet_EC 0;
BA_ "Version" SG_ 677 C_RRAirSptTimeNValueSet_EC "20.02.03";
BA_ "Description" SG_ 677 C_RROneTchNvalueSet_EC "2nd Right side seat One Touch Mode";
BA_ "GenSigSendType" SG_ 677 C_RROneTchNvalueSet_EC 4;
BA_ "UserSigValidity" SG_ 677 C_RROneTchNvalueSet_EC 0;
BA_REL_ "GenSigTimeoutTime" BU_SG_REL_ ATS SG_ 677 C_RROneTchNvalueSet_EC 0;
BA_REL_ "GenSigTimeoutTime" BU_SG_REL_ GW_APSU SG_ 677 C_RROneTchNvalueSet_EC 0;
BA_REL_ "GenSigTimeoutTime" BU_SG_REL_ GW_RRPSU SG_ 677 C_RROneTchNvalueSet_EC 0;
BA_ "Version" SG_ 677 C_RROneTchNvalueSet_EC "20.02.03";
BA_ "Description" SG_ 677 C_RLOneTchNValueSet_EC "2nd Left side seat One Touch Mode";
BA_ "GenSigSendType" SG_ 677 C_RLOneTchNValueSet_EC 4;
BA_ "UserSigValidity" SG_ 677 C_RLOneTchNValueSet_EC 0;
BA_REL_ "GenSigTimeoutTime" BU_SG_REL_ ATS SG_ 677 C_RLOneTchNValueSet_EC 0;
BA_REL_ "GenSigTimeoutTime" BU_SG_REL_ GW_RLPSU SG_ 677 C_RLOneTchNValueSet_EC 0;
BA_REL_ "GenSigTimeoutTime" BU_SG_REL_ GW_RRPSU SG_ 677 C_RLOneTchNValueSet_EC 0;
BA_ "Version" SG_ 677 C_RLOneTchNValueSet_EC "20.02.03";
BA_ "Description" SG_ 677 C_RLOneTchNValueSet_EC_VR "2nd Left side seat One Touch Mode only for VR scenario";
BA_ "GenSigSendType" SG_ 677 C_RLOneTchNValueSet_EC_VR 4;
BA_ "UserSigValidity" SG_ 677 C_RLOneTchNValueSet_EC_VR 0;
BA_REL_ "GenSigTimeoutTime" BU_SG_REL_ GW_RLPSU SG_ 677 C_RLOneTchNValueSet_EC_VR 0;
BA_ "Version" SG_ 677 C_RLOneTchNValueSet_EC_VR "23.02.02";
BA_ "Description" SG_ 677 C_RROneTchNvalueSet_EC_VR "2nd Right side seat One Touch Mode only for VR scenario";
BA_ "GenSigSendType" SG_ 677 C_RROneTchNvalueSet_EC_VR 4;
BA_ "UserSigValidity" SG_ 677 C_RROneTchNvalueSet_EC_VR 0;
BA_REL_ "GenSigTimeoutTime" BU_SG_REL_ GW_RRPSU SG_ 677 C_RROneTchNvalueSet_EC_VR 0;
BA_ "Version" SG_ 677 C_RROneTchNvalueSet_EC_VR "23.02.02";
BA_ "Description" SG_ 677 C_RRAirSptModeNValueSet_EC "2nd Right side seat Moving control : Smart Air Support Mode";
BA_ "GenSigSendType" SG_ 677 C_RRAirSptModeNValueSet_EC 4;
BA_ "UserSigValidity" SG_ 677 C_RRAirSptModeNValueSet_EC 0;
BA_REL_ "GenSigTimeoutTime" BU_SG_REL_ ATS SG_ 677 C_RRAirSptModeNValueSet_EC 0;
BA_REL_ "GenSigTimeoutTime" BU_SG_REL_ GW_RRPSU SG_ 677 C_RRAirSptModeNValueSet_EC 0;
BA_ "Version" SG_ 677 C_RRAirSptModeNValueSet_EC "20.02.03";
BA_ "GenMsgSendType" BO_ 577 0;
BA_ "GenSigSendType" SG_ 577 C_AstBolsterInfSw_HU 4;
BA_ "UserSigValidity" SG_ 577 C_AstBolsterInfSw_HU 0;
BA_REL_ "GenSigTimeoutTime" BU_SG_REL_ ALBCU SG_ 577 C_AstBolsterInfSw_HU 1500;
BA_REL_ "GenSigTimeoutTime" BU_SG_REL_ ASAU SG_ 577 C_AstBolsterInfSw_HU 1500;
BA_REL_ "GenSigTimeoutTime" BU_SG_REL_ GW_APSU SG_ 577 C_AstBolsterInfSw_HU 1500;
BA_ "Version" SG_ 577 C_AstBolsterInfSw_HU "22.07.05";
BA_ "GenSigSendType" SG_ 577 C_RLHrestUpSw_HU 4;
BA_ "UserSigValidity" SG_ 577 C_RLHrestUpSw_HU 0;
BA_REL_ "GenSigTimeoutTime" BU_SG_REL_ GW_APSU SG_ 577 C_RLHrestUpSw_HU 1500;
BA_REL_ "GenSigTimeoutTime" BU_SG_REL_ GW_RLPSU SG_ 577 C_RLHrestUpSw_HU 1500;
BA_ "Version" SG_ 577 C_RLHrestUpSw_HU "22.07.05";
BA_ "GenSigSendType" SG_ 577 C_RLHrestDnSw_HU 4;
BA_ "UserSigValidity" SG_ 577 C_RLHrestDnSw_HU 0;
BA_REL_ "GenSigTimeoutTime" BU_SG_REL_ GW_APSU SG_ 577 C_RLHrestDnSw_HU 1500;
BA_REL_ "GenSigTimeoutTime" BU_SG_REL_ GW_RLPSU SG_ 577 C_RLHrestDnSw_HU 1500;
BA_ "Version" SG_ 577 C_RLHrestDnSw_HU "22.07.05";
BA_ "GenSigSendType" SG_ 577 C_RLHrestFwdSw_HU 4;
BA_ "UserSigValidity" SG_ 577 C_RLHrestFwdSw_HU 0;
BA_REL_ "GenSigTimeoutTime" BU_SG_REL_ GW_APSU SG_ 577 C_RLHrestFwdSw_HU 1500;
BA_REL_ "GenSigTimeoutTime" BU_SG_REL_ GW_RLPSU SG_ 577 C_RLHrestFwdSw_HU 1500;
BA_ "Version" SG_ 577 C_RLHrestFwdSw_HU "22.07.05";
BA_ "GenSigSendType" SG_ 577 C_AstBolsterDefSw_HU 4;
BA_ "UserSigValidity" SG_ 577 C_AstBolsterDefSw_HU 0;
BA_REL_ "GenSigTimeoutTime" BU_SG_REL_ ALBCU SG_ 577 C_AstBolsterDefSw_HU 1500;
BA_REL_ "GenSigTimeoutTime" BU_SG_REL_ ASAU SG_ 577 C_AstBolsterDefSw_HU 1500;
BA_REL_ "GenSigTimeoutTime" BU_SG_REL_ GW_APSU SG_ 577 C_AstBolsterDefSw_HU 1500;
BA_ "Version" SG_ 577 C_AstBolsterDefSw_HU "22.07.05";
BA_ "GenSigSendType" SG_ 577 C_RLHrestBwdSw_HU 4;
BA_ "UserSigValidity" SG_ 577 C_RLHrestBwdSw_HU 0;
BA_REL_ "GenSigTimeoutTime" BU_SG_REL_ GW_APSU SG_ 577 C_RLHrestBwdSw_HU 1500;
BA_REL_ "GenSigTimeoutTime" BU_SG_REL_ GW_RLPSU SG_ 577 C_RLHrestBwdSw_HU 1500;
BA_ "Version" SG_ 577 C_RLHrestBwdSw_HU "22.07.05";
BA_ "GenSigSendType" SG_ 577 C_RLLumbarUpSw_HU 4;
BA_ "UserSigValidity" SG_ 577 C_RLLumbarUpSw_HU 0;
BA_REL_ "GenSigTimeoutTime" BU_SG_REL_ GW_RLPSU SG_ 577 C_RLLumbarUpSw_HU 1500;
BA_ "Version" SG_ 577 C_RLLumbarUpSw_HU "22.07.05";
BA_ "GenSigSendType" SG_ 577 C_RLLumbarMidSw_HU 4;
BA_ "UserSigValidity" SG_ 577 C_RLLumbarMidSw_HU 0;
BA_REL_ "GenSigTimeoutTime" BU_SG_REL_ GW_RLPSU SG_ 577 C_RLLumbarMidSw_HU 1500;
BA_ "Version" SG_ 577 C_RLLumbarMidSw_HU "22.07.05";
BA_ "GenSigSendType" SG_ 577 C_RLLumbarLowSw_HU 4;
BA_ "UserSigValidity" SG_ 577 C_RLLumbarLowSw_HU 0;
BA_REL_ "GenSigTimeoutTime" BU_SG_REL_ GW_RLPSU SG_ 577 C_RLLumbarLowSw_HU 1500;
BA_ "Version" SG_ 577 C_RLLumbarLowSw_HU "22.07.05";
BA_ "GenSigSendType" SG_ 577 C_RLLumbarDefSw_HU 4;
BA_ "UserSigValidity" SG_ 577 C_RLLumbarDefSw_HU 0;
BA_REL_ "GenSigTimeoutTime" BU_SG_REL_ GW_RLPSU SG_ 577 C_RLLumbarDefSw_HU 1500;
BA_ "Version" SG_ 577 C_RLLumbarDefSw_HU "22.07.05";
BA_ "GenSigSendType" SG_ 577 C_RLBolsterInfSw_HU 4;
BA_ "UserSigValidity" SG_ 577 C_RLBolsterInfSw_HU 0;
BA_REL_ "GenSigTimeoutTime" BU_SG_REL_ GW_RLPSU SG_ 577 C_RLBolsterInfSw_HU 1500;
BA_ "Version" SG_ 577 C_RLBolsterInfSw_HU "22.07.05";
BA_ "GenSigSendType" SG_ 577 C_RLBolsterDefSw_HU 4;
BA_ "UserSigValidity" SG_ 577 C_RLBolsterDefSw_HU 0;
BA_REL_ "GenSigTimeoutTime" BU_SG_REL_ GW_RLPSU SG_ 577 C_RLBolsterDefSw_HU 1500;
BA_ "Version" SG_ 577 C_RLBolsterDefSw_HU "22.07.05";
BA_ "GenSigSendType" SG_ 577 C_AstHrestUpSw_HU 4;
BA_ "UserSigValidity" SG_ 577 C_AstHrestUpSw_HU 0;
BA_REL_ "GenSigTimeoutTime" BU_SG_REL_ GW_APSU SG_ 577 C_AstHrestUpSw_HU 1500;
BA_ "Version" SG_ 577 C_AstHrestUpSw_HU "22.07.05";
BA_ "GenSigSendType" SG_ 577 C_AstHrestDnSw_HU 4;
BA_ "UserSigValidity" SG_ 577 C_AstHrestDnSw_HU 0;
BA_REL_ "GenSigTimeoutTime" BU_SG_REL_ GW_APSU SG_ 577 C_AstHrestDnSw_HU 1500;
BA_ "Version" SG_ 577 C_AstHrestDnSw_HU "22.07.05";
BA_ "GenSigSendType" SG_ 577 C_AstHrestFwdSw_HU 4;
BA_ "UserSigValidity" SG_ 577 C_AstHrestFwdSw_HU 0;
BA_REL_ "GenSigTimeoutTime" BU_SG_REL_ GW_APSU SG_ 577 C_AstHrestFwdSw_HU 1500;
BA_ "Version" SG_ 577 C_AstHrestFwdSw_HU "22.07.05";
BA_ "GenSigSendType" SG_ 577 C_AstHrestBwdSw_HU 4;
BA_ "UserSigValidity" SG_ 577 C_AstHrestBwdSw_HU 0;
BA_REL_ "GenSigTimeoutTime" BU_SG_REL_ GW_APSU SG_ 577 C_AstHrestBwdSw_HU 1500;
BA_ "Version" SG_ 577 C_AstHrestBwdSw_HU "22.07.05";
BA_ "GenMsgSendType" BO_ 578 0;
BA_ "GenSigSendType" SG_ 578 C_RRLegSupFwdSw_HU 4;
BA_ "UserSigValidity" SG_ 578 C_RRLegSupFwdSw_HU 0;
BA_REL_ "GenSigTimeoutTime" BU_SG_REL_ GW_APSU SG_ 578 C_RRLegSupFwdSw_HU 1500;
BA_REL_ "GenSigTimeoutTime" BU_SG_REL_ GW_RRPSU SG_ 578 C_RRLegSupFwdSw_HU 1500;
BA_ "Version" SG_ 578 C_RRLegSupFwdSw_HU "22.07.05";
BA_ "GenSigSendType" SG_ 578 C_RRHrestDnSw_HU 4;
BA_ "UserSigValidity" SG_ 578 C_RRHrestDnSw_HU 0;
BA_REL_ "GenSigTimeoutTime" BU_SG_REL_ GW_APSU SG_ 578 C_RRHrestDnSw_HU 1500;
BA_REL_ "GenSigTimeoutTime" BU_SG_REL_ GW_RRPSU SG_ 578 C_RRHrestDnSw_HU 1500;
BA_ "Version" SG_ 578 C_RRHrestDnSw_HU "22.07.05";
BA_ "GenSigSendType" SG_ 578 C_RRHrestFwdSw_HU 4;
BA_ "UserSigValidity" SG_ 578 C_RRHrestFwdSw_HU 0;
BA_REL_ "GenSigTimeoutTime" BU_SG_REL_ GW_APSU SG_ 578 C_RRHrestFwdSw_HU 1500;
BA_REL_ "GenSigTimeoutTime" BU_SG_REL_ GW_RRPSU SG_ 578 C_RRHrestFwdSw_HU 1500;
BA_ "Version" SG_ 578 C_RRHrestFwdSw_HU "22.07.05";
BA_ "GenSigSendType" SG_ 578 C_RRHrestBwdSw_HU 4;
BA_ "UserSigValidity" SG_ 578 C_RRHrestBwdSw_HU 0;
BA_REL_ "GenSigTimeoutTime" BU_SG_REL_ GW_APSU SG_ 578 C_RRHrestBwdSw_HU 1500;
BA_REL_ "GenSigTimeoutTime" BU_SG_REL_ GW_RRPSU SG_ 578 C_RRHrestBwdSw_HU 1500;
BA_ "Version" SG_ 578 C_RRHrestBwdSw_HU "22.07.05";
BA_ "GenSigSendType" SG_ 578 C_RRLumbarUpSw_HU 4;
BA_ "UserSigValidity" SG_ 578 C_RRLumbarUpSw_HU 0;
BA_REL_ "GenSigTimeoutTime" BU_SG_REL_ GW_APSU SG_ 578 C_RRLumbarUpSw_HU 1500;
BA_REL_ "GenSigTimeoutTime" BU_SG_REL_ GW_RRPSU SG_ 578 C_RRLumbarUpSw_HU 1500;
BA_ "Version" SG_ 578 C_RRLumbarUpSw_HU "22.07.05";
BA_ "GenSigSendType" SG_ 578 C_RRLumbarMidSw_HU 4;
BA_ "UserSigValidity" SG_ 578 C_RRLumbarMidSw_HU 0;
BA_REL_ "GenSigTimeoutTime" BU_SG_REL_ GW_APSU SG_ 578 C_RRLumbarMidSw_HU 1500;
BA_REL_ "GenSigTimeoutTime" BU_SG_REL_ GW_RRPSU SG_ 578 C_RRLumbarMidSw_HU 1500;
BA_ "Version" SG_ 578 C_RRLumbarMidSw_HU "22.07.05";
BA_ "GenSigSendType" SG_ 578 C_RRLegSupBwdSw_HU 4;
BA_ "UserSigValidity" SG_ 578 C_RRLegSupBwdSw_HU 0;
BA_REL_ "GenSigTimeoutTime" BU_SG_REL_ GW_APSU SG_ 578 C_RRLegSupBwdSw_HU 1500;
BA_REL_ "GenSigTimeoutTime" BU_SG_REL_ GW_RRPSU SG_ 578 C_RRLegSupBwdSw_HU 1500;
BA_ "Version" SG_ 578 C_RRLegSupBwdSw_HU "22.07.05";
BA_ "GenSigSendType" SG_ 578 C_RRLumbarLowSw_HU 4;
BA_ "UserSigValidity" SG_ 578 C_RRLumbarLowSw_HU 0;
BA_REL_ "GenSigTimeoutTime" BU_SG_REL_ GW_APSU SG_ 578 C_RRLumbarLowSw_HU 1500;
BA_REL_ "GenSigTimeoutTime" BU_SG_REL_ GW_RRPSU SG_ 578 C_RRLumbarLowSw_HU 1500;
BA_ "Version" SG_ 578 C_RRLumbarLowSw_HU "22.07.05";
BA_ "GenSigSendType" SG_ 578 C_RRLumbarDefSw_HU 4;
BA_ "UserSigValidity" SG_ 578 C_RRLumbarDefSw_HU 0;
BA_REL_ "GenSigTimeoutTime" BU_SG_REL_ GW_APSU SG_ 578 C_RRLumbarDefSw_HU 1500;
BA_REL_ "GenSigTimeoutTime" BU_SG_REL_ GW_RRPSU SG_ 578 C_RRLumbarDefSw_HU 1500;
BA_ "Version" SG_ 578 C_RRLumbarDefSw_HU "22.07.05";
BA_ "GenSigSendType" SG_ 578 C_RRBolsterInfSw_HU 4;
BA_ "UserSigValidity" SG_ 578 C_RRBolsterInfSw_HU 0;
BA_REL_ "GenSigTimeoutTime" BU_SG_REL_ GW_APSU SG_ 578 C_RRBolsterInfSw_HU 1500;
BA_REL_ "GenSigTimeoutTime" BU_SG_REL_ GW_RRPSU SG_ 578 C_RRBolsterInfSw_HU 1500;
BA_ "Version" SG_ 578 C_RRBolsterInfSw_HU "22.07.05";
BA_ "GenSigSendType" SG_ 578 C_RRLegSupUpSw_HU 4;
BA_ "UserSigValidity" SG_ 578 C_RRLegSupUpSw_HU 0;
BA_REL_ "GenSigTimeoutTime" BU_SG_REL_ GW_APSU SG_ 578 C_RRLegSupUpSw_HU 1500;
BA_REL_ "GenSigTimeoutTime" BU_SG_REL_ GW_RRPSU SG_ 578 C_RRLegSupUpSw_HU 1500;
BA_ "Version" SG_ 578 C_RRLegSupUpSw_HU "22.07.05";
BA_ "GenSigSendType" SG_ 578 C_RROneTchNValueSet 4;
BA_ "UserSigValidity" SG_ 578 C_RROneTchNValueSet 0;
BA_REL_ "GenSigTimeoutTime" BU_SG_REL_ ATS SG_ 578 C_RROneTchNValueSet 1500;
BA_REL_ "GenSigTimeoutTime" BU_SG_REL_ GW_APSU SG_ 578 C_RROneTchNValueSet 1500;
BA_REL_ "GenSigTimeoutTime" BU_SG_REL_ GW_RRPSU SG_ 578 C_RROneTchNValueSet 1500;
BA_ "Version" SG_ 578 C_RROneTchNValueSet "22.07.05";
BA_ "GenSigSendType" SG_ 578 C_RLOneTchNValueSet 4;
BA_ "UserSigValidity" SG_ 578 C_RLOneTchNValueSet 0;
BA_REL_ "GenSigTimeoutTime" BU_SG_REL_ ATS SG_ 578 C_RLOneTchNValueSet 1500;
BA_REL_ "GenSigTimeoutTime" BU_SG_REL_ GW_APSU SG_ 578 C_RLOneTchNValueSet 1500;
BA_REL_ "GenSigTimeoutTime" BU_SG_REL_ GW_RLPSU SG_ 578 C_RLOneTchNValueSet 1500;
BA_REL_ "GenSigTimeoutTime" BU_SG_REL_ GW_RRPSU SG_ 578 C_RLOneTchNValueSet 1500;
BA_ "Version" SG_ 578 C_RLOneTchNValueSet "22.07.05";
BA_ "GenSigSendType" SG_ 578 C_RRBolsterDefSw_HU 4;
BA_ "UserSigValidity" SG_ 578 C_RRBolsterDefSw_HU 0;
BA_REL_ "GenSigTimeoutTime" BU_SG_REL_ GW_APSU SG_ 578 C_RRBolsterDefSw_HU 1500;
BA_REL_ "GenSigTimeoutTime" BU_SG_REL_ GW_RRPSU SG_ 578 C_RRBolsterDefSw_HU 1500;
BA_ "Version" SG_ 578 C_RRBolsterDefSw_HU "22.07.05";
BA_ "GenSigSendType" SG_ 578 C_AstRlxTiltUpSw_HU 4;
BA_ "UserSigValidity" SG_ 578 C_AstRlxTiltUpSw_HU 0;
BA_REL_ "GenSigTimeoutTime" BU_SG_REL_ GW_APSU SG_ 578 C_AstRlxTiltUpSw_HU 1500;
BA_ "Version" SG_ 578 C_AstRlxTiltUpSw_HU "22.07.05";
BA_ "GenSigSendType" SG_ 578 C_AstRlxTiltDnSw_HU 4;
BA_ "UserSigValidity" SG_ 578 C_AstRlxTiltDnSw_HU 0;
BA_REL_ "GenSigTimeoutTime" BU_SG_REL_ GW_APSU SG_ 578 C_AstRlxTiltDnSw_HU 1500;
BA_ "Version" SG_ 578 C_AstRlxTiltDnSw_HU "22.07.05";
BA_ "GenSigSendType" SG_ 578 C_RLRSEUpSw_HU 4;
BA_ "UserSigValidity" SG_ 578 C_RLRSEUpSw_HU 0;
BA_REL_ "GenSigTimeoutTime" BU_SG_REL_ GW_APSU SG_ 578 C_RLRSEUpSw_HU 1500;
BA_REL_ "GenSigTimeoutTime" BU_SG_REL_ GW_RLPSU SG_ 578 C_RLRSEUpSw_HU 1500;
BA_ "Version" SG_ 578 C_RLRSEUpSw_HU "22.07.05";
BA_ "GenSigSendType" SG_ 578 C_RLRSEDnSw_HU 4;
BA_ "UserSigValidity" SG_ 578 C_RLRSEDnSw_HU 0;
BA_REL_ "GenSigTimeoutTime" BU_SG_REL_ GW_APSU SG_ 578 C_RLRSEDnSw_HU 1500;
BA_REL_ "GenSigTimeoutTime" BU_SG_REL_ GW_RLPSU SG_ 578 C_RLRSEDnSw_HU 1500;
BA_ "Version" SG_ 578 C_RLRSEDnSw_HU "22.07.05";
BA_ "GenSigSendType" SG_ 578 C_RRRSEUpSw_HU 4;
BA_ "UserSigValidity" SG_ 578 C_RRRSEUpSw_HU 0;
BA_REL_ "GenSigTimeoutTime" BU_SG_REL_ GW_APSU SG_ 578 C_RRRSEUpSw_HU 1500;
BA_REL_ "GenSigTimeoutTime" BU_SG_REL_ GW_RRPSU SG_ 578 C_RRRSEUpSw_HU 1500;
BA_ "Version" SG_ 578 C_RRRSEUpSw_HU "22.07.05";
BA_ "GenSigSendType" SG_ 578 C_RRLegSupDnSw_HU 4;
BA_ "UserSigValidity" SG_ 578 C_RRLegSupDnSw_HU 0;
BA_REL_ "GenSigTimeoutTime" BU_SG_REL_ GW_APSU SG_ 578 C_RRLegSupDnSw_HU 1500;
BA_REL_ "GenSigTimeoutTime" BU_SG_REL_ GW_RRPSU SG_ 578 C_RRLegSupDnSw_HU 1500;
BA_ "Version" SG_ 578 C_RRLegSupDnSw_HU "22.07.05";
BA_ "GenSigSendType" SG_ 578 C_RRRSEDnSw_HU 4;
BA_ "UserSigValidity" SG_ 578 C_RRRSEDnSw_HU 0;
BA_REL_ "GenSigTimeoutTime" BU_SG_REL_ GW_APSU SG_ 578 C_RRRSEDnSw_HU 1500;
BA_REL_ "GenSigTimeoutTime" BU_SG_REL_ GW_RRPSU SG_ 578 C_RRRSEDnSw_HU 1500;
BA_ "Version" SG_ 578 C_RRRSEDnSw_HU "22.07.05";
BA_ "GenSigSendType" SG_ 578 C_RRHrestUpSw_HU 4;
BA_ "UserSigValidity" SG_ 578 C_RRHrestUpSw_HU 0;
BA_REL_ "GenSigTimeoutTime" BU_SG_REL_ GW_APSU SG_ 578 C_RRHrestUpSw_HU 1500;
BA_REL_ "GenSigTimeoutTime" BU_SG_REL_ GW_RRPSU SG_ 578 C_RRHrestUpSw_HU 1500;
BA_ "Version" SG_ 578 C_RRHrestUpSw_HU "22.07.05";
BA_ "GenMsgCycleTime" BO_ 675 0;
BA_ "Description" SG_ 675 Usm_RpmMUDSet "Related to Cluster Gauge";
BA_ "GenSigSendType" SG_ 675 Usm_RpmMUDSet 4;
BA_ "UserSigValidity" SG_ 675 Usm_RpmMUDSet 3;
BA_ "Version" SG_ 675 Usm_RpmMUDSet "20.02.04";
BA_ "GenSigSendType" SG_ 675 CF_AVN_HtBlcRLNValueSet 4;
BA_ "UserSigValidity" SG_ 675 CF_AVN_HtBlcRLNValueSet 3;
BA_REL_ "GenSigTimeoutTime" BU_SG_REL_ GW_RLPSU SG_ 675 CF_AVN_HtBlcRLNValueSet 0;
BA_REL_ "GenSigTimeoutTime" BU_SG_REL_ GW_RRPSU SG_ 675 CF_AVN_HtBlcRLNValueSet 0;
BA_REL_ "GenSigTimeoutTime" BU_SG_REL_ RLHV SG_ 675 CF_AVN_HtBlcRLNValueSet 0;
BA_REL_ "GenSigTimeoutTime" BU_SG_REL_ SHVU_FR SG_ 675 CF_AVN_HtBlcRLNValueSet 0;
BA_REL_ "GenSigTimeoutTime" BU_SG_REL_ SHVU_RR SG_ 675 CF_AVN_HtBlcRLNValueSet 0;
BA_ "Version" SG_ 675 CF_AVN_HtBlcRLNValueSet "20.06.03";
BA_ "Description" SG_ 675 CF_AVN_BRAKE_PedalfeelNValueSet2 "USM request for Brake Mode (New spec)";
BA_ "GenSigSendType" SG_ 675 CF_AVN_BRAKE_PedalfeelNValueSet2 4;
BA_ "UserSigValidity" SG_ 675 CF_AVN_BRAKE_PedalfeelNValueSet2 3;
BA_ "Version" SG_ 675 CF_AVN_BRAKE_PedalfeelNValueSet2 "20.04.06";
BA_ "Description" SG_ 675 CF_AVN_ISLA_AutoNModSet "USM Set Signal for Activing N Mode Setting when Vehicle enter into Winding Road";
BA_ "GenSigSendType" SG_ 675 CF_AVN_ISLA_AutoNModSet 4;
BA_ "UserSigValidity" SG_ 675 CF_AVN_ISLA_AutoNModSet 3;
BA_ "Version" SG_ 675 CF_AVN_ISLA_AutoNModSet "20.06.00";
BA_ "GenSigSendType" SG_ 675 CF_AVN_HtBlcRRNValueSet 4;
BA_ "UserSigValidity" SG_ 675 CF_AVN_HtBlcRRNValueSet 3;
BA_REL_ "GenSigTimeoutTime" BU_SG_REL_ GW_RLPSU SG_ 675 CF_AVN_HtBlcRRNValueSet 0;
BA_REL_ "GenSigTimeoutTime" BU_SG_REL_ GW_RRPSU SG_ 675 CF_AVN_HtBlcRRNValueSet 0;
BA_REL_ "GenSigTimeoutTime" BU_SG_REL_ RRHV SG_ 675 CF_AVN_HtBlcRRNValueSet 0;
BA_REL_ "GenSigTimeoutTime" BU_SG_REL_ SHVU_FR SG_ 675 CF_AVN_HtBlcRRNValueSet 0;
BA_REL_ "GenSigTimeoutTime" BU_SG_REL_ SHVU_RR SG_ 675 CF_AVN_HtBlcRRNValueSet 0;
BA_ "Version" SG_ 675 CF_AVN_HtBlcRRNValueSet "20.06.03";
BA_ "Description" SG_ 675 LapTimer_AutoMeasure_Setting "Setting value for auto-measurement of Laptimer";
BA_ "GenSigSendType" SG_ 675 LapTimer_AutoMeasure_Setting 4;
BA_ "GenSigStartValue" SG_ 675 LapTimer_AutoMeasure_Setting 3;
BA_ "UserSigValidity" SG_ 675 LapTimer_AutoMeasure_Setting 3;
BA_ "Version" SG_ 675 LapTimer_AutoMeasure_Setting "20.07.11";
BA_ "Description" SG_ 675 LapTimer_TimeGap_Setting "setting value for laptimer time gap displaying";
BA_ "GenSigSendType" SG_ 675 LapTimer_TimeGap_Setting 4;
BA_ "GenSigStartValue" SG_ 675 LapTimer_TimeGap_Setting 3;
BA_ "UserSigValidity" SG_ 675 LapTimer_TimeGap_Setting 3;
BA_ "Version" SG_ 675 LapTimer_TimeGap_Setting "20.07.11";
BA_ "Description" SG_ 675 Usm_RpmSANDSet "Related to Cluster Gauge";
BA_ "GenSigSendType" SG_ 675 Usm_RpmSANDSet 4;
BA_ "UserSigValidity" SG_ 675 Usm_RpmSANDSet 3;
BA_ "Version" SG_ 675 Usm_RpmSANDSet "20.02.04";
BA_ "Description" SG_ 675 CF_AVN_RemoteWDWNValueSet "Remote Window On/Off Set signal of USM for Fob Key";
BA_ "GenSigSendType" SG_ 675 CF_AVN_RemoteWDWNValueSet 4;
BA_ "UserSigValidity" SG_ 675 CF_AVN_RemoteWDWNValueSet 3;
BA_ "Version" SG_ 675 CF_AVN_RemoteWDWNValueSet "20.07.14";
BA_ "Description" SG_ 675 USM_TowWeight_Set "Trailer Mode Setting USM: Tow Weight set for User

-User can select the tow weight value for get the exact DTE value";
BA_ "GenSigSendType" SG_ 675 USM_TowWeight_Set 4;
BA_ "UserSigValidity" SG_ 675 USM_TowWeight_Set 7;
BA_ "Version" SG_ 675 USM_TowWeight_Set "20.10.02";
BA_ "Description" SG_ 675 CF_AVN_SportHUD2 "Related to HUD Sports mode of custom mode2";
BA_ "GenSigSendType" SG_ 675 CF_AVN_SportHUD2 4;
BA_ "UserSigValidity" SG_ 675 CF_AVN_SportHUD2 3;
BA_ "Version" SG_ 675 CF_AVN_SportHUD2 "20.09.00";
BA_ "Description" SG_ 675 C_SLB_SmartCtrl_Set_Nvalue "USM time setting for Smart Posture Care 2.0  Off or 30min or 60min";
BA_ "GenSigSendType" SG_ 675 C_SLB_SmartCtrl_Set_Nvalue 4;
BA_ "UserSigValidity" SG_ 675 C_SLB_SmartCtrl_Set_Nvalue 3;
BA_REL_ "GenSigTimeoutTime" BU_SG_REL_ GW_DLBCU SG_ 675 C_SLB_SmartCtrl_Set_Nvalue 0;
BA_REL_ "GenSigTimeoutTime" BU_SG_REL_ SLB SG_ 675 C_SLB_SmartCtrl_Set_Nvalue 0;
BA_ "Version" SG_ 675 C_SLB_SmartCtrl_Set_Nvalue "20.09.01";
BA_ "Description" SG_ 675 HU_CustomNewMenuSet "Custom Mode User Setting Signal";
BA_ "GenSigSendType" SG_ 675 HU_CustomNewMenuSet 4;
BA_ "UserSigValidity" SG_ 675 HU_CustomNewMenuSet 3;
BA_ "Version" SG_ 675 HU_CustomNewMenuSet "20.09.00";
BA_ "Description" SG_ 675 USM_RpmComfortRearSet "RPM Display Setting When Comfort(Rear) mode Set";
BA_ "GenSigSendType" SG_ 675 USM_RpmComfortRearSet 4;
BA_ "UserSigValidity" SG_ 675 USM_RpmComfortRearSet 3;
BA_ "Version" SG_ 675 USM_RpmComfortRearSet "20.10.02";
BA_ "Description" SG_ 675 Usm_RpmMyDriveModeSet "Cluster MY Drive Mode RPM Set Signal";
BA_ "GenSigSendType" SG_ 675 Usm_RpmMyDriveModeSet 4;
BA_ "UserSigValidity" SG_ 675 Usm_RpmMyDriveModeSet 3;
BA_ "Version" SG_ 675 Usm_RpmMyDriveModeSet "20.11.00";
BA_ "Description" SG_ 675 LapTimer_MeasuringStatus_HU "Lap Timer measuring status shared with Cluster.";
BA_ "GenSigSendType" SG_ 675 LapTimer_MeasuringStatus_HU 4;
BA_ "UserSigValidity" SG_ 675 LapTimer_MeasuringStatus_HU 3;
BA_ "Version" SG_ 675 LapTimer_MeasuringStatus_HU "22.12.04";
BA_ "Description" SG_ 675 CF_AVN_PCA_RrEquipNvalueSet "Headunit Setting signal for Rear Safety of USM";
BA_ "GenSigSendType" SG_ 675 CF_AVN_PCA_RrEquipNvalueSet 4;
BA_ "UserSigValidity" SG_ 675 CF_AVN_PCA_RrEquipNvalueSet 3;
BA_ "Version" SG_ 675 CF_AVN_PCA_RrEquipNvalueSet "20.06.04";
BA_ "GenMsgSendType" BO_ 579 0;
BA_ "Description" SG_ 579 OHCL_Opt "This signal is OHCL(OverHead Console Lamp)  ECU Option state";
BA_ "GenSigSendType" SG_ 579 OHCL_Opt 4;
BA_ "TimeoutValue" SG_ 579 OHCL_Opt "Old Value";
BA_ "UserSigValidity" SG_ 579 OHCL_Opt 3;
BA_REL_ "GenSigTimeoutTime" BU_SG_REL_ ATS SG_ 579 OHCL_Opt 1000;
BA_ "Version" SG_ 579 OHCL_Opt "19.12.01";
BA_ "Description" SG_ 579 OHCL_Sys_sta "This signal is OHCL (OverHead Console Lamp) system state";
BA_ "GenSigSendType" SG_ 579 OHCL_Sys_sta 4;
BA_ "TimeoutValue" SG_ 579 OHCL_Sys_sta "0x3";
BA_ "UserSigValidity" SG_ 579 OHCL_Sys_sta 3;
BA_REL_ "GenSigTimeoutTime" BU_SG_REL_ ATS SG_ 579 OHCL_Sys_sta 1000;
BA_ "Version" SG_ 579 OHCL_Sys_sta "19.12.01";
BA_ "Description" SG_ 579 OHCL_DoorOn_Sta "This signal is door lamp switch On/Off status";
BA_ "GenSigSendType" SG_ 579 OHCL_DoorOn_Sta 4;
BA_ "TimeoutValue" SG_ 579 OHCL_DoorOn_Sta "Old Value";
BA_ "UserSigValidity" SG_ 579 OHCL_DoorOn_Sta 3;
BA_REL_ "GenSigTimeoutTime" BU_SG_REL_ ATS SG_ 579 OHCL_DoorOn_Sta 1000;
BA_ "Version" SG_ 579 OHCL_DoorOn_Sta "19.12.01";
BA_ "Description" SG_ 579 OHCL_RrMapLftOn_Sta "This signal is rear left map lamp On/Off status";
BA_ "GenSigSendType" SG_ 579 OHCL_RrMapLftOn_Sta 4;
BA_ "TimeoutValue" SG_ 579 OHCL_RrMapLftOn_Sta "Old Value";
BA_ "UserSigValidity" SG_ 579 OHCL_RrMapLftOn_Sta 3;
BA_REL_ "GenSigTimeoutTime" BU_SG_REL_ ATS SG_ 579 OHCL_RrMapLftOn_Sta 1000;
BA_ "Version" SG_ 579 OHCL_RrMapLftOn_Sta "19.12.01";
BA_ "Description" SG_ 579 OHCL_RrMapRtOn_Sta "This signal is rear right map lamp On/Off status";
BA_ "GenSigSendType" SG_ 579 OHCL_RrMapRtOn_Sta 4;
BA_ "TimeoutValue" SG_ 579 OHCL_RrMapRtOn_Sta "Old Value";
BA_ "UserSigValidity" SG_ 579 OHCL_RrMapRtOn_Sta 3;
BA_REL_ "GenSigTimeoutTime" BU_SG_REL_ ATS SG_ 579 OHCL_RrMapRtOn_Sta 1000;
BA_ "Version" SG_ 579 OHCL_RrMapRtOn_Sta "19.12.01";
BA_ "Description" SG_ 579 OHCL_RrRoomOn_Sta "This signal is rear room map lamp On/Off status ( all )";
BA_ "GenSigSendType" SG_ 579 OHCL_RrRoomOn_Sta 4;
BA_ "TimeoutValue" SG_ 579 OHCL_RrRoomOn_Sta "Old Value";
BA_ "UserSigValidity" SG_ 579 OHCL_RrRoomOn_Sta 3;
BA_REL_ "GenSigTimeoutTime" BU_SG_REL_ ATS SG_ 579 OHCL_RrRoomOn_Sta 1000;
BA_ "Version" SG_ 579 OHCL_RrRoomOn_Sta "19.12.01";
BA_ "Description" SG_ 579 OHCL_RrMoodOn_Sta "This signal is rear mood map lamp On/Off status";
BA_ "GenSigSendType" SG_ 579 OHCL_RrMoodOn_Sta 4;
BA_ "TimeoutValue" SG_ 579 OHCL_RrMoodOn_Sta "Old Value";
BA_ "UserSigValidity" SG_ 579 OHCL_RrMoodOn_Sta 3;
BA_REL_ "GenSigTimeoutTime" BU_SG_REL_ ATS SG_ 579 OHCL_RrMoodOn_Sta 1000;
BA_ "Version" SG_ 579 OHCL_RrMoodOn_Sta "19.12.01";
BA_ "Description" SG_ 579 OHCL_LEDClr_Sta "This signal is interior lamps lighting color status";
BA_ "GenSigSendType" SG_ 579 OHCL_LEDClr_Sta 4;
BA_ "TimeoutValue" SG_ 579 OHCL_LEDClr_Sta "Old Value";
BA_ "UserSigValidity" SG_ 579 OHCL_LEDClr_Sta 3;
BA_REL_ "GenSigTimeoutTime" BU_SG_REL_ ATS SG_ 579 OHCL_LEDClr_Sta 1000;
BA_ "Version" SG_ 579 OHCL_LEDClr_Sta "19.12.01";
BA_ "Description" SG_ 579 OHCL_LEDBgtns_Sta "This signal is interior lamps brightness status";
BA_ "GenSigSendType" SG_ 579 OHCL_LEDBgtns_Sta 4;
BA_ "TimeoutValue" SG_ 579 OHCL_LEDBgtns_Sta "Old Value";
BA_ "UserSigValidity" SG_ 579 OHCL_LEDBgtns_Sta 3;
BA_REL_ "GenSigTimeoutTime" BU_SG_REL_ ATS SG_ 579 OHCL_LEDBgtns_Sta 1000;
BA_ "Version" SG_ 579 OHCL_LEDBgtns_Sta "19.12.01";
BA_ "Description" SG_ 579 OHCL_TllTlLmpSta "This signal is PAB tell tale lamp status signal

( ACU_TllTlLmpDis feedback signal )";
BA_ "GenSigSendType" SG_ 579 OHCL_TllTlLmpSta 4;
BA_ "GenSigStartValue" SG_ 579 OHCL_TllTlLmpSta 3;
BA_ "UserSigValidity" SG_ 579 OHCL_TllTlLmpSta 3;
BA_REL_ "GenSigTimeoutTime" BU_SG_REL_ CGW_CCU SG_ 579 OHCL_TllTlLmpSta 1000;
BA_ "Version" SG_ 579 OHCL_TllTlLmpSta "20.10.00";
BA_ "Description" SG_ 579 OHCL_FrMapLftOn_Sta "This signal is front left map lamp On/Off status";
BA_ "GenSigSendType" SG_ 579 OHCL_FrMapLftOn_Sta 4;
BA_ "TimeoutValue" SG_ 579 OHCL_FrMapLftOn_Sta "0x0";
BA_ "UserSigValidity" SG_ 579 OHCL_FrMapLftOn_Sta 3;
BA_REL_ "GenSigTimeoutTime" BU_SG_REL_ ATS SG_ 579 OHCL_FrMapLftOn_Sta 1000;
BA_ "Version" SG_ 579 OHCL_FrMapLftOn_Sta "19.12.01";
BA_ "Description" SG_ 579 OHCL_RrCurtainReq "This signal is Rear curtain switch On/Off signal

( The signal send 'On' during push switch only )";
BA_ "GenSigSendType" SG_ 579 OHCL_RrCurtainReq 4;
BA_ "UserSigValidity" SG_ 579 OHCL_RrCurtainReq 3;
BA_ "Version" SG_ 579 OHCL_RrCurtainReq "20.01.01";
BA_ "Description" SG_ 579 OHCL_FrMapRtOn_Sta "This signal is front right map lamp On/Off status";
BA_ "GenSigSendType" SG_ 579 OHCL_FrMapRtOn_Sta 4;
BA_ "TimeoutValue" SG_ 579 OHCL_FrMapRtOn_Sta "Old Value";
BA_ "UserSigValidity" SG_ 579 OHCL_FrMapRtOn_Sta 3;
BA_REL_ "GenSigTimeoutTime" BU_SG_REL_ ATS SG_ 579 OHCL_FrMapRtOn_Sta 1000;
BA_ "Version" SG_ 579 OHCL_FrMapRtOn_Sta "19.12.01";
BA_ "Description" SG_ 579 OHCL_FrRoomOn_Sta "This signal is front room lamp On/Off status ( all )";
BA_ "GenSigSendType" SG_ 579 OHCL_FrRoomOn_Sta 4;
BA_ "TimeoutValue" SG_ 579 OHCL_FrRoomOn_Sta "Old Value";
BA_ "UserSigValidity" SG_ 579 OHCL_FrRoomOn_Sta 3;
BA_REL_ "GenSigTimeoutTime" BU_SG_REL_ ATS SG_ 579 OHCL_FrRoomOn_Sta 1000;
BA_ "Version" SG_ 579 OHCL_FrRoomOn_Sta "19.12.01";
BA_ "Description" SG_ 579 OHCL_FrMoodOn_Sta "This signal is front mood map lamp On/Off status";
BA_ "GenSigSendType" SG_ 579 OHCL_FrMoodOn_Sta 4;
BA_ "UserSigValidity" SG_ 579 OHCL_FrMoodOn_Sta 3;
BA_REL_ "GenSigTimeoutTime" BU_SG_REL_ ATS SG_ 579 OHCL_FrMoodOn_Sta 1000;
BA_ "Version" SG_ 579 OHCL_FrMoodOn_Sta "19.12.01";
BA_ "GenMsgSendType" BO_ 632 0;
BA_ "Description" SG_ 632 PSS_RR_AstHRestFwdMvBtn "PSS_RR_AstStHead Rest UpMoveButton";
BA_ "GenSigSendType" SG_ 632 PSS_RR_AstHRestFwdMvBtn 4;
BA_ "UserSigValidity" SG_ 632 PSS_RR_AstHRestFwdMvBtn 0;
BA_REL_ "GenSigTimeoutTime" BU_SG_REL_ CGW_CCU SG_ 632 PSS_RR_AstHRestFwdMvBtn 1500;
BA_ "NetworkRequest" SG_ 632 PSS_RR_AstHRestFwdMvBtn 0;
BA_ "NetworkRequestHoldingTime" SG_ 632 PSS_RR_AstHRestFwdMvBtn 5000;
BA_ "Version" SG_ 632 PSS_RR_AstHRestFwdMvBtn "22.10.20";
BA_ "Description" SG_ 632 PSS_RR_AstRclBwdMvBtn "PSS_RR_AstStReclinerBackwardMoveButton";
BA_ "GenSigSendType" SG_ 632 PSS_RR_AstRclBwdMvBtn 4;
BA_ "UserSigValidity" SG_ 632 PSS_RR_AstRclBwdMvBtn 0;
BA_REL_ "GenSigTimeoutTime" BU_SG_REL_ CGW_CCU SG_ 632 PSS_RR_AstRclBwdMvBtn 1500;
BA_ "NetworkRequest" SG_ 632 PSS_RR_AstRclBwdMvBtn 0;
BA_ "NetworkRequestHoldingTime" SG_ 632 PSS_RR_AstRclBwdMvBtn 5000;
BA_ "Version" SG_ 632 PSS_RR_AstRclBwdMvBtn "22.10.20";
BA_ "Description" SG_ 632 PSS_RR_AstSldFwdMvBtn "PSS_RR_AstStSlideForwardMoveButton";
BA_ "GenSigSendType" SG_ 632 PSS_RR_AstSldFwdMvBtn 4;
BA_ "UserSigValidity" SG_ 632 PSS_RR_AstSldFwdMvBtn 0;
BA_REL_ "GenSigTimeoutTime" BU_SG_REL_ CGW_CCU SG_ 632 PSS_RR_AstSldFwdMvBtn 1500;
BA_ "NetworkRequest" SG_ 632 PSS_RR_AstSldFwdMvBtn 0;
BA_ "NetworkRequestHoldingTime" SG_ 632 PSS_RR_AstSldFwdMvBtn 5000;
BA_ "Version" SG_ 632 PSS_RR_AstSldFwdMvBtn "22.10.20";
BA_ "Description" SG_ 632 PSS_RR_AstSldBwdMvBtn "PSS_RR_AstStSlideBackwardMoveButton";
BA_ "GenSigSendType" SG_ 632 PSS_RR_AstSldBwdMvBtn 4;
BA_ "UserSigValidity" SG_ 632 PSS_RR_AstSldBwdMvBtn 0;
BA_REL_ "GenSigTimeoutTime" BU_SG_REL_ CGW_CCU SG_ 632 PSS_RR_AstSldBwdMvBtn 1500;
BA_ "NetworkRequest" SG_ 632 PSS_RR_AstSldBwdMvBtn 0;
BA_ "NetworkRequestHoldingTime" SG_ 632 PSS_RR_AstSldBwdMvBtn 5000;
BA_ "Version" SG_ 632 PSS_RR_AstSldBwdMvBtn "22.10.20";
BA_ "Description" SG_ 632 PSS_RR_AstHgtUpMvBtn "PSS_RR_AstStHeightUpMoveButton";
BA_ "GenSigSendType" SG_ 632 PSS_RR_AstHgtUpMvBtn 4;
BA_ "UserSigValidity" SG_ 632 PSS_RR_AstHgtUpMvBtn 0;
BA_REL_ "GenSigTimeoutTime" BU_SG_REL_ CGW_CCU SG_ 632 PSS_RR_AstHgtUpMvBtn 1500;
BA_ "NetworkRequest" SG_ 632 PSS_RR_AstHgtUpMvBtn 0;
BA_ "NetworkRequestHoldingTime" SG_ 632 PSS_RR_AstHgtUpMvBtn 5000;
BA_ "Version" SG_ 632 PSS_RR_AstHgtUpMvBtn "22.10.20";
BA_ "Description" SG_ 632 PSS_RR_AstHgtDnMvBtn "PSS_RR_AstStHeightDownMoveButton";
BA_ "GenSigSendType" SG_ 632 PSS_RR_AstHgtDnMvBtn 4;
BA_ "UserSigValidity" SG_ 632 PSS_RR_AstHgtDnMvBtn 0;
BA_REL_ "GenSigTimeoutTime" BU_SG_REL_ CGW_CCU SG_ 632 PSS_RR_AstHgtDnMvBtn 1500;
BA_ "NetworkRequest" SG_ 632 PSS_RR_AstHgtDnMvBtn 0;
BA_ "NetworkRequestHoldingTime" SG_ 632 PSS_RR_AstHgtDnMvBtn 5000;
BA_ "Version" SG_ 632 PSS_RR_AstHgtDnMvBtn "22.10.20";
BA_ "Description" SG_ 632 PSS_RR_AstHRestBwdMvBtn "PSS_RR_AstStHead Rest DownMoveButton";
BA_ "GenSigSendType" SG_ 632 PSS_RR_AstHRestBwdMvBtn 4;
BA_ "UserSigValidity" SG_ 632 PSS_RR_AstHRestBwdMvBtn 0;
BA_REL_ "GenSigTimeoutTime" BU_SG_REL_ CGW_CCU SG_ 632 PSS_RR_AstHRestBwdMvBtn 1500;
BA_ "NetworkRequest" SG_ 632 PSS_RR_AstHRestBwdMvBtn 0;
BA_ "NetworkRequestHoldingTime" SG_ 632 PSS_RR_AstHRestBwdMvBtn 5000;
BA_ "Version" SG_ 632 PSS_RR_AstHRestBwdMvBtn "22.10.20";
BA_ "Description" SG_ 632 PSS_RR_AstFRestOpenMvBtn "PSS_RR_AstStFootrestOpenButton";
BA_ "GenSigSendType" SG_ 632 PSS_RR_AstFRestOpenMvBtn 4;
BA_ "UserSigValidity" SG_ 632 PSS_RR_AstFRestOpenMvBtn 0;
BA_REL_ "GenSigTimeoutTime" BU_SG_REL_ CGW_CCU SG_ 632 PSS_RR_AstFRestOpenMvBtn 1500;
BA_ "NetworkRequest" SG_ 632 PSS_RR_AstFRestOpenMvBtn 0;
BA_ "NetworkRequestHoldingTime" SG_ 632 PSS_RR_AstFRestOpenMvBtn 5000;
BA_ "Version" SG_ 632 PSS_RR_AstFRestOpenMvBtn "22.10.20";
BA_ "Description" SG_ 632 PSS_RR_AstFRestCloseMvBtn "PSS_RR_AstStFootrestCloseButton";
BA_ "GenSigSendType" SG_ 632 PSS_RR_AstFRestCloseMvBtn 4;
BA_ "UserSigValidity" SG_ 632 PSS_RR_AstFRestCloseMvBtn 0;
BA_REL_ "GenSigTimeoutTime" BU_SG_REL_ CGW_CCU SG_ 632 PSS_RR_AstFRestCloseMvBtn 1500;
BA_ "NetworkRequest" SG_ 632 PSS_RR_AstFRestCloseMvBtn 0;
BA_ "NetworkRequestHoldingTime" SG_ 632 PSS_RR_AstFRestCloseMvBtn 5000;
BA_ "Version" SG_ 632 PSS_RR_AstFRestCloseMvBtn "22.10.20";
BA_ "Description" SG_ 632 PSS_RR_AstHRestUpMvBtn "PSS_RR_AstStHead Rest ForwardMoveButton";
BA_ "GenSigSendType" SG_ 632 PSS_RR_AstHRestUpMvBtn 4;
BA_ "UserSigValidity" SG_ 632 PSS_RR_AstHRestUpMvBtn 0;
BA_REL_ "GenSigTimeoutTime" BU_SG_REL_ CGW_CCU SG_ 632 PSS_RR_AstHRestUpMvBtn 1500;
BA_ "NetworkRequest" SG_ 632 PSS_RR_AstHRestUpMvBtn 0;
BA_ "NetworkRequestHoldingTime" SG_ 632 PSS_RR_AstHRestUpMvBtn 5000;
BA_ "Version" SG_ 632 PSS_RR_AstHRestUpMvBtn "22.10.20";
BA_ "Description" SG_ 632 PSS_RR_AstHRestDnMvBtn "PSS_RR_AstStHead Rest BackwardMoveButton";
BA_ "GenSigSendType" SG_ 632 PSS_RR_AstHRestDnMvBtn 4;
BA_ "UserSigValidity" SG_ 632 PSS_RR_AstHRestDnMvBtn 0;
BA_REL_ "GenSigTimeoutTime" BU_SG_REL_ CGW_CCU SG_ 632 PSS_RR_AstHRestDnMvBtn 1500;
BA_ "NetworkRequest" SG_ 632 PSS_RR_AstHRestDnMvBtn 0;
BA_ "NetworkRequestHoldingTime" SG_ 632 PSS_RR_AstHRestDnMvBtn 5000;
BA_ "Version" SG_ 632 PSS_RR_AstHRestDnMvBtn "22.10.20";
BA_ "Description" SG_ 632 PSS_RR_AstRclFwdMvBtn "PSS_RR_AstStReclinerForwardMoveButton";
BA_ "GenSigSendType" SG_ 632 PSS_RR_AstRclFwdMvBtn 4;
BA_ "UserSigValidity" SG_ 632 PSS_RR_AstRclFwdMvBtn 0;
BA_REL_ "GenSigTimeoutTime" BU_SG_REL_ CGW_CCU SG_ 632 PSS_RR_AstRclFwdMvBtn 1500;
BA_ "NetworkRequest" SG_ 632 PSS_RR_AstRclFwdMvBtn 0;
BA_ "NetworkRequestHoldingTime" SG_ 632 PSS_RR_AstRclFwdMvBtn 5000;
BA_ "Version" SG_ 632 PSS_RR_AstRclFwdMvBtn "22.10.20";
BA_ "GenMsgCycleTime" BO_ 681 0;
BA_ "Description" SG_ 681 AVN_SeatPosMemory_Cmd "The signal indicates the command of rear left seat position memory to AVN.";
BA_ "GenSigSendType" SG_ 681 AVN_SeatPosMemory_Cmd 4;
BA_ "UserSigValidity" SG_ 681 AVN_SeatPosMemory_Cmd 0;
BA_REL_ "GenSigTimeoutTime" BU_SG_REL_ CGW_CCU SG_ 681 AVN_SeatPosMemory_Cmd 0;
BA_REL_ "GenSigTimeoutTime" BU_SG_REL_ GW_APSU SG_ 681 AVN_SeatPosMemory_Cmd 0;
BA_REL_ "GenSigTimeoutTime" BU_SG_REL_ GW_DPSU SG_ 681 AVN_SeatPosMemory_Cmd 0;
BA_REL_ "GenSigTimeoutTime" BU_SG_REL_ GW_RRPSU SG_ 681 AVN_SeatPosMemory_Cmd 0;
BA_ "Version" SG_ 681 AVN_SeatPosMemory_Cmd "20.03.07";
BA_ "GenSigSendType" SG_ 681 RLPSM_RearModeWngDis 4;
BA_ "UserSigValidity" SG_ 681 RLPSM_RearModeWngDis 1;
BA_REL_ "GenSigTimeoutTime" BU_SG_REL_ CGW_CCU SG_ 681 RLPSM_RearModeWngDis 0;
BA_ "NetworkRequest" SG_ 681 RLPSM_RearModeWngDis 0;
BA_ "NetworkRequestHoldingTime" SG_ 681 RLPSM_RearModeWngDis 5000;
BA_ "Version" SG_ 681 RLPSM_RearModeWngDis "21.04.00";
BA_ "Description" SG_ 681 RLIMS_AMPBzrReq "SEAT IMS Buzzer Request for AMP";
BA_ "GenSigSendType" SG_ 681 RLIMS_AMPBzrReq 4;
BA_ "UserSigValidity" SG_ 681 RLIMS_AMPBzrReq 0;
BA_REL_ "GenSigTimeoutTime" BU_SG_REL_ CGW_CCU SG_ 681 RLIMS_AMPBzrReq 0;
BA_ "NetworkRequest" SG_ 681 RLIMS_AMPBzrReq 0;
BA_ "NetworkRequestHoldingTime" SG_ 681 RLIMS_AMPBzrReq 5000;
BA_ "Version" SG_ 681 RLIMS_AMPBzrReq "22.05.02";
BA_ "Description" SG_ 681 RLPSM_Warn_CnslLmt "The signal indicates the command of console limt warning to AVN.";
BA_ "GenSigSendType" SG_ 681 RLPSM_Warn_CnslLmt 4;
BA_ "UserSigValidity" SG_ 681 RLPSM_Warn_CnslLmt 0;
BA_REL_ "GenSigTimeoutTime" BU_SG_REL_ CGW_CCU SG_ 681 RLPSM_Warn_CnslLmt 0;
BA_ "Version" SG_ 681 RLPSM_Warn_CnslLmt "19.11.03";
BA_ "Description" SG_ 681 AVN_SeatPosPlyBck_Cmd "The signal indicates the command of rear left seat positon play to AVN.";
BA_ "GenSigSendType" SG_ 681 AVN_SeatPosPlyBck_Cmd 4;
BA_ "UserSigValidity" SG_ 681 AVN_SeatPosPlyBck_Cmd 0;
BA_REL_ "GenSigTimeoutTime" BU_SG_REL_ GW_APSU SG_ 681 AVN_SeatPosPlyBck_Cmd 0;
BA_REL_ "GenSigTimeoutTime" BU_SG_REL_ GW_DPSU SG_ 681 AVN_SeatPosPlyBck_Cmd 0;
BA_REL_ "GenSigTimeoutTime" BU_SG_REL_ GW_RRPSU SG_ 681 AVN_SeatPosPlyBck_Cmd 0;
BA_ "Version" SG_ 681 AVN_SeatPosPlyBck_Cmd "20.03.07";
BA_ "GenMsgCycleTime" BO_ 599 0;
BA_ "Description" SG_ 599 RRIMS_AMPBzrReq "SEAT IMS Buzzer Request for AMP";
BA_ "GenSigSendType" SG_ 599 RRIMS_AMPBzrReq 4;
BA_ "UserSigValidity" SG_ 599 RRIMS_AMPBzrReq 0;
BA_REL_ "GenSigTimeoutTime" BU_SG_REL_ CGW_CCU SG_ 599 RRIMS_AMPBzrReq 0;
BA_ "NetworkRequest" SG_ 599 RRIMS_AMPBzrReq 0;
BA_ "NetworkRequestHoldingTime" SG_ 599 RRIMS_AMPBzrReq 5000;
BA_ "Version" SG_ 599 RRIMS_AMPBzrReq "22.05.02";
BA_ "GenSigSendType" SG_ 599 RRPSM_RearModeWngDis 4;
BA_ "UserSigValidity" SG_ 599 RRPSM_RearModeWngDis 1;
BA_REL_ "GenSigTimeoutTime" BU_SG_REL_ CGW_CCU SG_ 599 RRPSM_RearModeWngDis 0;
BA_ "NetworkRequest" SG_ 599 RRPSM_RearModeWngDis 0;
BA_ "NetworkRequestHoldingTime" SG_ 599 RRPSM_RearModeWngDis 5000;
BA_ "Version" SG_ 599 RRPSM_RearModeWngDis "21.08.01";
BA_ "GenMsgSendType" BO_ 2160080129 0;
BA_ "GenMsgCycleTime" BO_ 2160080129 50;
BA_ "GenMsgCycleTimeFast" BO_ 2160080129 0;
BA_ "GenMsgNrOfRepetition" BO_ 2160080129 0;
BA_ "VFrameFormat" BO_ 2160080129 1;
BA_ "Description" SG_ 2160080129 VCU_Crc1Val "The data area for CRC calculation is based on the data length (DLC) of the message DB.

The CRC shall be calculated over the entire data block (excluding the CRC bytes) including the user data, alive counter and Data ID



- CRC Polynomial (0x1021) , Initial Value : 0xFFFF, XOR value : 0x0000, Data ID : Message ID + 0xF800 

- The initial value is for CRC calculation and the message should be sent with the calculated result value. 

- The mathematical expression to 16 bit CRC polynomial is given here. G(x) = x16 + x12 + x5 + 1



<For CRC calculation of CAN-FD Msg for HS CAN domain ECUs>



- HS-CAN Messages that routed from CAN-FD domain are using 29 bit Extended CAN ID and splitted into 8 Byte Messages.

(from 1 to 4 Msgs, depending on source CAN-FD Msg¡¯s DLC)

- For splitted CAN-FD Msgs¡¯ CRC calculation, HS CAN ECUs should use source CAN-FD Msg¡¯s original STD ID. 

- The original STD ID can be read from Ext ID¡¯s 4~6th Byte.

Eg. STD 0x6AA : EXT SPLT 0x1A8[6AA]01 / 0x1A8[6AA]02 / 0x1A8[6AA]03 / 0x1A8[6AA]04 

(2~4th splitited Msgs can be omitted depending on source CAN-FD Msg¡¯s DLC)

- Aslo, HS-CAN ECUs should use merged data block (from whole splitted Msg) for CRC calculation.";
BA_ "GenSigStartValue" SG_ 2160080129 VCU_Crc1Val 65535;
BA_ "UserSigValidity" SG_ 2160080129 VCU_Crc1Val 7;
BA_ "RoutingFactor" SG_ 2160080129 VCU_Crc1Val 5;
BA_ "Version" SG_ 2160080129 VCU_Crc1Val "21.09.03";
BA_ "Description" SG_ 2160080129 VCU_AlvCnt1Val "For the first transmission request for a data element the counter shall be initialized with 0 and shall be incremented by 1 for every subsequent send request. 

When the counter reaches the maximum value(0xFF), then it shall restart with 0 for the next send request";
BA_ "UserSigValidity" SG_ 2160080129 VCU_AlvCnt1Val 7;
BA_ "RoutingFactor" SG_ 2160080129 VCU_AlvCnt1Val 5;
BA_ "Version" SG_ 2160080129 VCU_AlvCnt1Val "21.09.03";
BA_ "Description" SG_ 2160080129 VCU_RdySta "VCU Ready";
BA_ "UserSigValidity" SG_ 2160080129 VCU_RdySta 7;
BA_ "RoutingFactor" SG_ 2160080129 VCU_RdySta 5;
BA_ "Version" SG_ 2160080129 VCU_RdySta "20.04.05";
BA_ "Description" SG_ 2160080129 VCU_StartKeyHoldSta "Start Key Hold Signal";
BA_ "UserSigValidity" SG_ 2160080129 VCU_StartKeyHoldSta 7;
BA_ "RoutingFactor" SG_ 2160080129 VCU_StartKeyHoldSta 5;
BA_ "Version" SG_ 2160080129 VCU_StartKeyHoldSta "20.04.05";
BA_ "Description" SG_ 2160080129 VCU_EvDrvRdySta "EV Ready";
BA_ "UserSigValidity" SG_ 2160080129 VCU_EvDrvRdySta 7;
BA_ "RoutingFactor" SG_ 2160080129 VCU_EvDrvRdySta 5;
BA_ "Version" SG_ 2160080129 VCU_EvDrvRdySta "20.04.05";
BA_ "Description" SG_ 2160080129 VCU_MotPwrEnReq "Motor Power Enable";
BA_ "UserSigValidity" SG_ 2160080129 VCU_MotPwrEnReq 7;
BA_ "RoutingFactor" SG_ 2160080129 VCU_MotPwrEnReq 5;
BA_ "Version" SG_ 2160080129 VCU_MotPwrEnReq "20.04.05";
BA_ "Description" SG_ 2160080129 VCU_GearPosSta "Gear Position Status";
BA_ "GenSigStartValue" SG_ 2160080129 VCU_GearPosSta 9;
BA_ "UserSigValidity" SG_ 2160080129 VCU_GearPosSta 7;
BA_ "RoutingFactor" SG_ 2160080129 VCU_GearPosSta 5;
BA_ "Version" SG_ 2160080129 VCU_GearPosSta "21.05.01";
BA_ "Description" SG_ 2160080129 VCU_LdcInhReq "LDC Output Inhibit Request";
BA_ "GenSigStartValue" SG_ 2160080129 VCU_LdcInhReq 1;
BA_ "UserSigValidity" SG_ 2160080129 VCU_LdcInhReq 7;
BA_ "RoutingFactor" SG_ 2160080129 VCU_LdcInhReq 5;
BA_ "Version" SG_ 2160080129 VCU_LdcInhReq "20.04.05";
BA_ "Description" SG_ 2160080129 VCU_MainRlyOffReq "Main Relay Cut off Request";
BA_ "UserSigValidity" SG_ 2160080129 VCU_MainRlyOffReq 7;
BA_ "RoutingFactor" SG_ 2160080129 VCU_MainRlyOffReq 5;
BA_ "Version" SG_ 2160080129 VCU_MainRlyOffReq "20.04.05";
BA_ "Description" SG_ 2160080129 VCU_AccPedDepVal "Accelerator Pedal Depth Value";
BA_ "UserSigValidity" SG_ 2160080129 VCU_AccPedDepVal 7;
BA_ "RoutingFactor" SG_ 2160080129 VCU_AccPedDepVal 5;
BA_ "Version" SG_ 2160080129 VCU_AccPedDepVal "20.04.05";
BA_ "Description" SG_ 2160080129 VCU_FatcOperPermSta "Climate Operating Permission";
BA_ "UserSigValidity" SG_ 2160080129 VCU_FatcOperPermSta 7;
BA_ "RoutingFactor" SG_ 2160080129 VCU_FatcOperPermSta 5;
BA_ "Version" SG_ 2160080129 VCU_FatcOperPermSta "20.04.05";
BA_ "Description" SG_ 2160080129 VCU_DrvCycSta "Driving Cycle Status";
BA_ "UserSigValidity" SG_ 2160080129 VCU_DrvCycSta 7;
BA_ "RoutingFactor" SG_ 2160080129 VCU_DrvCycSta 5;
BA_ "Version" SG_ 2160080129 VCU_DrvCycSta "20.04.05";
BA_ "Description" SG_ 2160080129 VCU_CltActOpSta "Clutch Actuator Operating Status";
BA_ "UserSigValidity" SG_ 2160080129 VCU_CltActOpSta 7;
BA_ "RoutingFactor" SG_ 2160080129 VCU_CltActOpSta 5;
BA_ "Version" SG_ 2160080129 VCU_CltActOpSta "20.04.05";
BA_ "Description" SG_ 2160080129 VCU_WhlSpdSnsrAlvReq "Alive Request for Wheel Speed Sensors";
BA_ "UserSigValidity" SG_ 2160080129 VCU_WhlSpdSnsrAlvReq 7;
BA_ "RoutingFactor" SG_ 2160080129 VCU_WhlSpdSnsrAlvReq 5;
BA_ "Version" SG_ 2160080129 VCU_WhlSpdSnsrAlvReq "20.04.05";
BA_ "Description" SG_ 2160080129 VCU_DrvModOpSta "VCU's operating drive mode according to CLU and DMIC signals";
BA_ "UserSigValidity" SG_ 2160080129 VCU_DrvModOpSta 7;
BA_ "RoutingFactor" SG_ 2160080129 VCU_DrvModOpSta 5;
BA_ "Version" SG_ 2160080129 VCU_DrvModOpSta "20.08.07";
BA_ "Description" SG_ 2160080129 VCU_HydBrkFcHoldRq "Hydraulic brake force holding request from VCU";
BA_ "UserSigValidity" SG_ 2160080129 VCU_HydBrkFcHoldRq 7;
BA_ "RoutingFactor" SG_ 2160080129 VCU_HydBrkFcHoldRq 5;
BA_ "Version" SG_ 2160080129 VCU_HydBrkFcHoldRq "22.03.02";
BA_ "GenMsgSendType" BO_ 2160080130 0;
BA_ "GenMsgCycleTime" BO_ 2160080130 50;
BA_ "GenMsgCycleTimeFast" BO_ 2160080130 0;
BA_ "GenMsgNrOfRepetition" BO_ 2160080130 0;
BA_ "VFrameFormat" BO_ 2160080130 1;
BA_ "Description" SG_ 2160080130 VCU_FatcPwrUseVal "Predicted HVAC Power Consumption";
BA_ "UserSigValidity" SG_ 2160080130 VCU_FatcPwrUseVal 7;
BA_ "RoutingFactor" SG_ 2160080130 VCU_FatcPwrUseVal 5;
BA_ "Version" SG_ 2160080130 VCU_FatcPwrUseVal "20.04.05";
BA_ "Description" SG_ 2160080130 VCU_McuAntiJerkInhFrntSta "Anti-jerk Inhibition";
BA_ "GenSigStartValue" SG_ 2160080130 VCU_McuAntiJerkInhFrntSta 1;
BA_ "UserSigValidity" SG_ 2160080130 VCU_McuAntiJerkInhFrntSta 7;
BA_ "RoutingFactor" SG_ 2160080130 VCU_McuAntiJerkInhFrntSta 5;
BA_ "Version" SG_ 2160080130 VCU_McuAntiJerkInhFrntSta "20.04.05";
BA_ "Description" SG_ 2160080130 VCU_McuAntiJerkInhRearSta "Anti-jerk Inhibition";
BA_ "GenSigStartValue" SG_ 2160080130 VCU_McuAntiJerkInhRearSta 1;
BA_ "UserSigValidity" SG_ 2160080130 VCU_McuAntiJerkInhRearSta 7;
BA_ "RoutingFactor" SG_ 2160080130 VCU_McuAntiJerkInhRearSta 5;
BA_ "Version" SG_ 2160080130 VCU_McuAntiJerkInhRearSta "20.04.05";
BA_ "Description" SG_ 2160080130 VCU_McuPwrLatchHoldReq "Mcu Power Latch Hold Request";
BA_ "UserSigValidity" SG_ 2160080130 VCU_McuPwrLatchHoldReq 7;
BA_ "RoutingFactor" SG_ 2160080130 VCU_McuPwrLatchHoldReq 5;
BA_ "Version" SG_ 2160080130 VCU_McuPwrLatchHoldReq "20.04.05";
BA_ "Description" SG_ 2160080130 VCU_ScuParkReq "Parking Command Request";
BA_ "UserSigValidity" SG_ 2160080130 VCU_ScuParkReq 7;
BA_ "RoutingFactor" SG_ 2160080130 VCU_ScuParkReq 5;
BA_ "Version" SG_ 2160080130 VCU_ScuParkReq "20.04.05";
BA_ "Description" SG_ 2160080130 VCU_MotTqCmdFrntVal "Torque Command for Front Motor";
BA_ "UserSigValidity" SG_ 2160080130 VCU_MotTqCmdFrntVal 7;
BA_ "RoutingFactor" SG_ 2160080130 VCU_MotTqCmdFrntVal 5;
BA_ "Version" SG_ 2160080130 VCU_MotTqCmdFrntVal "20.04.05";
BA_ "Description" SG_ 2160080130 VCU_ScuKeepWakeReq "SCU Keep Wake Request";
BA_ "UserSigValidity" SG_ 2160080130 VCU_ScuKeepWakeReq 7;
BA_ "RoutingFactor" SG_ 2160080130 VCU_ScuKeepWakeReq 5;
BA_ "Version" SG_ 2160080130 VCU_ScuKeepWakeReq "20.04.05";
BA_ "Description" SG_ 2160080130 VCU_MotTqCmdRearVal "Torque Command for Rear Motor";
BA_ "UserSigValidity" SG_ 2160080130 VCU_MotTqCmdRearVal 7;
BA_ "RoutingFactor" SG_ 2160080130 VCU_MotTqCmdRearVal 5;
BA_ "Version" SG_ 2160080130 VCU_MotTqCmdRearVal "20.04.05";
BA_ "Description" SG_ 2160080130 VCU_FmcuZeroTqOfsReq "Fmcu Zero Torque Offset Request";
BA_ "UserSigValidity" SG_ 2160080130 VCU_FmcuZeroTqOfsReq 7;
BA_ "RoutingFactor" SG_ 2160080130 VCU_FmcuZeroTqOfsReq 5;
BA_ "Version" SG_ 2160080130 VCU_FmcuZeroTqOfsReq "20.04.05";
BA_ "Description" SG_ 2160080130 VCU_WhlDemTqVal "Driver's Demand Torque Restricted by Battery Limit and HHT Temperature";
BA_ "UserSigValidity" SG_ 2160080130 VCU_WhlDemTqVal 7;
BA_ "RoutingFactor" SG_ 2160080130 VCU_WhlDemTqVal 5;
BA_ "Version" SG_ 2160080130 VCU_WhlDemTqVal "20.04.05";
BA_ "GenMsgSendType" BO_ 2160080131 0;
BA_ "GenMsgCycleTime" BO_ 2160080131 50;
BA_ "GenMsgCycleTimeFast" BO_ 2160080131 0;
BA_ "GenMsgNrOfRepetition" BO_ 2160080131 0;
BA_ "VFrameFormat" BO_ 2160080131 1;
BA_ "Description" SG_ 2160080131 VCU_EcmSeqSta "This signal is VCU System Status Information.";
BA_ "UserSigValidity" SG_ 2160080131 VCU_EcmSeqSta 7;
BA_ "RoutingFactor" SG_ 2160080131 VCU_EcmSeqSta 5;
BA_ "Version" SG_ 2160080131 VCU_EcmSeqSta "20.04.05";
BA_ "Description" SG_ 2160080131 VCU_CltActDiagSta "Clutch Actuator Diag Code";
BA_ "UserSigValidity" SG_ 2160080131 VCU_CltActDiagSta 7;
BA_ "RoutingFactor" SG_ 2160080131 VCU_CltActDiagSta 5;
BA_ "Version" SG_ 2160080131 VCU_CltActDiagSta "20.04.05";
BA_ "Description" SG_ 2160080131 VCU_CltActDrvCrntVal "Clutch Actuator Drive Current";
BA_ "UserSigValidity" SG_ 2160080131 VCU_CltActDrvCrntVal 7;
BA_ "RoutingFactor" SG_ 2160080131 VCU_CltActDrvCrntVal 5;
BA_ "Version" SG_ 2160080131 VCU_CltActDrvCrntVal "20.04.05";
BA_ "Description" SG_ 2160080131 VCU_CltActPosStrokeVal "Clutch Actuator Position Stroke";
BA_ "UserSigValidity" SG_ 2160080131 VCU_CltActPosStrokeVal 7;
BA_ "RoutingFactor" SG_ 2160080131 VCU_CltActPosStrokeVal 5;
BA_ "Version" SG_ 2160080131 VCU_CltActPosStrokeVal "20.04.05";
BA_ "Description" SG_ 2160080131 VCU_MainBattTypeSta "Main Battery Type";
BA_ "UserSigValidity" SG_ 2160080131 VCU_MainBattTypeSta 7;
BA_ "RoutingFactor" SG_ 2160080131 VCU_MainBattTypeSta 5;
BA_ "Version" SG_ 2160080131 VCU_MainBattTypeSta "20.08.07";
BA_ "Description" SG_ 2160080131 VCU_MainBattTypeLrnSta "Learn Status of Main Batt. Type";
BA_ "UserSigValidity" SG_ 2160080131 VCU_MainBattTypeLrnSta 7;
BA_ "RoutingFactor" SG_ 2160080131 VCU_MainBattTypeLrnSta 5;
BA_ "Version" SG_ 2160080131 VCU_MainBattTypeLrnSta "20.04.05";
BA_ "Description" SG_ 2160080131 VCU_WarmupCycSta "Warm-up Cycle Status Flag for FRF output to other ECU's";
BA_ "UserSigValidity" SG_ 2160080131 VCU_WarmupCycSta 7;
BA_ "RoutingFactor" SG_ 2160080131 VCU_WarmupCycSta 5;
BA_ "Version" SG_ 2160080131 VCU_WarmupCycSta "20.04.05";
BA_ "Description" SG_ 2160080131 VCU_FatcPermPwrVal "Climate Permission Power";
BA_ "UserSigValidity" SG_ 2160080131 VCU_FatcPermPwrVal 7;
BA_ "RoutingFactor" SG_ 2160080131 VCU_FatcPermPwrVal 5;
BA_ "Version" SG_ 2160080131 VCU_FatcPermPwrVal "20.04.05";
BA_ "UserSigValidity" SG_ 2160080131 VCU_EcmDiagSta 7;
BA_ "RoutingFactor" SG_ 2160080131 VCU_EcmDiagSta 5;
BA_ "Version" SG_ 2160080131 VCU_EcmDiagSta "20.04.05";
BA_ "GenMsgSendType" BO_ 2160080132 0;
BA_ "GenMsgCycleTime" BO_ 2160080132 50;
BA_ "GenMsgCycleTimeFast" BO_ 2160080132 0;
BA_ "GenMsgNrOfRepetition" BO_ 2160080132 0;
BA_ "VFrameFormat" BO_ 2160080132 1;
BA_ "Description" SG_ 2160080132 VCU_GearPosStaDisp "Gear Position Status for CLU display";
BA_ "GenSigStartValue" SG_ 2160080132 VCU_GearPosStaDisp 9;
BA_ "UserSigValidity" SG_ 2160080132 VCU_GearPosStaDisp 7;
BA_ "RoutingFactor" SG_ 2160080132 VCU_GearPosStaDisp 5;
BA_ "Version" SG_ 2160080132 VCU_GearPosStaDisp "20.12.04";
BA_ "Description" SG_ 2160080132 VCU_PMPDActSta "PMPD Function Active State";
BA_ "UserSigValidity" SG_ 2160080132 VCU_PMPDActSta 7;
BA_ "RoutingFactor" SG_ 2160080132 VCU_PMPDActSta 5;
BA_ "Version" SG_ 2160080132 VCU_PMPDActSta "23.06.01";
BA_ "UserSigValidity" SG_ 2160080132 VCU_PdwLmtBrkRequest 7;
BA_ "RoutingFactor" SG_ 2160080132 VCU_PdwLmtBrkRequest 5;
BA_ "Version" SG_ 2160080132 VCU_PdwLmtBrkRequest "21.12.00";
BA_ "Description" SG_ 2160080132 VCU_VgsVirSoundBackFireIndex "Virtual sound back fire noise index for VGS mode";
BA_ "UserSigValidity" SG_ 2160080132 VCU_VgsVirSoundBackFireIndex 7;
BA_ "RoutingFactor" SG_ 2160080132 VCU_VgsVirSoundBackFireIndex 5;
BA_ "Version" SG_ 2160080132 VCU_VgsVirSoundBackFireIndex "21.12.02";
BA_ "Description" SG_ 2160080132 VCU_VgsVirEngSpdRpmVal "Virtual engine speed for VGS mode";
BA_ "UserSigValidity" SG_ 2160080132 VCU_VgsVirEngSpdRpmVal 7;
BA_ "RoutingFactor" SG_ 2160080132 VCU_VgsVirEngSpdRpmVal 5;
BA_ "Version" SG_ 2160080132 VCU_VgsVirEngSpdRpmVal "21.12.02";
BA_ "Description" SG_ 2160080132 VCU_PdlStopCtrlSta "Cooperative control state of VCU for stop assist control with IEB";
BA_ "UserSigValidity" SG_ 2160080132 VCU_PdlStopCtrlSta 7;
BA_ "RoutingFactor" SG_ 2160080132 VCU_PdlStopCtrlSta 5;
BA_ "Version" SG_ 2160080132 VCU_PdlStopCtrlSta "21.08.08";
BA_ "Description" SG_ 2160080132 VCU_VgsVirSoundVolume "Virtual engine sound volume for VGS mode[%]";
BA_ "UserSigValidity" SG_ 2160080132 VCU_VgsVirSoundVolume 7;
BA_ "RoutingFactor" SG_ 2160080132 VCU_VgsVirSoundVolume 5;
BA_ "Version" SG_ 2160080132 VCU_VgsVirSoundVolume "21.12.02";
BA_ "Description" SG_ 2160080132 VCU_VgsVirGearStep "Shift gear when entering VGS mode";
BA_ "UserSigValidity" SG_ 2160080132 VCU_VgsVirGearStep 7;
BA_ "RoutingFactor" SG_ 2160080132 VCU_VgsVirGearStep 5;
BA_ "Version" SG_ 2160080132 VCU_VgsVirGearStep "21.12.02";
BA_ "Description" SG_ 2160080132 VCU_PdlStopReqTqNmVal "Requested brake torque for cooperative stop assist control";
BA_ "UserSigValidity" SG_ 2160080132 VCU_PdlStopReqTqNmVal 7;
BA_ "RoutingFactor" SG_ 2160080132 VCU_PdlStopReqTqNmVal 5;
BA_ "Version" SG_ 2160080132 VCU_PdlStopReqTqNmVal "21.08.08";
BA_ "Description" SG_ 2160080132 VCU_StandbyModSta "Stand by Mode Status";
BA_ "UserSigValidity" SG_ 2160080132 VCU_StandbyModSta 7;
BA_ "RoutingFactor" SG_ 2160080132 VCU_StandbyModSta 5;
BA_ "Version" SG_ 2160080132 VCU_StandbyModSta "22.05.04";
VAL_ 1546 AMP_SupportBeepVolumeControl 0 "Null" 1 "False" 2 "True" 3 "Invalid" ;
VAL_ 1546 AMP_SupportDSC 0 "Null" 1 "False" 2 "True" 3 "Invalid" ;
VAL_ 1546 AMP_SupportANCMode 0 "Null" 1 "False" 2 "True" 3 "Invalid" ;
VAL_ 1546 AMP_MakerID 0 "Initial Value" 1 "Mobis" 2 "Beats by Dr.Dre" 3 "Harman_Becker" 4 "BOSE" 5 "Bang&Olufsen" 6 "Meridian" 7 "Audio by Bang&Olufsen" 8 "0x08~0xFF:Invalid" 255 "0x08~0xFF:Invalid" ;
VAL_ 1546 AMP_SupportQLS 0 "Null" 1 "False" 2 "True" 3 "Invalid" ;
VAL_ 1546 AMP_SupportHorizon 0 "Null" 1 "False" 2 "True" 3 "Invalid" ;
VAL_ 1546 AMP_SupportASDMode 0 "Null" 1 "False" 2 "True" 3 "Invalid" ;
VAL_ 1546 AMP_SupportIntelliQ 0 "Null" 1 "False" 2 "True" 3 "Invalid" ;
VAL_ 1546 AMP_SupportCenterpoint 0 "Null" 1 "False" 2 "True" 3 "Invalid" ;
VAL_ 1546 AMP_SupportLiveDynamicMode 0 "Null" 1 "False" 2 "True(Off On)" 3 "True(Off Natural Concert)" 4 "RESERVED" 5 "RESERVED" 6 "RESERVED" 7 "Invalid" ;
VAL_ 1546 AMP_Support_ElecSound 0 "Null" 1 "False" 2 "True" 3 "Invalid" ;
VAL_ 678 Ast_AutoRlxWrngDis 0 "Off" 1 "Auto relax Enable" 2 "Mode-Fail (Vehicle Speed Warning)" 3 "Mode-Fail (Not P Warning)" 4 "Mode-Fail (2nd Seat Belted)" 5 "Mode-Fail (Not Initialized)" 6 "Mode-Fail (2nd Seat Position Warning)" 7 "Invaild" ;
VAL_ 678 APSM_IMSWngDis 0 "Default" 1 "Inhibit Ast IMS" 2 "Reserved" 3 "Invaild" ;
VAL_ 678 Ast_2ndLnkRtnStop 0 "Default" 1 "Return Stop" 2 "Return Fail" 3 "Invalid" ;
VAL_ 678 Ast_2ndStStdPosMovReq 0 "Default" 1 "ON" 2 "Reserved" 3 "Invalid" ;
VAL_ 678 AstIMS_AMPBzrReq 0 "Off" 1 "On (LHD)" 2 "On (RHD)" 3 "Error Indicator" ;
VAL_ 678 Ast_AutoRlxWrngDis_2 0 "Off" 1 "2nd Seat Moving" 2 "2nd Seat Repositioning" 3 "RESERVED" 4 "RESERVED" 5 "RESERVED" 6 "RESERVED" 7 "Invaild" ;
VAL_ 591 ATS_RLStSldFwdBtn 0 "Default" 1 "Off" 2 "On" 3 "Reserved" ;
VAL_ 591 ATS_RLStSldBwdBtn 0 "Default" 1 "Off" 2 "On" 3 "Reserved" ;
VAL_ 591 ATS_RLStRclFwdBtn 0 "Default" 1 "Off" 2 "On" 3 "Reserved" ;
VAL_ 591 ATS_RLStRclBwdBtn 0 "Default" 1 "Off" 2 "On" 3 "Reserved" ;
VAL_ 591 ATS_RLStTltUpBtn 0 "Default" 1 "Off" 2 "On" 3 "Reserved" ;
VAL_ 591 ATS_RLStTltDnBtn 0 "Default" 1 "Off" 2 "On" 3 "Reserved" ;
VAL_ 591 ATS_RLStHRestUpBtn 0 "Default" 1 "Off" 2 "On" 3 "Reserved" ;
VAL_ 591 ATS_RLStHRestDnBtn 0 "Default" 1 "Off" 2 "On" 3 "Reserved" ;
VAL_ 591 ATS_RLStHRestFwdBtn 0 "Default" 1 "Off" 2 "On" 3 "Reserved" ;
VAL_ 591 ATS_RLStHRestBwdBtn 0 "Default" 1 "Off" 2 "On" 3 "Reserved" ;
VAL_ 591 ATS_RLStLegRestUpBtn 0 "Default" 1 "Off" 2 "On" 3 "Reserved" ;
VAL_ 591 ATS_RLStLegRestDnBtn 0 "Default" 1 "Off" 2 "On" 3 "Reserved" ;
VAL_ 591 ATS_RLStLegRestExtUpBtn 0 "Default" 1 "Off" 2 "On" 3 "Reserved" ;
VAL_ 591 ATS_RLStLegRestExtDnBtn 0 "Default" 1 "Off" 2 "On" 3 "Reserved" ;
VAL_ 591 ATS_RLStShoulderADJFwdBtn 0 "Default" 1 "Off" 2 "On" 3 "Reserved" ;
VAL_ 591 ATS_RLStShoulderADJBwdBtn 0 "Default" 1 "Off" 2 "On" 3 "Reserved" ;
VAL_ 639 ATS_RRSeatHeaterSW 0 "Default" 1 "Short On" 2 "Long On" 3 "Invalid" ;
VAL_ 639 ATS_RLSeatHeaterUpSW 0 "Default" 1 "Short On" 2 "Long On" 3 "Invalid" ;
VAL_ 639 ATS_RRSeatVentDownSW 0 "Default" 1 "Short On" 2 "Long On" 3 "Invalid" ;
VAL_ 639 ATS_RLSeatVentDownSW 0 "Default" 1 "Short On" 2 "Long On" 3 "Invalid" ;
VAL_ 639 ATS_RLMemoryRestBtn 0 "Default" 1 "Off" 2 "On" 3 "Invalid" ;
VAL_ 639 ATS_RLMemoryReturnBtn 0 "Default" 1 "Off" 2 "On" 3 "Invalid" ;
VAL_ 639 ATS_RLSeatHeaterSW 0 "Default" 1 "Short On" 2 "Long On" 3 "Invalid" ;
VAL_ 639 ATS_RRMemoryRestBtn 0 "Default" 1 "Off" 2 "On" 3 "Invalid" ;
VAL_ 639 ATS_RRMemoryReturnBtn 0 "Default" 1 "Off" 2 "On" 3 "Invalid" ;
VAL_ 639 ATS_RRMemoryAvWtcBtn 0 "Default" 1 "Off" 2 "On" 3 "Invalid" ;
VAL_ 639 ATS_RRMemoryReadingBtn 0 "Default" 1 "Off" 2 "On" 3 "Invalid" ;
VAL_ 639 ATS_RRRestModBtnSTD 0 "Default" 1 "Off" 2 "On" 3 "Invalid" ;
VAL_ 639 ATS_RRResetModBtnSTD 0 "Default" 1 "Off" 2 "On" 3 "Invalid" ;
VAL_ 639 ATS_RRAvWtcModBtnSTD 0 "Default" 1 "Off" 2 "On" 3 "Invalid" ;
VAL_ 639 ATS_RRReadingModBtnSTD 0 "Default" 1 "Off" 2 "On" 3 "Invalid" ;
VAL_ 639 ATS_RRSeatVentSW 0 "Default" 1 "Short On" 2 "Long On" 3 "Invalid" ;
VAL_ 639 ATS_RLRestModBtnSTD 0 "Default" 1 "Off" 2 "On" 3 "Invalid" ;
VAL_ 639 ATS_RLResetModBtnSTD 0 "Default" 1 "Off" 2 "On" 3 "Invalid" ;
VAL_ 639 ATS_RRModestateStopBtn 0 "Default" 1 "Off" 2 "On" 3 "Invalid" ;
VAL_ 639 ATS_RLModestateStopBtn 0 "Default" 1 "Off" 2 "On" 3 "Invalid" ;
VAL_ 639 ATS_RLResetRestBtn 0 "Default" 1 "Off" 2 "On" 3 "Invalid" ;
VAL_ 639 ATS_RLResetReturnBtn 0 "Default" 1 "Off" 2 "On" 3 "Invalid" ;
VAL_ 639 ATS_RRResetRestBtn 0 "Default" 1 "Off" 2 "On" 3 "Invalid" ;
VAL_ 639 ATS_RRResetReturnBtn 0 "Default" 1 "Off" 2 "On" 3 "Invalid" ;
VAL_ 639 ATS_RRResetAvWtcBtn 0 "Default" 1 "Off" 2 "On" 3 "Invalid" ;
VAL_ 639 ATS_RRResetReadingBtn 0 "Default" 1 "Off" 2 "On" 3 "Invalid" ;
VAL_ 639 ATS_RLSeatVentSW 0 "Default" 1 "Short On" 2 "Long On" 3 "Invalid" ;
VAL_ 639 ATS_RRSeatHeaterUpSW 0 "Default" 1 "Short On" 2 "Long On" 3 "Invalid" ;
VAL_ 607 ATS_RRStSldFwdBtn 0 "Default" 1 "Off" 2 "On" 3 "Reserved" ;
VAL_ 607 ATS_RRStSldBwdBtn 0 "Default" 1 "Off" 2 "On" 3 "Reserved" ;
VAL_ 607 ATS_RRStRclFwdBtn 0 "Default" 1 "Off" 2 "On" 3 "Reserved" ;
VAL_ 607 ATS_RRStRclBwdBtn 0 "Default" 1 "Off" 2 "On" 3 "Reserved" ;
VAL_ 607 ATS_RRStTltUpBtn 0 "Default" 1 "Off" 2 "On" 3 "Reserved" ;
VAL_ 607 ATS_RRStTltDnBtn 0 "Default" 1 "Off" 2 "On" 3 "Reserved" ;
VAL_ 607 ATS_RRStLegRestPopBtn 0 "Default" 1 "Off" 2 "On" 3 "Reserved" ;
VAL_ 607 ATS_RRStFRestPopBtn 0 "Default" 1 "Off" 2 "On" 3 "Reserved" ;
VAL_ 607 ATS_RRStAstPopBtn 0 "Default" 1 "Off" 2 "On" 3 "Reserved" ;
VAL_ 607 ATS_RRFauCondiBtn 0 "Default" 1 "Off" 2 "On" 3 "Reserved" ;
VAL_ 607 ATS_RRStHRestUpBtn 0 "Default" 1 "Off" 2 "On" 3 "Reserved" ;
VAL_ 607 ATS_RRStHRestDnBtn 0 "Default" 1 "Off" 2 "On" 3 "Reserved" ;
VAL_ 607 ATS_RRStHRestFwdBtn 0 "Default" 1 "Off" 2 "On" 3 "Reserved" ;
VAL_ 607 ATS_RRStHRestBwdBtn 0 "Default" 1 "Off" 2 "On" 3 "Reserved" ;
VAL_ 607 ATS_RRStShoulderADJFwdBtn 0 "Default" 1 "Off" 2 "On" 3 "Reserved" ;
VAL_ 607 ATS_RRStShoulderADJBwdBtn 0 "Default" 1 "Off" 2 "On" 3 "Reserved" ;
VAL_ 607 ATS_RRStLegRestUpBtn 0 "Default" 1 "Off" 2 "On" 3 "Reserved" ;
VAL_ 607 ATS_RRStLegRestDnBtn 0 "Default" 1 "Off" 2 "On" 3 "Reserved" ;
VAL_ 607 ATS_RRStLegRestExtUpBtn 0 "Default" 1 "Off" 2 "On" 3 "Reserved" ;
VAL_ 607 ATS_RRStLegRestExtDnBtn 0 "Default" 1 "Off" 2 "On" 3 "Reserved" ;
VAL_ 679 CMS_RH_Crc1Val 0 "0x0x0~0xFF:CRCValue" 255 "0x0x0~0xFF:CRCValue" ;
VAL_ 679 CMS_RH_AlvCnt1Val 0 "AlvCntValue" 1 "AlvCntValue" 2 "AlvCntValue" 3 "AlvCntValue" 4 "AlvCntValue" 5 "AlvCntValue" 6 "AlvCntValue" 7 "AlvCntValue" 8 "AlvCntValue" 9 "AlvCntValue" 10 "AlvCntValue" 11 "AlvCntValue" 12 "AlvCntValue" 13 "AlvCntValue" 14 "AlvCntValue" 15 "AlvCntValue" ;
VAL_ 679 USM_CMSDayBrgtnsLvlRHSta 0 "-5 Level" 1 "-4 Level" 2 "-3 Level" 3 "-2 Level" 4 "-1 Level" 5 "0 Level" 6 "1 Level" 7 "2 Level" 8 "3 Level" 9 "4 Level" 10 "5 Level" 11 "RESERVED" 12 "RESERVED" 13 "RESERVED" 14 "Error Indicator" 15 "RESERVED" ;
VAL_ 679 USM_CMSNgtBrgtnsLvlRHSta 0 "-5 Level" 1 "-4 Level" 2 "-3 Level" 3 "-2 Level" 4 "-1 Level" 5 "0 Level" 6 "1 Level" 7 "2 Level" 8 "3 Level" 9 "4 Level" 10 "5 Level" 11 "RESERVED" 12 "RESERVED" 13 "RESERVED" 14 "Error Indicator" 15 "RESERVED" ;
VAL_ 679 IMS_CMSPlayBackSta_RH 0 "Stop" 1 "Play 1" 2 "Play 2" 3 "Play 3" 4 "Smart IMS" 5 "Profile 1" 6 "Profile 2" 7 "Guest" 8 "RESERVED" 9 "RESERVED" 10 "RESERVED" 11 "RESERVED" 12 "RESERVED" 13 "RESERVED" 14 "RESERVED" 15 "Error Indicator" ;
VAL_ 679 MonitorStatus 0 "Default" 1 "Off" 2 "On" 3 "RESERVED" ;
VAL_ 679 CMS_RH_FoldingSta 0 "Off" 1 "Folding" 2 "RESERVED" 3 "Error Indicator" ;
VAL_ 679 CMS_RH_UnfoldingSta 0 "Off" 1 "Unfolding" 2 "RESERVED" 3 "Error Indicator" ;
VAL_ 679 CMS_RHVerPosVal 0 "0x0x00~0xFA:Real values" 250 "0x0x00~0xFA:Real values" 251 "RESERVED" 252 "RESERVED" 253 "RESERVED" 254 "RESERVED" 255 "Error Indicator" ;
VAL_ 679 CMS_RHHorPosVal 0 "0x0x00~0xFA:Real values" 250 "0x0x00~0xFA:Real values" 251 "RESERVED" 252 "RESERVED" 253 "RESERVED" 254 "RESERVED" 255 "Error Indicator" ;
VAL_ 2424579841 DATC_Crc11Val 0 "0x0x0~0xFFFF:CRCValue" 65535 "0x0x0~0xFFFF:CRCValue" ;
VAL_ 2424579841 DATC_AlvCnt11Val 0 "0x0x0~0xFF:AlvCntValue" 255 "0x0x0~0xFF:AlvCntValue" ;
VAL_ 2424579841 DATC_TunnelFuncOff4AutoDfgReq 0 "Default" 1 "Tunnel Turn off" 2 "Reserved" 3 "Error Indicator" ;
VAL_ 2424579841 DATC_RrCtlLckSta 0 "Default" 1 "Rear Lock OFF" 2 "Rear Lock ON" 3 "Error Indicator" ;
VAL_ 2424579841 DATC_DrvrStHtrUSMSta 0 "NOT APPLY" 1 "OFF" 2 "ON" 3 "Error Indicator" ;
VAL_ 2424579841 DATC_WshFldUSMSta 0 "Default" 1 "OFF" 2 "ON" 3 "Invalid" ;
VAL_ 2424579841 DATC_DfgLgcUSMSta 0 "Default" 1 "OFF" 2 "ON" 3 "Invalid" ;
VAL_ 2424579841 DATC_AutoFrshUSMSta 0 "Default" 1 "OFF" 2 "ON" 3 "Invalid" ;
VAL_ 2424579841 DATC_HptIntnstySta 0 "Default" 1 "Haptic OFF" 2 "Haptic Intensity Level 1" 3 "Haptic Intensity Level 2" 4 "Haptic Intensity Level 3" 5 "Haptic Intensity Level 4" 6 "Haptic Intensity Level 5" 7 "Reserved" 8 "Reserved" 9 "Reserved" 10 "Reserved" 11 "Reserved" 12 "Reserved" 13 "Reserved" 14 "Reserved" 15 "Invalid" ;
VAL_ 687 HOD_Crc1Val 0 "0x0x0~0xFF:CRCValue" 255 "0x0x0~0xFF:CRCValue" ;
VAL_ 687 HOD_AlvCnt1Val 0 "AlvCntValue" 1 "AlvCntValue" 2 "AlvCntValue" 3 "AlvCntValue" 4 "AlvCntValue" 5 "AlvCntValue" 6 "AlvCntValue" 7 "AlvCntValue" 8 "AlvCntValue" 9 "AlvCntValue" 10 "AlvCntValue" 11 "AlvCntValue" 12 "AlvCntValue" 13 "AlvCntValue" 14 "AlvCntValue" 15 "AlvCntValue" ;
VAL_ 687 HOD_Dir_Status 0 "HANDS OFF" 1 "HAND TOUCH (SOFT)" 2 "HAND TOUCH (STRONG)" 3 "HAND GRIP (SOFT)" 4 "HAND GRIP (STRONG)" 5 "RESERVED" 6 "RESERVED" 7 "INVALID" ;
VAL_ 687 HOD_Option 0 "HOD-Option-OFF" 1 "HOD-Option-On" 2 "RESERVED" 3 "RESERVED" ;
VAL_ 687 HOD_CapaCh0 0 "0x0x00~0xFE:REAL VALUES" 254 "0x0x00~0xFE:REAL VALUES" 255 "invalid" ;
VAL_ 687 HOD_CapaCh1 0 "0x0x00~0xFE:REAL VALUES" 254 "0x0x00~0xFE:REAL VALUES" 255 "invalid" ;
VAL_ 687 HOD_HDPSpprtSWVer 0 "REAL VALUES" 1 "REAL VALUES" 2 "REAL VALUES" 3 "REAL VALUES" 4 "REAL VALUES" 5 "REAL VALUES" 6 "REAL VALUES" 7 "REAL VALUES" 8 "REAL VALUES" 9 "REAL VALUES" 10 "REAL VALUES" 11 "REAL VALUES" 12 "REAL VALUES" 13 "REAL VALUES" 14 "REAL VALUES" 15 "REAL VALUES" 16 "REAL VALUES" 17 "REAL VALUES" 18 "REAL VALUES" 19 "REAL VALUES" 20 "REAL VALUES" 21 "REAL VALUES" 22 "REAL VALUES" 23 "REAL VALUES" 24 "REAL VALUES" 25 "REAL VALUES" 26 "REAL VALUES" 27 "REAL VALUES" 28 "REAL VALUES" 29 "REAL VALUES" 30 "REAL VALUES" 31 "Invalid" ;
VAL_ 2176872450 HDCT_TCURdySta 0 "Not ready" 1 "Ready" 2 "Not used" 3 "Error Indicator" ;
VAL_ 2176872450 HDCT_NetrlCtrlSta 0 "Not complete" 1 "Complete" 2 "Not used" 3 "Error Indicator" ;
VAL_ 2176872450 HDCT_GearShftSta 0 "Inactive" 1 "Active" 2 "Not used" 3 "Error Indicator" ;
VAL_ 2176872450 HDCT_CtrlablSta 0 "Not Ready" 1 "Controllable" 2 "Not used" 3 "Error Indicator" ;
VAL_ 2176872450 HDCT_TqIncReq 0 "Passive" 1 "Torque increase controls" 2 "Not used" 3 "Error Indicator" ;
VAL_ 2176872450 HDCT_TrgtShftCls 0 "static" 1 "Pon UP" 2 "Poff UP" 3 "reserve" 4 "Pon DN" 5 "PoffDn(manual)" 6 "NSTP to 5;4;3;2" 7 "NSTP to 1" 8 "reserve" 9 "reserve" 10 "reserve" 11 "reserve" 12 "reserve" 13 "reserve" 14 "reserve" ;
VAL_ 2176872450 HDCT_EOLReq 0 "No request" 1 "EOL request" 2 "Not used" 3 "Error Indicator" ;
VAL_ 2176872450 HDCT_CltchSta 0 "Open" 1 "Slip" 2 "Locked" 3 "Locked&Micro Slip" ;
VAL_ 2176872450 HDCT_DblCltchSta 0 "CS_Open" 1 "CS_TakeUp" 2 "CS_Engage" 3 "CS_Shift" 4 "CS_Drive" 5 "CS_Disengage" 6 "CS_SpinRequest" 7 "CS_TestMode" 8 "CS_Initialize" 9 "CS_Fail" ;
VAL_ 2176872450 HDCT_AcnChrgInhbtReq 0 "-" 1 "Freeze AC clutch" 2 "Not used" 3 "Error Indicator" ;
VAL_ 2176872450 HDCT_KckDnSkpShftCnt 0 "Normal K/D(No Skipº¯¼Ó) or No shift" 1 "1st Skip K/D" 2 "2nd Skip K/D" 3 "Error Indicator" ;
VAL_ 2176872450 HDCT_ShftPhase 0 "No shift" 1 "A0 (Prepataion for shift)" 2 "A1 (Prepataion for shift)" 3 "A2 (Prepataion for shift)" 4 "A3 (Prepataion for shift)" 5 "B1 (Beginning of shift)" 6 "B2 (Beginning of shift)" 7 "B3 (Beginning of shift)" 8 "B4 (Beginning of shift)" 9 "C1 (Duration of actual shift)" 10 "C2 (Duration of actual shift)" 11 "C3 (Duration of actual shift)" 12 "D1 (Duration of actual shift)" 13 "E1 (Finishing shift)" 14 "E2 (Finishing shift)" 15 "E3 (Finishing shift)" 16 "END (Shift End)" ;
VAL_ 2176872451 HDCT_FuelCutReq 0 "No Fuel Cut request" 1 "Activation of Fuel Cut request" 2 "Not used" 3 "Error Indicator" ;
VAL_ 2176872451 HDCT_NCoastTrgtGear 0 "gN" 1 "g1" 2 "g2" 3 "g3" 4 "g4" 5 "g5" 6 "g6" 7 "None" 8 "None" 9 "None" 10 "None" 11 "None" 12 "None" 13 "None" 14 "None" 15 "gR" ;
VAL_ 2176872451 HDCT_CLUEngSpdFlag 0 "Off" 1 "On" 2 "Not used" 3 "Error Indicator" ;
VAL_ 2176872451 HDCT_CLUTrgtGear 0 "If N or P are detected(No frictional conncetion)" 1 "1st speed" 2 "2nd speed" 3 "3rd speed" 4 "4th speed" 5 "5th speed" 6 "6th speed" 7 "7th speed" 15 "Reverse" ;
VAL_ 2176872451 HDCT_GSITrgtGear 0 "Neutral (Initial Value)" 1 "1st speed" 2 "2nd speed" 3 "3rd speed" 4 "4th speed" 5 "5th speed" 6 "6th speed" 7 "Reserved" 8 "Reserved" 9 "Reserved" 10 "Reserved" 11 "Reserved" 12 "Reserved" 13 "Reserved" 14 "Reserved" 15 "Reserved" ;
VAL_ 2176872451 HDCT_NCoastDnReq 0 "Off" 1 "On" 2 "Not used" 3 "Error Indicator" ;
VAL_ 2176872451 HDCT_CLUEngSpd 8191 "Error Indicator" ;
VAL_ 1584 AMP_NaviWarnSound 0 "Navi Warning Off" 1 "Navi Warning On" 2 "Unused" 3 "Invalid" ;
VAL_ 1584 AMP_Beep1Mode 0 "Beep1 mode off" 1 "Beep1 mode On" 2 "Unsed" 3 "Invalid" ;
VAL_ 1584 AMP_MasterBeepVolumeStep 0 "level 0" 1 "level 1" 2 "level 2" 3 "level 3" 4 "level 4" 5 "level 5" 6 "Reserved" 7 "Invalid" ;
VAL_ 1584 AMP_RrTTSSound 0 "RrTTS Off" 1 "RrTTS ON" 2 "Unused" 3 "Invalid" ;
VAL_ 1584 AMP_ASDMode 0 "Not use" 1 "ASD OFF" 2 "RESERVED" 3 "ASD ON" 4 "RESERVED" 5 "RESERVED" 6 "RESERVED" 7 "Invalid" ;
VAL_ 1584 AMP_ANCMode 0 "Not used" 1 "ANC Off" 2 "ANC On" 3 "Invalid" ;
VAL_ 1584 AMP_VirtualVenueMode 0 "Off" 1 "Livingroom" 2 "ConcertHall" 3 "Stadium" 4 "Reserved" 5 "Reserved" 6 "Reserved" 7 "Invalid" ;
VAL_ 1584 AMP_QLIMode 0 "Off" 1 "Reference" 2 "Audience" 3 "OnStage" 4 "Reserved" 5 "Reserved" 6 "Reserved" 7 "Invalid" ;
VAL_ 1584 AMP_DriverMode 0 "Off" 1 "On" 2 "Reserved" 3 "Invalid" ;
VAL_ 1584 AMP_NaviSound 0 "Navi Off" 1 "Navi ON" 2 "Unused" 3 "Invalid" ;
VAL_ 1584 AMP_ETCSSound 0 "ETCS Sound Off" 1 "ETCS Sound On" 2 "Unused" 3 "Invalid" ;
VAL_ 1584 AMP_VoiceGuideTTS 0 "Off" 1 "On" 2 "RESERVED" 3 "Invalid" ;
VAL_ 1584 AMP_Beep1KBDMode 0 "Beep1 mode off" 1 "Beep1 mode On" 2 "Unsed" 3 "Invalid" ;
VAL_ 1584 AMP_ETCSVolumeStep 0 "0x0x0~0xFD:ETCS Volume" 253 "0x0x0~0xFD:ETCS Volume" 254 "Req. Amp supported ETCS Set" 255 "Invalid" ;
VAL_ 1584 AMP_NaviWarnVolumeStep 0 "0x0x0~0xFD:Navi Warning Volume" 253 "0x0x0~0xFD:Navi Warning Volume" 254 "Req. amp supported Navi Set" 255 "Invalid" ;
VAL_ 1584 AMP_TTSSound 0 "TTS Off" 1 "TTS ON" 2 "Unused" 3 "Invalid" ;
VAL_ 1584 AMP_SDVCStep 0 "off" 1 "low" 2 "mid" 3 "high" 4 "RESERVED" 5 "RESERVED" 6 "RESERVED" 7 "Invalid" ;
VAL_ 676 C_DrAirSptNValueSet_EC 0 "Default" 1 "Off" 2 "On" 3 "Invalid" ;
VAL_ 676 C_DrCushSoftNValueSet_EC 0 "Default" 1 "Off" 2 "Low" 3 "Mid" 4 "High" 5 "Reserved" 6 "Reserved" 7 "Invalid" ;
VAL_ 676 C_AstAirSptNValueSet_EC 0 "Default" 1 "Off" 2 "On" 3 "Invalid" ;
VAL_ 676 C_AstAirSptModeNValueSet_EC 0 "Default" 1 "Mode 1" 2 "Mode 2" 3 "Mode 3" 4 "Mode 4" 5 "Mode 5" 6 "Reserved" 7 "Invalid" ;
VAL_ 676 C_DrAirSptModeNValueSet_EC 0 "Default" 1 "Mode 1" 2 "Mode 2" 3 "Mode 3" 4 "Mode 4" 5 "Mode 5" 6 "Reserved" 7 "Invalid" ;
VAL_ 676 C_RLAirSptNValueSet_EC 0 "Default" 1 "Off" 2 "On" 3 "Invalid" ;
VAL_ 676 C_AstAirSptStrNValueSet_EC 0 "Default" 1 "Weak" 2 "Normal" 3 "Strong" 4 "Reserved" 5 "Reserved" 6 "Reserved" 7 "Invalid" ;
VAL_ 676 C_AstAirSptTimeNValueSet_EC 0 "Default" 1 "Short" 2 "Normal" 3 "Long" 4 "Reserved" 5 "Reserved" 6 "Reserved" 7 "Invalid" ;
VAL_ 676 C_RRAirSptNValueSet_EC 0 "Default" 1 "Off" 2 "On" 3 "Invalid" ;
VAL_ 676 C_AstCushSoftNValueSet_EC 0 "Default" 1 "Off" 2 "Low" 3 "Mid" 4 "High" 5 "Reserved" 6 "Reserved" 7 "Invalid" ;
VAL_ 676 C_AstRlxNValueSet_EC 0 "Default" 1 "Off" 2 "Return" 3 "Relax" 4 "Reserved" 5 "Reserved" 6 "Reserved" 7 "Invalid" ;
VAL_ 676 C_RLAirSptModeNValueSet_EC 0 "Default" 1 "Mode 1" 2 "Mode 2" 3 "Mode 3" 4 "Mode 4" 5 "Mode 5" 6 "Reserved" 7 "Invalid" ;
VAL_ 676 C_DrAirSptStrNValueSet_EC 0 "Default" 1 "Weak" 2 "Normal" 3 "Strong" 4 "Reserved" 5 "Reserved" 6 "Reserved" 7 "Invalid" ;
VAL_ 676 C_RLAirSptStrNValueSet_EC 0 "Default" 1 "Weak" 2 "Normal" 3 "Strong" 4 "Reserved" 5 "Reserved" 6 "Reserved" 7 "Invalid" ;
VAL_ 676 C_RLAirSptTimeNValueSet_EC 0 "Default" 1 "Short" 2 "Normal" 3 "Long" 4 "Reserved" 5 "Reserved" 6 "Reserved" 7 "Invalid" ;
VAL_ 676 C_DrAirSptTimeNValueSet_EC 0 "Default" 1 "Short" 2 "Normal" 3 "Long" 4 "Reserved" 5 "Reserved" 6 "Reserved" 7 "Invalid" ;
VAL_ 677 C_RRAirSptStrNValueSet_EC 0 "Default" 1 "Weak" 2 "Normal" 3 "Strong" 4 "Reserved" 5 "Reserved" 6 "Reserved" 7 "Invalid" ;
VAL_ 677 C_RRAirSptTimeNValueSet_EC 0 "Default" 1 "Short" 2 "Normal" 3 "Long" 4 "Reserved" 5 "Reserved" 6 "Reserved" 7 "Invalid" ;
VAL_ 677 C_RROneTchNvalueSet_EC 0 "Default" 1 "Off" 2 "Return" 3 "Relax" 4 "AV" 5 "Read" 6 "Reserved" 7 "Invalid" ;
VAL_ 677 C_RLOneTchNValueSet_EC 0 "Default" 1 "Off" 2 "Return" 3 "Relax" 4 "Reserved" 5 "Reserved" 6 "Reserved" 7 "Invalid" ;
VAL_ 677 C_RLOneTchNValueSet_EC_VR 0 "Default" 1 "Off" 2 "Return" 3 "Relax" 4 "RESERVED" 5 "RESERVED" 6 "RESERVED" 7 "Invalid" ;
VAL_ 677 C_RROneTchNvalueSet_EC_VR 0 "Default" 1 "Off" 2 "Return" 3 "Relax" 4 "AV" 5 "Read" 6 "RESERVED" 7 "Invalid" ;
VAL_ 677 C_RRAirSptModeNValueSet_EC 0 "Default" 1 "Mode 1" 2 "Mode 2" 3 "Mode 3" 4 "Mode 4" 5 "Mode 5" 6 "Reserved" 7 "Invalid" ;
VAL_ 577 C_AstBolsterInfSw_HU 0 "Default" 1 "Off" 2 "On" 3 "Invalid" ;
VAL_ 577 C_RLHrestUpSw_HU 0 "Default" 1 "Off" 2 "On" 3 "Invalid" ;
VAL_ 577 C_RLHrestDnSw_HU 0 "Default" 1 "Off" 2 "On" 3 "Invalid" ;
VAL_ 577 C_RLHrestFwdSw_HU 0 "Default" 1 "Off" 2 "On" 3 "Invalid" ;
VAL_ 577 C_AstBolsterDefSw_HU 0 "Default" 1 "Off" 2 "On" 3 "Invalid" ;
VAL_ 577 C_RLHrestBwdSw_HU 0 "Default" 1 "Off" 2 "On" 3 "Invalid" ;
VAL_ 577 C_RLLumbarUpSw_HU 0 "Default" 1 "Off" 2 "On" 3 "Invalid" ;
VAL_ 577 C_RLLumbarMidSw_HU 0 "Default" 1 "Off" 2 "On" 3 "Invalid" ;
VAL_ 577 C_RLLumbarLowSw_HU 0 "Default" 1 "Off" 2 "On" 3 "Invalid" ;
VAL_ 577 C_RLLumbarDefSw_HU 0 "Default" 1 "Off" 2 "On" 3 "Invalid" ;
VAL_ 577 C_RLBolsterInfSw_HU 0 "Default" 1 "Off" 2 "On" 3 "Invalid" ;
VAL_ 577 C_RLBolsterDefSw_HU 0 "Default" 1 "Off" 2 "On" 3 "Invalid" ;
VAL_ 577 C_AstHrestUpSw_HU 0 "Default" 1 "Off" 2 "On" 3 "Invalid" ;
VAL_ 577 C_AstHrestDnSw_HU 0 "Default" 1 "Off" 2 "On" 3 "Invalid" ;
VAL_ 577 C_AstHrestFwdSw_HU 0 "Default" 1 "Off" 2 "On" 3 "Invalid" ;
VAL_ 577 C_AstHrestBwdSw_HU 0 "Default" 1 "Off" 2 "On" 3 "Invalid" ;
VAL_ 578 C_RRLegSupFwdSw_HU 0 "Default" 1 "Off" 2 "On" 3 "Invalid" ;
VAL_ 578 C_RRHrestDnSw_HU 0 "Default" 1 "Off" 2 "On" 3 "Invalid" ;
VAL_ 578 C_RRHrestFwdSw_HU 0 "Default" 1 "Off" 2 "On" 3 "Invalid" ;
VAL_ 578 C_RRHrestBwdSw_HU 0 "Default" 1 "Off" 2 "On" 3 "Invalid" ;
VAL_ 578 C_RRLumbarUpSw_HU 0 "Default" 1 "Off" 2 "On" 3 "Invalid" ;
VAL_ 578 C_RRLumbarMidSw_HU 0 "Default" 1 "Off" 2 "On" 3 "Invalid" ;
VAL_ 578 C_RRLegSupBwdSw_HU 0 "Default" 1 "Off" 2 "On" 3 "Invalid" ;
VAL_ 578 C_RRLumbarLowSw_HU 0 "Default" 1 "Off" 2 "On" 3 "Invalid" ;
VAL_ 578 C_RRLumbarDefSw_HU 0 "Default" 1 "Off" 2 "On" 3 "Invalid" ;
VAL_ 578 C_RRBolsterInfSw_HU 0 "Default" 1 "Off" 2 "On" 3 "Invalid" ;
VAL_ 578 C_RRLegSupUpSw_HU 0 "Default" 1 "Off" 2 "On" 3 "Invalid" ;
VAL_ 578 C_RROneTchNValueSet 0 "Default" 1 "Off" 2 "Return" 3 "Relax" 4 "AV" 5 "Read" 6 "RESERVED" 7 "Invalid" ;
VAL_ 578 C_RLOneTchNValueSet 0 "Default" 1 "Off" 2 "Return" 3 "Relax" 4 "RESERVED" 5 "RESERVED" 6 "RESERVED" 7 "Invalid" ;
VAL_ 578 C_RRBolsterDefSw_HU 0 "Default" 1 "Off" 2 "On" 3 "Invalid" ;
VAL_ 578 C_AstRlxTiltUpSw_HU 0 "Default" 1 "Off" 2 "On" 3 "Invalid" ;
VAL_ 578 C_AstRlxTiltDnSw_HU 0 "Default" 1 "Off" 2 "On" 3 "Invalid" ;
VAL_ 578 C_RLRSEUpSw_HU 0 "Default" 1 "Off" 2 "On" 3 "Invalid" ;
VAL_ 578 C_RLRSEDnSw_HU 0 "Default" 1 "Off" 2 "On" 3 "Invalid" ;
VAL_ 578 C_RRRSEUpSw_HU 0 "Default" 1 "Off" 2 "On" 3 "Invalid" ;
VAL_ 578 C_RRLegSupDnSw_HU 0 "Default" 1 "Off" 2 "On" 3 "Invalid" ;
VAL_ 578 C_RRRSEDnSw_HU 0 "Default" 1 "Off" 2 "On" 3 "Invalid" ;
VAL_ 578 C_RRHrestUpSw_HU 0 "Default" 1 "Off" 2 "On" 3 "Invalid" ;
VAL_ 675 Usm_RpmMUDSet 0 "Default" 1 "Off" 2 "On(RPM Gauge Display)" 3 "Invalid" ;
VAL_ 675 CF_AVN_HtBlcRLNValueSet 0 "Default" 1 "Normal" 2 "Back 1" 3 "Back 2" 4 "Back 3" 5 "Cush 1" 6 "Cush 2" 7 "Cush 3" 8 "Reserved" 9 "Reserved" 10 "Reserved" 11 "Reserved" 12 "Reserved" 13 "Reserved" 14 "Reserved" 15 "Invalid" ;
VAL_ 675 CF_AVN_BRAKE_PedalfeelNValueSet2 0 "Default" 1 "Normal" 2 "Sport" 3 "Chauffeur" 4 "Reserved" 5 "Reserved" 6 "Reserved" 7 "Invalid" ;
VAL_ 675 CF_AVN_ISLA_AutoNModSet 0 "Default" 1 "Off" 2 "On" 3 "Invalid(Gray)" ;
VAL_ 675 CF_AVN_HtBlcRRNValueSet 0 "Default" 1 "Normal" 2 "Back 1" 3 "Back 2" 4 "Back 3" 5 "Cush 1" 6 "Cush 2" 7 "Cush 3" 8 "Reserved" 9 "Reserved" 10 "Reserved" 11 "Reserved" 12 "Reserved" 13 "Reserved" 14 "Reserved" 15 "Invalid" ;
VAL_ 675 LapTimer_AutoMeasure_Setting 0 "default" 1 "off" 2 "on (auto-measure)" 3 "invalid" ;
VAL_ 675 LapTimer_TimeGap_Setting 0 "default" 1 "compare with best lap" 2 "compare with last lap" 3 "invalid" ;
VAL_ 675 Usm_RpmSANDSet 0 "Default" 1 "Off" 2 "On(RPM Gauge Display)" 3 "Invalid" ;
VAL_ 675 CF_AVN_RemoteWDWNValueSet 0 "Default" 1 "Disable (Off)" 2 "Enable (On)" 3 "Invalid" ;
VAL_ 675 USM_TowWeight_Set 0 "Default" 1 "Off" 2 "Auto" 3 "Small" 4 "Medium" 5 "Maximum" 6 "Reserved" 7 "Reserved" 8 "Reserved" 9 "Reserved" 10 "Reserved" 11 "Reserved" 12 "Reserved" 13 "Reserved" 14 "Reserved" 15 "Invalid" ;
VAL_ 675 CF_AVN_SportHUD2 0 "Default" 1 "Off(Normal)" 2 "Sport HUD" 3 "Invalid" ;
VAL_ 675 C_SLB_SmartCtrl_Set_Nvalue 0 "Init" 1 "Off" 2 "10min" 3 "20min" 4 "30min" 5 "40min" 6 "50min" 7 "60min" 8 "Unused" 9 "Unused" 10 "Unused" 11 "Unused" 12 "Unused" 13 "Unused" 14 "Unused" 15 "Invalid" ;
VAL_ 675 HU_CustomNewMenuSet 0 "Default" 1 "MY Drive Mode (Custom)" 2 "Smart (Custom)" 3 "Baby (Custom)" 4 "Retro(Custom)" 5 "Snow(CUSTOM) - Not Terrain" 6 "Comfort(Rear) - Custom" 7 "Reserved" 8 "Reserved" 9 "Reserved" 10 "Reserved" 11 "Reserved" 12 "Reserved" 13 "Reserved" 14 "Off(Custom)" 15 "Invalid" ;
VAL_ 675 USM_RpmComfortRearSet 0 "Default (Not configured)" 1 "Off" 2 "On (Display RPM guage)" 3 "Invalid" ;
VAL_ 675 Usm_RpmMyDriveModeSet 0 "Default" 1 "Off" 2 "On(RPM Gauge Display)" 3 "Invalid" ;
VAL_ 675 LapTimer_MeasuringStatus_HU 0 "Default" 1 "Start Lap Timer request" 2 "Stop/Reset Lap Timer request" 3 "RESERVED" 4 "RESERVED" 5 "RESERVED" 6 "RESERVED" 7 "Invalid" ;
VAL_ 675 CF_AVN_PCA_RrEquipNvalueSet 0 "Default" 1 "Off" 2 "On" 3 "Invalid(Gray)" ;
VAL_ 579 OHCL_Opt 0 "None option" 1 "Enable" ;
VAL_ 579 OHCL_Sys_sta 0 "Normal" 1 "Not Used" 2 "Not Used" 3 "System Fail" ;
VAL_ 579 OHCL_DoorOn_Sta 0 "Off" 1 "On" 2 "Not Used" 3 "System Fail" ;
VAL_ 579 OHCL_RrMapLftOn_Sta 0 "Off" 1 "On" 2 "Not Used" 3 "System Fail" ;
VAL_ 579 OHCL_RrMapRtOn_Sta 0 "Off" 1 "On" 2 "Not Used" 3 "System Fail" ;
VAL_ 579 OHCL_RrRoomOn_Sta 0 "Off" 1 "On" 2 "Not Used" 3 "System Fail" ;
VAL_ 579 OHCL_RrMoodOn_Sta 0 "Off" 1 "On" 2 "Not Used" 3 "System Fail" ;
VAL_ 579 OHCL_LEDClr_Sta 0 "Color 1Step" 1 "Color 2Step" 2 "Color 3Step" 3 "Not Used" 4 "Not Used" 5 "Not Used" 6 "Not Used" 7 "System Fail" ;
VAL_ 579 OHCL_LEDBgtns_Sta 0 "Brightness 1Step" 1 "Brightness 2Step" 2 "Brightness 3Step" 3 "Not Used" 4 "Not Used" 5 "Not Used" 6 "Not Used" 7 "System Fail" ;
VAL_ 579 OHCL_TllTlLmpSta 0 "ON Lamp off OFF Lamp off" 1 "ON Lamp off OFF Lamp on" 2 "ON Lamp on OFF Lamp off" 3 "ON Lamp on OFF Lamp on" 4 "ACU message error" 5 "Not Supported" 6 "Reserved" 7 "Lamp circuit failure" ;
VAL_ 579 OHCL_FrMapLftOn_Sta 0 "Off" 1 "On" 2 "Not Used" 3 "System Fail" ;
VAL_ 579 OHCL_RrCurtainReq 0 "Off" 1 "On" 2 "NotUsed" 3 "ErrorIndicator" ;
VAL_ 579 OHCL_FrMapRtOn_Sta 0 "Off" 1 "On" 2 "Not Used" 3 "System Fail" ;
VAL_ 579 OHCL_FrRoomOn_Sta 0 "Off" 1 "On" 2 "Not Used" 3 "System Fail" ;
VAL_ 579 OHCL_FrMoodOn_Sta 0 "Off" 1 "On" 2 "Not Used" 3 "System Fail" ;
VAL_ 632 PSS_RR_AstHRestFwdMvBtn 0 "Default" 1 "Off" 2 "On" 3 "Invalid" ;
VAL_ 632 PSS_RR_AstRclBwdMvBtn 0 "Default" 1 "Off" 2 "On" 3 "Invalid" ;
VAL_ 632 PSS_RR_AstSldFwdMvBtn 0 "Default" 1 "Off" 2 "On" 3 "Invalid" ;
VAL_ 632 PSS_RR_AstSldBwdMvBtn 0 "Default" 1 "Off" 2 "On" 3 "Invalid" ;
VAL_ 632 PSS_RR_AstHgtUpMvBtn 0 "Default" 1 "Off" 2 "On" 3 "Invalid" ;
VAL_ 632 PSS_RR_AstHgtDnMvBtn 0 "Default" 1 "Off" 2 "On" 3 "Invalid" ;
VAL_ 632 PSS_RR_AstHRestBwdMvBtn 0 "Default" 1 "Off" 2 "On" 3 "Invalid" ;
VAL_ 632 PSS_RR_AstFRestOpenMvBtn 0 "Default" 1 "Off" 2 "On" 3 "Invalid" ;
VAL_ 632 PSS_RR_AstFRestCloseMvBtn 0 "Default" 1 "Off" 2 "On" 3 "Invalid" ;
VAL_ 632 PSS_RR_AstHRestUpMvBtn 0 "Default" 1 "Off" 2 "On" 3 "Invalid" ;
VAL_ 632 PSS_RR_AstHRestDnMvBtn 0 "Default" 1 "Off" 2 "On" 3 "Invalid" ;
VAL_ 632 PSS_RR_AstRclFwdMvBtn 0 "Default" 1 "Off" 2 "On" 3 "Invalid" ;
VAL_ 681 AVN_SeatPosMemory_Cmd 0 "Default" 1 "memory 1" 2 "memory 2" 3 "memory 3" 4 "Not Used" 5 "Not Used" 6 "Not Used" 7 "Error Indicator" ;
VAL_ 681 RLPSM_RearModeWngDis 0 "Default" 1 "Mode-Fail (Not Initialized)" 2 "Reserved" 3 "Reserved" 4 "Reserved" 5 "Reserved" 6 "Reserved" 7 "Invaild" ;
VAL_ 681 RLIMS_AMPBzrReq 0 "Off" 1 "On" 2 "Not Used" 3 "Error Indicator" ;
VAL_ 681 RLPSM_Warn_CnslLmt 0 "Off" 1 "On" 2 "Not Used" 3 "Error Indicator" ;
VAL_ 681 AVN_SeatPosPlyBck_Cmd 0 "Default" 1 "memory 1" 2 "memory 2" 3 "memory 3" 4 "Not Used" 5 "Not Used" 6 "Stop" 7 "Error Indicator" ;
VAL_ 599 RRIMS_AMPBzrReq 0 "Off" 1 "On" 2 "Not Used" 3 "Error Indicator" ;
VAL_ 599 RRPSM_RearModeWngDis 0 "Default" 1 "Relax Mode(Rear Only)" 2 "Return Mode(Rear Only)" 3 "One Touch  Mode-Fail (Ast Seated)" 4 "Mode-Fail (Not Initialized)" 5 "Inhibit Rear IMS" 6 "AST seated && FootRest Open" 7 "Invaild" ;
VAL_ 2160080129 VCU_Crc1Val 0 "0x0x0~0xFFFF:CRCValue" 65535 "0x0x0~0xFFFF:CRCValue" ;
VAL_ 2160080129 VCU_AlvCnt1Val 0 "0x0x0~0xFF:AlvCntValue" 255 "0x0x0~0xFF:AlvCntValue" ;
VAL_ 2160080129 VCU_RdySta 0 "None" 1 "VCU Control Board Ready" 2 "Not used" 3 "Error Indicator" ;
VAL_ 2160080129 VCU_StartKeyHoldSta 0 "None" 1 "Start" 2 "Not used" 3 "Error Indicator" ;
VAL_ 2160080129 VCU_EvDrvRdySta 0 "None" 1 "EV Drivable" 2 "Not used" 3 "Error Indicator" ;
VAL_ 2160080129 VCU_MotPwrEnReq 0 "None" 1 "Allow Motor System to Control" 2 "Not used" 3 "Error Indicator" ;
VAL_ 2160080129 VCU_GearPosSta 0 "P" 1 "B" 2 "Not Used" 3 "Not Used" 4 "Not Used" 5 "D" 6 "N" 7 "R" 8 "Not Used" 9 "Not Display at Cluster" 10 "Reserved" 11 "Reserved" 12 "Reserved" 13 "Reserved" 14 "Intermediate Position" 15 "Fault" ;
VAL_ 2160080129 VCU_LdcInhReq 0 "None" 1 "LDC Off Request" 2 "Not used" 3 "Error Indicator" ;
VAL_ 2160080129 VCU_MainRlyOffReq 0 "None" 1 "Relay Cut Off" 2 "Not used" 3 "Error Indicator" ;
VAL_ 2160080129 VCU_AccPedDepVal 255 "Error Indicator" ;
VAL_ 2160080129 VCU_FatcOperPermSta 0 "Not Permiited" 1 "Permitted" 2 "Not used" 3 "Error Indicator" ;
VAL_ 2160080129 VCU_DrvCycSta 0 "No Driving Cycle Active" 1 "Driving Cycle Active" 2 "Not used" 3 "Error Indicator" ;
VAL_ 2160080129 VCU_CltActOpSta 0 "Neutral" 1 "Actuating" 2 "In Gear" 3 "Referencing" 4 "Fault" ;
VAL_ 2160080129 VCU_WhlSpdSnsrAlvReq 0 "No Request" 1 "Alive Request" 2 "Not used" 3 "Error Indicator" ;
VAL_ 2160080129 VCU_DrvModOpSta 0 "Eco" 1 "Normal" 2 "Sport" 3 "Reserved" 4 "Reserved" 5 "Snow" 6 "Sand" 7 "Mud" 8 "Reserved" 9 "Reserved" 10 "Reserved" 11 "Reserved" 12 "Reserved" 13 "Reserved" 14 "Reserved" 15 "Reserved" ;
VAL_ 2160080129 VCU_HydBrkFcHoldRq 0 "None" 1 "Hold Request" 2 "Reserved" 3 "Error" ;
VAL_ 2160080130 VCU_McuAntiJerkInhFrntSta 0 "Anti-jerk Not Inhibit" 1 "Anti-jerk Inhibit" 2 "Not used" 3 "Error Indicator" ;
VAL_ 2160080130 VCU_McuAntiJerkInhRearSta 0 "Anti-jerk Not Inhibit" 1 "Anti-jerk Inhibit" 2 "Not used" 3 "Error Indicator" ;
VAL_ 2160080130 VCU_McuPwrLatchHoldReq 0 "No Request" 1 "Power Latch Hold Request" 2 "Not used" 3 "Error Indicator" ;
VAL_ 2160080130 VCU_ScuParkReq 0 "Wait Command" 1 "Not used" 2 "Parking Command" 3 "Not Parking Command" ;
VAL_ 2160080130 VCU_ScuKeepWakeReq 0 "None" 1 "Keep Wake Request" 2 "Not used" 3 "Error Indicator" ;
VAL_ 2160080130 VCU_FmcuZeroTqOfsReq 0 "No Request" 1 "Request" 2 "Not used" 3 "Error Indicator" ;
VAL_ 2160080131 VCU_EcmSeqSta 0 "IG Off" 1 "IG On_PowerLatch" 2 "IG On Init" 3 "IG On_Rdy" 4 "IG On_Drivalble" 5 "IG On_PD" 6 "IGON_NonDrivable" ;
VAL_ 2160080131 VCU_MainBattTypeSta 0 "Short Range Type" 1 "Standard Range Type" 2 "Long Range Type" 3 "Not Used" ;
VAL_ 2160080131 VCU_MainBattTypeLrnSta 0 "Unlearnt" 1 "Learnt" 2 "Not used" 3 "Error Indicator" ;
VAL_ 2160080131 VCU_WarmupCycSta 0 "None" 1 "Warm-up Cycle Completed" 2 "Not used" 3 "Error Indicator" ;
VAL_ 2160080132 VCU_GearPosStaDisp 0 "P" 1 "B" 2 "Not Used" 3 "Not Used" 4 "Not Used" 5 "D" 6 "N" 7 "R" 8 "Not Used" 9 "Not Display at Cluster" 10 "Reserved" 11 "Reserved" 12 "Manual Shift Mode on Retromode" 13 "Reserved" 14 "Intermediate Position" 15 "Fault" ;
VAL_ 2160080132 VCU_PMPDActSta 0 "Off" 1 "PMPD ON - Torque Limitation" 2 "PMPD ON - Brake Act" 3 "PMPD Inactive" ;
VAL_ 2160080132 VCU_PdwLmtBrkRequest 0 "Off" 1 "On" 2 "Reserved" 3 "Reserved" ;
VAL_ 2160080132 VCU_VgsVirSoundBackFireIndex 0 "No Action Status" 1 "Tip-Out Back Fire Lv1 ~ Lv8" 2 "Tip-Out Back Fire Lv1 ~ Lv8" 3 "Tip-Out Back Fire Lv1 ~ Lv8" 4 "Tip-Out Back Fire Lv1 ~ Lv8" 5 "Tip-Out Back Fire Lv1 ~ Lv8" 6 "Tip-Out Back Fire Lv1 ~ Lv8" 7 "Tip-Out Back Fire Lv1 ~ Lv8" 8 "Tip-Out Back Fire Lv1 ~ Lv8" 17 "Bubbling Sound Lv1 ~ Lv8" 18 "Bubbling Sound Lv1 ~ Lv8" 19 "Bubbling Sound Lv1 ~ Lv8" 20 "Bubbling Sound Lv1 ~ Lv8" 21 "Bubbling Sound Lv1 ~ Lv8" 22 "Bubbling Sound Lv1 ~ Lv8" 23 "Bubbling Sound Lv1 ~ Lv8" 24 "Bubbling Sound Lv1 ~ Lv8" 9 "Upshift BANG Sound Lv1 ~ Lv8" 10 "Upshift BANG Sound Lv1 ~ Lv8" 11 "Upshift BANG Sound Lv1 ~ Lv8" 12 "Upshift BANG Sound Lv1 ~ Lv8" 13 "Upshift BANG Sound Lv1 ~ Lv8" 14 "Upshift BANG Sound Lv1 ~ Lv8" 15 "Upshift BANG Sound Lv1 ~ Lv8" 16 "Upshift BANG Sound Lv1 ~ Lv8" ;
VAL_ 2160080132 VCU_VgsVirEngSpdRpmVal 0 "0x0x0~0x7FFE:RPM" 32766 "0x0x0~0x7FFE:RPM" 32767 "Error Indicator" ;
VAL_ 2160080132 VCU_PdlStopCtrlSta 0 "No Request" 1 "Target brake torque control request" 2 "AVH request" 3 "AVH working" ;
VAL_ 2160080132 VCU_VgsVirSoundVolume 0 "0x0x0~0xFE:0~100%" 254 "0x0x0~0xFE:0~100%" 0 "0x0~0xFF:Invalid Error" 255 "0x0~0xFF:Invalid Error" ;
VAL_ 2160080132 VCU_VgsVirGearStep 0 "Not Used" 1 "1gear" 2 "2gear" 3 "3gear" 4 "4gear" 5 "5gear" 6 "6gear" 7 "7gear" 8 "8gear" 9 "Reserved" 10 "Reserved" 11 "Reserved" 12 "Reserved" 13 "Reserved" 14 "Reserved" 15 "Reserved" ;
VAL_ 2160080132 VCU_PdlStopReqTqNmVal 0 "0x0x0~0xFFFF:Request brake torque for stop assist control" 65535 "0x0x0~0xFFFF:Request brake torque for stop assist control" ;
VAL_ 2160080132 VCU_StandbyModSta 0 "Standby Mode Off" 1 "Standby Mode without HV Request" 2 "Standby Mode with HV Request" 3 "RESERVED" ;
